VERSION "HNNBNNNYNNNNNNNNNNNNNNNNNNNNNNNNNNNNNNNNNN/4/%%%/4/'%**4NNN///"

NS_ :

BS_:

BU_: BAP_Tester BedienDisp_vo BedienSG_hi CGS DDA Gateway Gateway_PAG GurtMikrofon OTA_FC ZR_High ZR_LIMU ZR_MIB_TOP_ab_Gen3 ZR_Standard

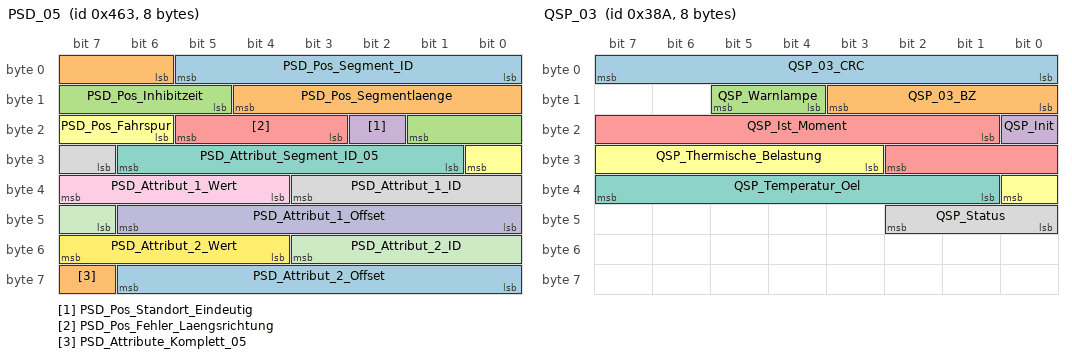
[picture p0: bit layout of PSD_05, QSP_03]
BO_ 1123 PSD_05: 8 ZR_High
 SG_ PSD_Pos_Segment_ID : 0|6@1+ (1,0) [2|63] ""  Gateway,Gateway_PAG
 SG_ PSD_Pos_Segmentlaenge : 6|7@1+ (2,0) [0|254] "Unit_Meter"  Gateway,Gateway_PAG
 SG_ PSD_Pos_Inhibitzeit : 13|5@1+ (10,0) [0|310] "Unit_MilliSecon"  Gateway,Gateway_PAG
 SG_ PSD_Pos_Standort_Eindeutig : 18|1@1+ (1.0,0.0) [0.0|1] ""  Gateway,Gateway_PAG
 SG_ PSD_Pos_Fehler_Laengsrichtung : 19|3@1+ (1.0,0.0) [0.0|7] ""  Gateway,Gateway_PAG
 SG_ PSD_Pos_Fahrspur : 22|3@1+ (1.0,0.0) [0.0|7] ""  Gateway,Gateway_PAG,OTA_FC
 SG_ PSD_Attribut_Segment_ID_05 : 25|6@1+ (1,0) [2|63] ""  Gateway,Gateway_PAG
 SG_ PSD_Attribut_1_ID : 31|5@1+ (1,0) [1|31] ""  Gateway,Gateway_PAG
 SG_ PSD_Attribut_1_Wert : 36|4@1+ (1.0,0.0) [0.0|15] ""  Gateway,Gateway_PAG
 SG_ PSD_Attribut_1_Offset : 40|7@1+ (2,0) [0|254] "Unit_Meter"  Gateway,Gateway_PAG
 SG_ PSD_Attribut_2_ID : 47|5@1+ (1,0) [1|31] ""  Gateway,Gateway_PAG
 SG_ PSD_Attribut_2_Wert : 52|4@1+ (1.0,0.0) [0.0|15] ""  Gateway,Gateway_PAG
 SG_ PSD_Attribut_2_Offset : 56|7@1+ (2,0) [0|254] "Unit_Meter"  Gateway,Gateway_PAG
 SG_ PSD_Attribute_Komplett_05 : 63|1@1+ (1.0,0.0) [0.0|1] ""  Gateway,Gateway_PAG

BO_ 1124 PSD_06: 8 ZR_High
 SG_ PSD_06_Mux M  : 0|3@1+ (1.0,0.0) [0.0|7] ""  Gateway,Gateway_PAG
 SG_ PSD_Sys_Segment_ID m0  : 3|6@1+ (1,0) [2|63] ""  Gateway,Gateway_PAG
 SG_ PSD_Attribut_Segment_ID m1  : 3|6@1+ (1,0) [2|63] ""  Gateway,Gateway_PAG
 SG_ PSD_Ges_Segment_ID m2  : 3|6@1+ (1,0) [2|63] ""  Gateway,Gateway_PAG
 SG_ PSD_Baum_Laenge_VZ m3  : 3|1@1+ (1.0,0.0) [0.0|1] ""  Gateway,Gateway_PAG
 SG_ PSD_Steigung_1_Segment_ID m4  : 3|6@1+ (1,0) [2|63] ""  Gateway,Gateway_PAG
 SG_ PSD_Baum_Laenge m3  : 4|25@1+ (0.00001,0) [0.00000|180.00000] "Unit_DegreOfArc"  Gateway,Gateway_PAG
 SG_ PSD_Sys_Laendercode m0  : 9|8@1+ (1.0,0.0) [0.0|255] ""  Gateway,Gateway_PAG
 SG_ PSD_Attribut_3_ID m1  : 9|5@1+ (1,0) [1|31] ""  Gateway,Gateway_PAG
 SG_ PSD_Ges_Offset m2  : 9|7@1+ (2,0) [0|254] "Unit_Meter"  Gateway,Gateway_PAG
 SG_ PSD_Steigung_1_A_Steigung m4  : 9|7@1+ (0.12,0) [0.00|15.00] "Unit_PerCent"  Gateway,Gateway_PAG
 SG_ PSD_Attribut_3_Offset m1  : 14|7@1+ (2,0) [0|254] "Unit_Meter"  Gateway,Gateway_PAG
 SG_ PSD_Ges_Geschwindigkeit m2  : 16|5@1+ (1.0,0.0) [0.0|31] ""  Gateway,Gateway_PAG,OTA_FC
 SG_ PSD_Steigung_1_A_Vorz m4  : 16|1@1+ (1.0,0.0) [0.0|1] ""  Gateway,Gateway_PAG
 SG_ PSD_Sys_Geschwindigkeit_Einheit m0  : 17|1@1+ (1.0,0.0) [0.0|1] ""  Gateway,Gateway_PAG
 SG_ PSD_Steigung_1_A_Offset m4  : 17|7@1+ (2,0) [0|254] "Unit_Meter"  Gateway,Gateway_PAG
 SG_ PSD_Sys_Verkehrsrichtung m0  : 18|1@1+ (1.0,0.0) [0.0|1] ""  Gateway,Gateway_PAG
 SG_ PSD_Sys_Geometrieguete m0  : 19|2@1+ (1.0,0.0) [0.0|3] ""  Gateway,Gateway_PAG
 SG_ PSD_Sys_Mapmatchingguete m0  : 21|2@1+ (1.0,0.0) [0.0|3] ""  Gateway,Gateway_PAG
 SG_ PSD_Attribut_3_Wert m1  : 21|4@1+ (1.0,0.0) [0.0|15] ""  Gateway,Gateway_PAG
 SG_ PSD_Ges_Typ m2  : 21|2@1+ (1.0,0.0) [0.0|3] ""  Gateway,Gateway_PAG
 SG_ PSD_Sys_Alter_Karte m0  : 23|3@1+ (1.0,0.0) [0.0|7] ""  Gateway,Gateway_PAG
 SG_ PSD_Ges_Spur_Geschw_Begrenzung m2  : 23|6@1+ (1.0,0.0) [0.0|63] ""  Gateway,Gateway_PAG
 SG_ PSD_Steigung_1_B_Steigung m4  : 24|7@1+ (0.12,0) [0.00|15.00] "Unit_PerCent"  Gateway,Gateway_PAG
 SG_ PSD_Attribut_4_ID m1  : 25|5@1+ (1,0) [1|31] ""  Gateway,Gateway_PAG
 SG_ PSD_Sys_Zielfuehrung m0  : 26|1@1+ (1.0,0.0) [0.0|1] ""  Gateway,Gateway_PAG,OTA_FC
 SG_ PSD_Sys_US_State m0  : 27|6@1+ (1.0,0.0) [0.0|63] ""  Gateway,Gateway_PAG
 SG_ PSD_Ges_Geschwindigkeit_Gespann m2  : 29|2@1+ (1.0,0.0) [0.0|3] ""  Gateway,Gateway_PAG
 SG_ PSD_Baum_Breite_VZ m3  : 29|1@1+ (1.0,0.0) [0.0|1] ""  Gateway,Gateway_PAG
 SG_ PSD_Attribut_4_Wert m1  : 30|4@1+ (1,0) [0|15] ""  Gateway,Gateway_PAG
 SG_ PSD_Baum_Breite m3  : 30|24@1+ (0.00001,0) [0.00000|90.00000] "Unit_DegreOfArc"  Gateway,Gateway_PAG
 SG_ PSD_Ges_Geschwindigkeit_Witter m2  : 31|2@1+ (1.0,0.0) [0.0|3] ""  Gateway,Gateway_PAG
 SG_ PSD_Steigung_1_B_Vorz m4  : 31|1@1+ (1.0,0.0) [0.0|1] ""  Gateway,Gateway_PAG
 SG_ PSD_Steigung_1_B_Offset m4  : 32|7@1+ (2,0) [0|254] "Unit_Meter"  Gateway,Gateway_PAG
 SG_ PSD_Sys_Quali_Geometrien m0  : 33|3@1+ (1,0) [0|7] "Unit_None"  Gateway,Gateway_PAG
 SG_ PSD_Ges_Geschwindigkeit_Tag_Anf m2  : 33|3@1+ (1.0,0.0) [0.0|7] ""  Gateway,Gateway_PAG
 SG_ PSD_Attribut_4_Offset m1  : 34|7@1+ (2,0) [0|254] "Unit_Meter"  Gateway,Gateway_PAG
 SG_ PSD_Sys_Quali_Ortsinfo m0  : 36|2@1+ (1,0) [0|3] "Unit_None"  Gateway,Gateway_PAG
 SG_ PSD_Ges_Geschwindigkeit_Tag_Ende m2  : 36|3@1+ (1.0,0.0) [0.0|7] ""  Gateway,Gateway_PAG
 SG_ PSD_Sys_Quali_verfuegbar m0  : 38|1@1+ (1.0,0.0) [0.0|1] ""  Gateway,Gateway_PAG
 SG_ PSD_Sys_Zielfuehrung_geaendert m0  : 39|1@1+ (1.0,0.0) [0.0|1] ""  Gateway,Gateway_PAG
 SG_ PSD_Ges_Geschwindigkeit_Std_Anf m2  : 39|5@1+ (1,0) [0|24] "Unit_Hours"  Gateway,Gateway_PAG
 SG_ PSD_Steigung_1_Attribute_kompl m4  : 39|1@1+ (1.0,0.0) [0.0|1] ""  Gateway,Gateway_PAG
 SG_ PSD_Sys_Geometrieguete_erweitert m0  : 40|8@1+ (1.0,0.0) [0.0|255] ""  Gateway,Gateway_PAG
 SG_ PSD_Steigung_2_Segment_ID m4  : 40|6@1+ (1,0) [2|63] ""  Gateway,Gateway_PAG
 SG_ PSD_Attribut_5_ID m1  : 41|5@1+ (1,0) [1|31] ""  Gateway,Gateway_PAG
 SG_ PSD_Ges_Geschwindigkeit_Std_Ende m2  : 44|5@1+ (1,0) [0|24] "Unit_Hours"  Gateway,Gateway_PAG
 SG_ PSD_Attribut_5_Offset m1  : 46|7@1+ (2,0) [0|254] "Unit_Meter"  Gateway,Gateway_PAG
 SG_ PSD_Steigung_2_Steigung m4  : 46|7@1+ (0.12,0) [0.00|15.00] "Unit_PerCent"  Gateway,Gateway_PAG
 SG_ PSD_Sys_Quali_sonstige_Attribute m0  : 48|3@1+ (1,0) [0|7] "Unit_None"  Gateway,Gateway_PAG
 SG_ PSD_Ges_Ueberholverbot m2  : 49|2@1+ (1.0,0.0) [0.0|3] ""  Gateway,Gateway_PAG
 SG_ PSD_Sys_Quali_Steigungen m0  : 51|3@1+ (1,0) [0|7] ""  Gateway,Gateway_PAG
 SG_ PSD_Ges_Wechselverkehrszeichen m2  : 51|3@1+ (1.0,0.0) [0.0|7] ""  Gateway,Gateway_PAG
 SG_ PSD_Attribut_5_Wert m1  : 53|4@1+ (1,0) [0|15] ""  Gateway,Gateway_PAG
 SG_ PSD_Steigung_2_Vorz m4  : 53|1@1+ (1.0,0.0) [0.0|1] ""  Gateway,Gateway_PAG
 SG_ PSD_Sys_Quali_Strassenkennz m0  : 54|3@1+ (1,0) [0|7] "Unit_None"  Gateway,Gateway_PAG
 SG_ PSD_Wechselverkehrszeichen_Typ m2  : 54|2@1+ (1.0,0.0) [0.0|3] ""  Gateway,Gateway_PAG
 SG_ PSD_Baum_Ausrichtung m3  : 54|10@1+ (0.3515625,0) [0E-7|359.6484375] "Unit_DegreOfArc"  Gateway,Gateway_PAG
 SG_ PSD_Steigung_2_Offset m4  : 54|7@1+ (2,0) [0|254] "Unit_Meter"  Gateway,Gateway_PAG
 SG_ PSD_Ges_Gesetzlich_Kategorie m2  : 56|3@1+ (1.0,0.0) [0.0|7] ""  Gateway,Gateway_PAG
 SG_ PSD_Sys_Quali_Tempolimits m0  : 57|3@1+ (1,0) [0|7] "Unit_None"  Gateway,Gateway_PAG
 SG_ PSD_Attribute_Komplett_06 m1  : 57|1@1+ (1.0,0.0) [0.0|1] ""  Gateway,Gateway_PAG
 SG_ PSD_Ges_Gesetzlich_Zusatz m2  : 59|2@1+ (1.0,0.0) [0.0|3] ""  Gateway,Gateway_PAG
 SG_ PSD_Sys_Quali_Vorfahrtsregelung m0  : 60|3@1+ (1,0) [0|7] "Unit_None"  Gateway,Gateway_PAG
 SG_ PSD_Ges_Verkehrszeichen_Quelle m2  : 61|2@1+ (1.0,0.0) [0.0|3] ""  Gateway,Gateway_PAG
 SG_ PSD_Steigung_2_Attribute_kompl m4  : 61|1@1+ (1.0,0.0) [0.0|1] ""  Gateway,Gateway_PAG
 SG_ PSD_Ges_Attribute_Komplett m2  : 63|1@1+ (1.0,0.0) [0.0|1] ""  Gateway,Gateway_PAG

BO_ 1125 PSD_LR_01: 8 ZR_High
 SG_ PSD_LR_Profil_Nummer : 0|2@1+ (1,0) [0|3] ""  Gateway,Gateway_PAG
 SG_ PSD_LR_01_MUX M  : 2|2@1+ (1.0,0.0) [0.0|3] ""  Gateway,Gateway_PAG
 SG_ PSD_LR_Profil_Laenge m0  : 4|14@1+ (0.25,0) [0.00|4095.75] "Unit_KiloMeter"  Gateway,Gateway_PAG
 SG_ PSD_LR_Koeffizientensatz_Nr m1  : 4|6@1+ (1,0) [0|63] ""  Gateway,Gateway_PAG
 SG_ PSD_LR_Attribut_1_Offset m2  : 4|12@1+ (0.0244140625,0) [0E-10|99.9755859375] "Unit_PerCent"  Gateway,Gateway_PAG
 SG_ PSD_LR_Steigung_1_Offset m3  : 4|12@1+ (0.0244140625,0) [0E-10|99.9755859375] "Unit_PerCent"  Gateway,Gateway_PAG
 SG_ PSD_LR_Koeff_1_Amp m1  : 10|9@1+ (0.01956947162,0) [0E-11|9.99999999782] "Unit_PerCent"  Gateway,Gateway_PAG
 SG_ PSD_LR_Attribut_1_Wert m2  : 16|8@1+ (1.0,0.0) [0.0|255] ""  Gateway,Gateway_PAG
 SG_ PSD_LR_Steigung_1_Vorz m3  : 16|1@1+ (1.0,0.0) [0.0|1] ""  Gateway,Gateway_PAG
 SG_ PSD_LR_Steigung_1_Wert m3  : 17|7@1+ (0.12,0) [0.00|15.24] "Unit_PerCent"  Gateway,Gateway_PAG
 SG_ PSD_LR_Fahrzeug_Pos m0  : 18|14@1+ (0.006103888,0) [0E-9|99.999997104] "Unit_PerCent"  Gateway,Gateway_PAG
 SG_ PSD_LR_Koeff_1_Phase m1  : 19|9@1+ (0.0122958616,0) [0E-10|6.2831852776] "Unit_DegreOfArc"  Gateway,Gateway_PAG
 SG_ PSD_LR_Attribut_2_Offset m2  : 24|12@1+ (0.0244140625,0) [0E-10|99.9755859375] "Unit_PerCent"  Gateway,Gateway_PAG
 SG_ PSD_LR_Steigung_2_Offset m3  : 24|12@1+ (0.0244140625,0) [0E-10|99.9755859375] "Unit_PerCent"  Gateway,Gateway_PAG
 SG_ PSD_LR_Koeff_2_Amp m1  : 28|9@1+ (0.01956947162,0) [0E-11|9.99999999782] "Unit_PerCent"  Gateway,Gateway_PAG
 SG_ PSD_LR_Globale_Steigung_Vorz m0  : 32|1@1+ (1.0,0.0) [0.0|1] ""  Gateway,Gateway_PAG
 SG_ PSD_LR_Globale_Steigung m0  : 33|19@1+ (0.00002861028406197,0) [0E-17|14.99999999999806539] "Unit_PerCent"  Gateway,Gateway_PAG
 SG_ PSD_LR_Attribut_2_Wert m2  : 36|8@1+ (1.0,0.0) [0.0|255] ""  Gateway,Gateway_PAG
 SG_ PSD_LR_Steigung_2_Vorz m3  : 36|1@1+ (1.0,0.0) [0.0|1] ""  Gateway,Gateway_PAG
 SG_ PSD_LR_Koeff_2_Phase m1  : 37|9@1+ (0.0122958616,0) [0E-10|6.2831852776] "Unit_DegreOfArc"  Gateway,Gateway_PAG
 SG_ PSD_LR_Steigung_2_Wert m3  : 37|7@1+ (0.12,0) [0.00|15.24] "Unit_PerCent"  Gateway,Gateway_PAG
 SG_ PSD_LR_Attribut_3_Offset m2  : 44|12@1+ (0.0244140625,0) [0E-10|99.9755859375] "Unit_PerCent"  Gateway,Gateway_PAG
 SG_ PSD_LR_Steigung_3_Offset m3  : 44|12@1+ (0.0244140625,0) [0E-10|99.9755859375] "Unit_PerCent"  Gateway,Gateway_PAG
 SG_ PSD_LR_Koeff_3_Amp m1  : 46|9@1+ (0.01956947162,0) [0E-11|9.99999999782] "Unit_PerCent"  Gateway,Gateway_PAG
 SG_ PSD_LR_Max_Koeff_Amp m0  : 52|11@1+ (2,0) [0|4094] "Unit_Meter"  Gateway,Gateway_PAG
 SG_ PSD_LR_Koeff_3_Phase m1  : 55|9@1+ (0.0122958616,0) [0E-10|6.2831852776] "Unit_DegreOfArc"  Gateway,Gateway_PAG
 SG_ PSD_LR_Attribut_3_Wert m2  : 56|8@1+ (1.0,0.0) [0.0|255] ""  Gateway,Gateway_PAG
 SG_ PSD_LR_Steigung_3_Vorz m3  : 56|1@1+ (1.0,0.0) [0.0|1] ""  Gateway,Gateway_PAG
 SG_ PSD_LR_Steigung_3_Wert m3  : 57|7@1+ (0.12,0) [0.00|15.24] "Unit_PerCent"  Gateway,Gateway_PAG
 SG_ PSD_LR_Reset m0  : 63|1@1+ (1.0,0.0) [0.0|1] ""  Gateway,Gateway_PAG

BO_ 906 QSP_03: 8 Gateway
 SG_ QSP_03_CRC : 0|8@1+ (1,0) [0|255] ""  Vector__XXX
 SG_ QSP_03_BZ : 8|4@1+ (1,0) [0|15] ""  Vector__XXX
 SG_ QSP_Warnlampe : 12|2@1+ (1.0,0.0) [0.0|3] ""  ZR_High,ZR_MIB_TOP_ab_Gen3
 SG_ QSP_Init : 16|1@1+ (1.0,0.0) [0.0|1] ""  Vector__XXX
 SG_ QSP_Ist_Moment : 17|10@1+ (3,-1533) [-1533|1533] "Unit_NewtoMeter"  Vector__XXX
 SG_ QSP_Thermische_Belastung : 27|6@1+ (2,0) [0|100] "Unit_PerCent"  ZR_High,ZR_MIB_TOP_ab_Gen3
 SG_ QSP_Temperatur_Oel : 33|7@1+ (2,-40) [-40|210] "Unit_DegreCelsi"  ZR_High,ZR_MIB_TOP_ab_Gen3
 SG_ QSP_Status : 40|3@1+ (1.0,0.0) [0.0|7] ""  Vector__XXX

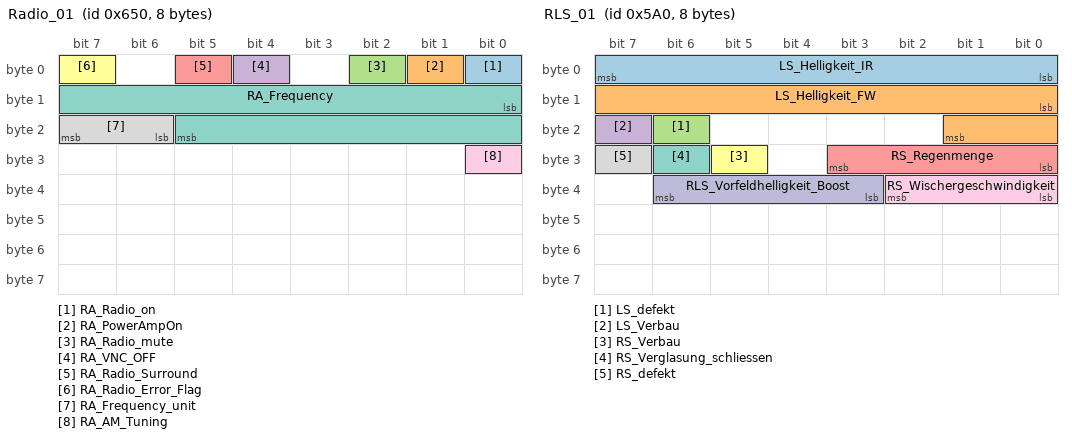
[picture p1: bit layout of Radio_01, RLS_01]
BO_ 1616 Radio_01: 8 ZR_High
 SG_ RA_Radio_on : 0|1@1+ (1,0) [0|1] ""  Gateway,Gateway_PAG
 SG_ RA_PowerAmpOn : 1|1@1+ (1,0) [0|1] ""  Gateway,Gateway_PAG
 SG_ RA_Radio_mute : 2|1@1+ (1,0) [0|1] ""  Gateway,Gateway_PAG
 SG_ RA_VNC_OFF : 4|1@1+ (1,0) [0|1] ""  Gateway,Gateway_PAG
 SG_ RA_Radio_Surround : 5|1@1+ (1,0) [0|1] ""  Gateway,Gateway_PAG
 SG_ RA_Radio_Error_Flag : 7|1@1+ (1.0,0.0) [0.0|1] ""  Gateway,Gateway_PAG
 SG_ RA_Frequency : 8|14@1+ (1,0) [0|16383] "Unit_None"  Gateway,Gateway_PAG
 SG_ RA_Frequency_unit : 22|2@1+ (1.0,0.0) [0.0|3] ""  Gateway,Gateway_PAG
 SG_ RA_AM_Tuning : 24|1@1+ (1.0,0.0) [0.0|1] ""  Gateway,Gateway_PAG

BO_ 1529 RDK_02: 8 Gateway
 SG_ RDK_FMVSS138_Lampe : 12|1@1+ (1.0,0.0) [0.0|1] ""  ZR_High
 SG_ RDK_FMVSS138_MIL : 13|1@1+ (1.0,0.0) [0.0|1] ""  ZR_High
 SG_ RDK_Kalibrierung : 14|1@1+ (1.0,0.0) [0.0|1] ""  Vector__XXX
 SG_ RDK_Reifendruck_Lampe : 15|1@1+ (1.0,0.0) [0.0|1] ""  OTA_FC,ZR_High
 SG_ RDK_Warnungen_02 : 16|5@1+ (1.0,0.0) [0.0|31] ""  ZR_High
 SG_ RDK_angelernt : 22|1@1+ (1.0,0.0) [0.0|1] ""  Vector__XXX
 SG_ RDK_Reifentemperatur_Lampe : 23|1@1+ (1.0,0.0) [0.0|1] ""  ZR_High
 SG_ RDK_RS_aktiv : 24|1@1+ (1.0,0.0) [0.0|1] ""  Vector__XXX
 SG_ RDK_Text_7 : 25|1@1+ (1.0,0.0) [0.0|1] ""  Vector__XXX
 SG_ RDK_W_1_Reifen_HL : 56|1@1+ (1.0,0.0) [0.0|1] ""  ZR_High
 SG_ RDK_W_1_Reifen_HR : 57|1@1+ (1.0,0.0) [0.0|1] ""  ZR_High
 SG_ RDK_W_1_Reifen_VL : 58|1@1+ (1.0,0.0) [0.0|1] ""  ZR_High
 SG_ RDK_W_1_Reifen_VR : 59|1@1+ (1.0,0.0) [0.0|1] ""  ZR_High
 SG_ RDK_W_2_Reifen_HL : 60|1@1+ (1.0,0.0) [0.0|1] ""  ZR_High
 SG_ RDK_W_2_Reifen_HR : 61|1@1+ (1.0,0.0) [0.0|1] ""  ZR_High
 SG_ RDK_W_2_Reifen_VL : 62|1@1+ (1.0,0.0) [0.0|1] ""  ZR_High
 SG_ RDK_W_2_Reifen_VR : 63|1@1+ (1.0,0.0) [0.0|1] ""  ZR_High

BO_ 1711 Rear_View_01: 8 Gateway
 SG_ RV_Video_on : 0|1@1+ (1.0,0.0) [0.0|1] ""  ZR_High,ZR_Standard
 SG_ RV_Dark_Screen : 1|1@1+ (1.0,0.0) [0.0|1] ""  ZR_High,ZR_Standard
 SG_ RV_HMI_Mode : 2|2@1+ (1.0,0.0) [0.0|3] ""  ZR_High,ZR_Standard
 SG_ RV_GL_side : 4|2@1+ (1.0,0.0) [0.0|3] ""  ZR_High,ZR_Standard
 SG_ RV_System_aktiv : 6|1@1+ (1.0,0.0) [0.0|1] ""  ZR_High,ZR_Standard
 SG_ RV_Reinigung_Anf : 7|1@1+ (1.0,0.0) [0.0|1] ""  OTA_FC,ZR_High
 SG_ RV_Settings_enabled : 8|1@1+ (1.0,0.0) [0.0|1] ""  ZR_High
 SG_ RV_Menu_Item : 9|2@1+ (1.0,0.0) [0.0|3] ""  ZR_High
 SG_ SV_Video_on : 11|1@1+ (1.0,0.0) [0.0|1] ""  ZR_High,ZR_Standard
 SG_ RV_Calib_Fehler : 12|1@1+ (1.0,0.0) [0.0|1] ""  ZR_High
 SG_ RV_GL_Trailer_connect : 13|1@1+ (1.0,0.0) [0.0|1] ""  ZR_High,ZR_Standard
 SG_ RV_GL_Trunk_open : 14|1@1+ (1.0,0.0) [0.0|1] ""  ZR_High,ZR_Standard
 SG_ RV_GL_LWS_Fehler : 15|1@1+ (1.0,0.0) [0.0|1] ""  ZR_High
 SG_ RV_Helligkeit : 16|7@1+ (1,0) [0|100] "Unit_PerCent"  ZR_High,ZR_Standard
 SG_ ZFAS_Umfeldbeleuchtung_Anf : 23|1@1+ (1.0,0.0) [0.0|1] ""  Vector__XXX
 SG_ RV_Kontrast : 24|7@1+ (1,0) [0|100] "Unit_PerCent"  ZR_High,ZR_Standard
 SG_ RV_Farbe : 32|7@1+ (1,0) [0|100] "Unit_PerCent"  ZR_High,ZR_Standard

BO_ 1440 RLS_01: 8 Gateway
 SG_ LS_Helligkeit_IR : 0|8@1+ (400,0) [0|101200] "Unit_Lux"  ZR_High
 SG_ LS_Helligkeit_FW : 8|10@1+ (6,0) [0|6126] "Unit_Lux"  ZR_High
 SG_ LS_defekt : 22|1@1+ (1.0,0.0) [0.0|1] ""  ZR_High
 SG_ LS_Verbau : 23|1@1+ (1.0,0.0) [0.0|1] ""  ZR_High
 SG_ RS_Regenmenge : 24|4@1+ (10,0) [0|100] "Unit_PerCent"  OTA_FC,ZR_High
 SG_ RS_Verbau : 29|1@1+ (1.0,0.0) [0.0|1] ""  ZR_High
 SG_ RS_Verglasung_schliessen : 30|1@1+ (1.0,0.0) [0.0|1] ""  ZR_High
 SG_ RS_defekt : 31|1@1+ (1.0,0.0) [0.0|1] ""  ZR_High
 SG_ RS_Wischergeschwindigkeit : 32|3@1+ (1.0,0.0) [0.0|7] ""  OTA_FC,ZR_High
 SG_ RLS_Vorfeldhelligkeit_Boost : 35|4@1+ (1.0,0.0) [0.0|15] ""  ZR_High

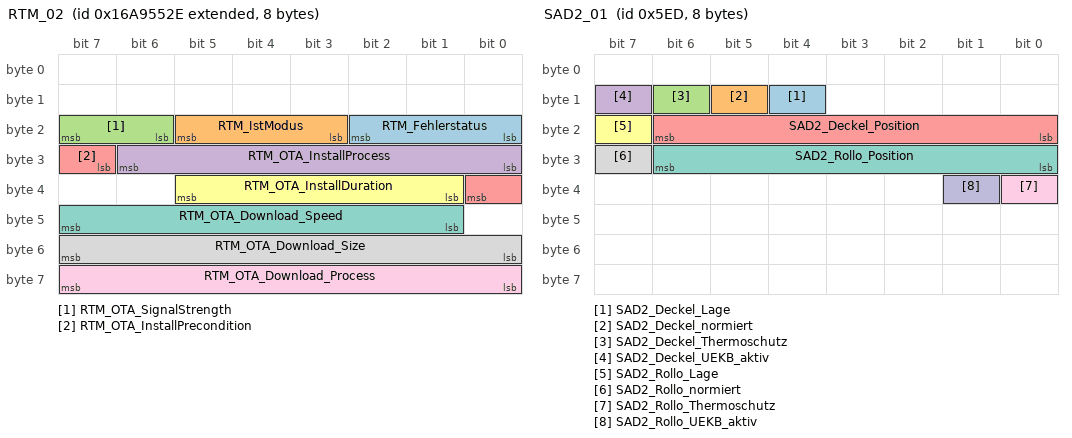
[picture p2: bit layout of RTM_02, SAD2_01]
BO_ 2527679790 RTM_02: 8 Gateway
 SG_ RTM_Fehlerstatus : 16|3@1+ (1.0,0.0) [0.0|7] ""  ZR_LIMU,ZR_MIB_TOP_ab_Gen3
 SG_ RTM_IstModus : 19|3@1+ (1.0,0.0) [0.0|7] ""  ZR_LIMU,ZR_MIB_TOP_ab_Gen3
 SG_ RTM_OTA_SignalStrength : 22|2@1+ (1.0,0.0) [0.0|3] ""  ZR_LIMU,ZR_MIB_TOP_ab_Gen3
 SG_ RTM_OTA_InstallProcess : 24|7@1+ (1,-1) [0|100] "Unit_PerCent"  ZR_LIMU,ZR_MIB_TOP_ab_Gen3
 SG_ RTM_OTA_InstallPrecondition : 31|2@1+ (1.0,0.0) [0.0|3] ""  ZR_LIMU,ZR_MIB_TOP_ab_Gen3
 SG_ RTM_OTA_InstallDuration : 33|5@1+ (1,0) [1|30] "Unit_Minut"  ZR_LIMU,ZR_MIB_TOP_ab_Gen3
 SG_ RTM_OTA_Download_Speed : 41|7@1+ (0.1,0) [0.1|12.5] ""  ZR_LIMU,ZR_MIB_TOP_ab_Gen3
 SG_ RTM_OTA_Download_Size : 48|8@1+ (1,1) [1|253] ""  ZR_LIMU,ZR_MIB_TOP_ab_Gen3
 SG_ RTM_OTA_Download_Process : 56|8@1+ (0.5,0) [0.0|100.0] "Unit_PerCent"  ZR_LIMU,ZR_MIB_TOP_ab_Gen3

BO_ 2527679791 RTM_03: 8 Gateway
 SG_ RTM_03_Dummy : 63|1@1+ (1.0,0.0) [0.0|1] ""  Vector__XXX

BO_ 2527679792 RTM_04: 8 ZR_LIMU
 SG_ MIB_OTA_Comfirmation : 12|3@1+ (1.0,0.0) [0.0|7] ""  Gateway,Gateway_PAG

BO_ 1517 SAD2_01: 8 Gateway
 SG_ SAD2_Deckel_Lage : 12|1@1+ (1.0,0.0) [0.0|1] ""  DDA
 SG_ SAD2_Deckel_normiert : 13|1@1+ (1.0,0.0) [0.0|1] ""  Vector__XXX
 SG_ SAD2_Deckel_Thermoschutz : 14|1@1+ (1.0,0.0) [0.0|1] ""  Vector__XXX
 SG_ SAD2_Deckel_UEKB_aktiv : 15|1@1+ (1.0,0.0) [0.0|1] ""  Vector__XXX
 SG_ SAD2_Deckel_Position : 16|7@1+ (1,0) [0|100] "Unit_PerCent"  DDA,OTA_FC
 SG_ SAD2_Rollo_Lage : 23|1@1+ (1.0,0.0) [0.0|1] ""  Vector__XXX
 SG_ SAD2_Rollo_Position : 24|7@1+ (1,0) [0|100] "Unit_PerCent"  Vector__XXX
 SG_ SAD2_Rollo_normiert : 31|1@1+ (1.0,0.0) [0.0|1] ""  Vector__XXX
 SG_ SAD2_Rollo_Thermoschutz : 32|1@1+ (1.0,0.0) [0.0|1] ""  Vector__XXX
 SG_ SAD2_Rollo_UEKB_aktiv : 33|1@1+ (1.0,0.0) [0.0|1] ""  Vector__XXX

BO_ 1504 SAD_01: 8 Gateway
 SG_ MD1_Position : 8|7@1+ (1,0) [0|100] "Unit_PerCent"  BedienDisp_vo,BedienSG_hi,DDA,OTA_FC,ZR_High,ZR_LIMU,ZR_MIB_TOP_ab_Gen3,ZR_Standard
 SG_ MD1_Lage : 15|1@1+ (1.0,0.0) [0.0|1] ""  BedienDisp_vo,BedienSG_hi,DDA,OTA_FC,ZR_High,ZR_LIMU,ZR_MIB_TOP_ab_Gen3,ZR_Standard
 SG_ MD3_Position : 16|7@1+ (1,0) [0|100] "Unit_PerCent"  BedienSG_hi,ZR_High,ZR_LIMU,ZR_MIB_TOP_ab_Gen3,ZR_Standard
 SG_ MD3_Lage : 23|1@1+ (1.0,0.0) [0.0|1] ""  BedienSG_hi,ZR_High,ZR_LIMU,ZR_MIB_TOP_ab_Gen3,ZR_Standard
 SG_ MRollo_Position : 24|7@1+ (1,0) [0|100] "Unit_PerCent"  BedienSG_hi,ZR_High
 SG_ MRollo_Lage : 31|1@1+ (1.0,0.0) [0.0|1] ""  BedienSG_hi,ZR_High
 SG_ SAD_normiert : 32|1@1+ (1.0,0.0) [0.0|1] ""  BedienSG_hi,ZR_High
 SG_ SAD_Thermoschutz : 33|1@1+ (1.0,0.0) [0.0|1] ""  BedienSG_hi,ZR_High
 SG_ SAD_UEKB_aktiv : 34|1@1+ (1.0,0.0) [0.0|1] ""  BedienSG_hi,ZR_High
 SG_ Rollo_normiert : 35|1@1+ (1.0,0.0) [0.0|1] ""  BedienSG_hi,ZR_High
 SG_ Rollo_Thermoschutz : 36|1@1+ (1.0,0.0) [0.0|1] ""  BedienSG_hi,ZR_High
 SG_ Rollo_UEKB_aktiv : 37|1@1+ (1.0,0.0) [0.0|1] ""  BedienSG_hi,ZR_High
 SG_ SAD_Taster_Deckel_hi : 38|4@1+ (1.0,0.0) [0.0|15] ""  ZR_High
 SG_ SAD_Taster_Deckel_vo : 42|4@1+ (1.0,0.0) [0.0|15] ""  ZR_High
 SG_ SAD_Taster_Rollo_hi : 46|3@1+ (1.0,0.0) [0.0|7] ""  ZR_High
 SG_ SAD_Taster_Rollo_vo : 49|3@1+ (1.0,0.0) [0.0|7] ""  Vector__XXX
 SG_ SAD_Anf_ESC_Zuschaltung : 52|1@1+ (1.0,0.0) [0.0|1] ""  Vector__XXX
 SG_ SAD_Text : 53|1@1+ (1.0,0.0) [0.0|1] ""  Vector__XXX
 SG_ SAD_ToggleBit : 54|1@1+ (1,0) [0|1] ""  Vector__XXX
 SG_ SAD_ParityBit : 55|1@1+ (1,0) [0|1] ""  Vector__XXX

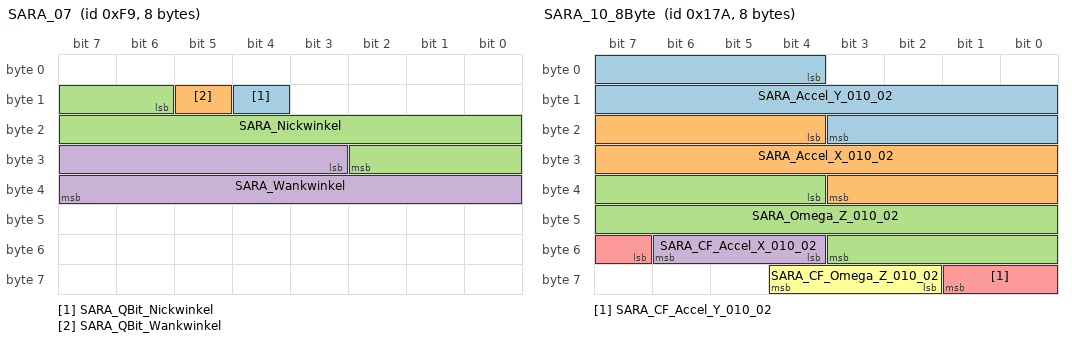
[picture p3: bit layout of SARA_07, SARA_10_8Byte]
BO_ 249 SARA_07: 8 Gateway
 SG_ SARA_QBit_Nickwinkel : 12|1@1+ (1.0,0.0) [0.0|1] ""  ZR_High,ZR_LIMU,ZR_MIB_TOP_ab_Gen3
 SG_ SARA_QBit_Wankwinkel : 13|1@1+ (1.0,0.0) [0.0|1] ""  ZR_High,ZR_LIMU,ZR_MIB_TOP_ab_Gen3
 SG_ SARA_Nickwinkel : 14|13@1+ (0.025,-102.3) [-102.300|102.450] "Unit_DegreOfArc"  ZR_High,ZR_LIMU,ZR_MIB_TOP_ab_Gen3
 SG_ SARA_Wankwinkel : 27|13@1+ (0.025,-102.3) [-102.300|102.450] "Unit_DegreOfArc"  ZR_High,ZR_LIMU,ZR_MIB_TOP_ab_Gen3

BO_ 378 SARA_10_8Byte: 8 Gateway
 SG_ SARA_Accel_Y_010_02 : 4|16@1+ (0.02,-655.36) [-655.34|655.32] "Unit_MeterPerSeconSquar"  ZR_High,ZR_LIMU,ZR_MIB_TOP_ab_Gen3
 SG_ SARA_Accel_X_010_02 : 20|16@1+ (0.02,-655.36) [-655.34|655.32] "Unit_MeterPerSeconSquar"  ZR_High,ZR_LIMU,ZR_MIB_TOP_ab_Gen3
 SG_ SARA_Omega_Z_010_02 : 36|16@1+ (0.01,-327.68) [-327.67|327.66] "Unit_DegreOfArcPerSecon"  ZR_LIMU,ZR_MIB_TOP_ab_Gen3
 SG_ SARA_CF_Accel_X_010_02 : 52|3@1+ (1.0,0.0) [0.0|7] ""  ZR_High,ZR_LIMU,ZR_MIB_TOP_ab_Gen3
 SG_ SARA_CF_Accel_Y_010_02 : 55|3@1+ (1.0,0.0) [0.0|7] ""  ZR_High,ZR_LIMU,ZR_MIB_TOP_ab_Gen3
 SG_ SARA_CF_Omega_Z_010_02 : 58|3@1+ (1.0,0.0) [0.0|7] ""  ZR_LIMU,ZR_MIB_TOP_ab_Gen3

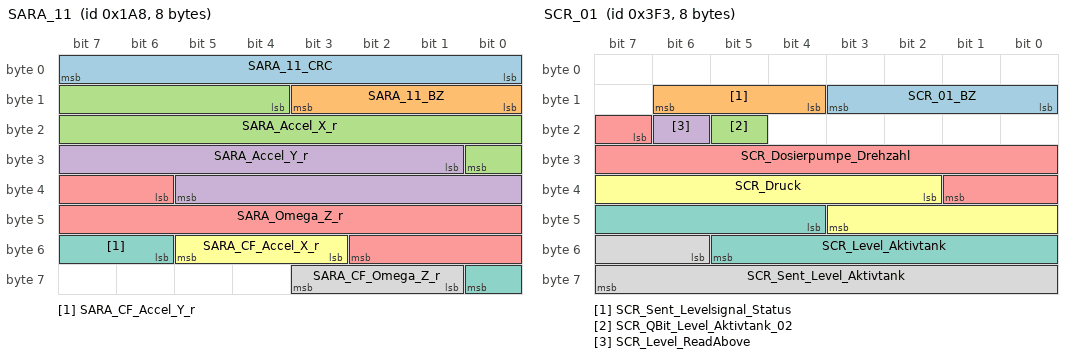
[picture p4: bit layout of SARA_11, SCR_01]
BO_ 424 SARA_11: 8 Gateway
 SG_ SARA_11_CRC : 0|8@1+ (1,0) [0|255] ""  Vector__XXX
 SG_ SARA_11_BZ : 8|4@1+ (1,0) [0|15] ""  Vector__XXX
 SG_ SARA_Accel_X_r : 12|13@1+ (0.16,-655.36) [-655.20|655.04] "Unit_MeterPerSeconSquar"  OTA_FC,ZR_High,ZR_LIMU,ZR_MIB_TOP_ab_Gen3,ZR_Standard
 SG_ SARA_Accel_Y_r : 25|13@1+ (0.16,-655.36) [-655.20|655.04] "Unit_MeterPerSeconSquar"  OTA_FC,ZR_High,ZR_LIMU,ZR_MIB_TOP_ab_Gen3,ZR_Standard
 SG_ SARA_Omega_Z_r : 38|13@1+ (0.08,-327.68) [-327.60|327.52] "Unit_DegreOfArcPerSecon"  ZR_High,ZR_LIMU,ZR_MIB_TOP_ab_Gen3,ZR_Standard
 SG_ SARA_CF_Accel_X_r : 51|3@1+ (1.0,0.0) [0.0|7] ""  ZR_High,ZR_LIMU,ZR_MIB_TOP_ab_Gen3,ZR_Standard
 SG_ SARA_CF_Accel_Y_r : 54|3@1+ (1.0,0.0) [0.0|7] ""  ZR_High,ZR_LIMU,ZR_MIB_TOP_ab_Gen3,ZR_Standard
 SG_ SARA_CF_Omega_Z_r : 57|3@1+ (1.0,0.0) [0.0|7] ""  ZR_High,ZR_LIMU,ZR_MIB_TOP_ab_Gen3,ZR_Standard

BO_ 1011 SCR_01: 8 Gateway
 SG_ SCR_01_BZ : 8|4@1+ (1,0) [0|15] ""  Vector__XXX
 SG_ SCR_Sent_Levelsignal_Status : 12|3@1+ (1.0,0.0) [0.0|7] ""  ZR_High
 SG_ SCR_QBit_Level_Aktivtank_02 : 21|1@1+ (1.0,0.0) [0.0|1] ""  Vector__XXX
 SG_ SCR_Level_ReadAbove : 22|1@1+ (1.0,0.0) [0.0|1] ""  Vector__XXX
 SG_ SCR_Dosierpumpe_Drehzahl : 23|11@1+ (4,-4080) [-4080|4100] "Unit_MinutInver"  Vector__XXX
 SG_ SCR_Druck : 34|10@1+ (5,0) [0|5000] "Unit_MilliVolt"  ZR_High
 SG_ SCR_Level_Aktivtank : 44|10@1+ (5,0) [0|5000] "Unit_MilliVolt"  ZR_High
 SG_ SCR_Sent_Level_Aktivtank : 54|10@1+ (1,-20) [-20|1000] "Unit_MilliMeter"  ZR_High

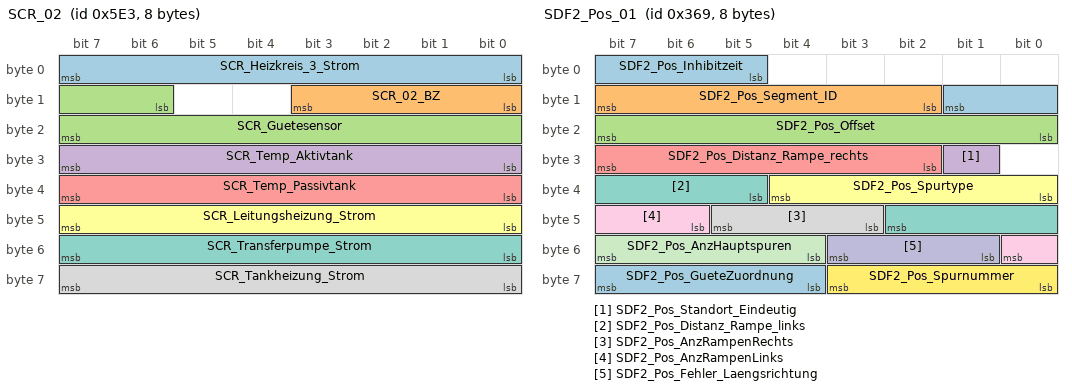
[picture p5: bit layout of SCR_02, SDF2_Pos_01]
BO_ 1507 SCR_02: 8 Gateway
 SG_ SCR_Heizkreis_3_Strom : 0|8@1+ (0.1,0) [0.0|14.0] "Unit_Amper"  Vector__XXX
 SG_ SCR_02_BZ : 8|4@1+ (1,0) [0|15] ""  Vector__XXX
 SG_ SCR_Guetesensor : 14|10@1+ (5,0) [0|5000] "Unit_MilliVolt"  Vector__XXX
 SG_ SCR_Temp_Aktivtank : 24|8@1+ (20,0) [0|5000] "Unit_MilliVolt"  ZR_High
 SG_ SCR_Temp_Passivtank : 32|8@1+ (20,0) [0|5000] "Unit_MilliVolt"  Vector__XXX
 SG_ SCR_Leitungsheizung_Strom : 40|8@1+ (0.1,0) [0.0|14.0] "Unit_Amper"  Vector__XXX
 SG_ SCR_Transferpumpe_Strom : 48|8@1+ (0.1,0) [0.0|14.0] "Unit_Amper"  Vector__XXX
 SG_ SCR_Tankheizung_Strom : 56|8@1+ (0.1,0) [0.0|14.0] "Unit_Amper"  Vector__XXX

BO_ 1526 SCR_05: 8 Gateway
 SG_ SCR_05_BZ : 8|4@1+ (1,0) [0|15] ""  Vector__XXX
 SG_ SCR_Level_Aktivtank_OOR4Quality : 12|1@1+ (1.0,0.0) [0.0|1] ""  ZR_High
 SG_ SCR_Level_Aktivtank_OOR_minus : 13|1@1+ (1.0,0.0) [0.0|1] ""  ZR_High
 SG_ SCR_Sent_1_Signalstatus : 14|2@1+ (1.0,0.0) [0.0|3] ""  ZR_High
 SG_ SCR_Sent_1_elektrischer_Status : 16|4@1+ (1.0,0.0) [0.0|15] ""  ZR_High
 SG_ SCR_Sent_Levelsensor : 20|3@1+ (1.0,0.0) [0.0|7] ""  ZR_High
 SG_ SCR_Sent_Qualitaetssensor : 23|3@1+ (1.0,0.0) [0.0|7] ""  ZR_High
 SG_ SCR_Sent_Temperatursensor : 26|3@1+ (1.0,0.0) [0.0|7] ""  ZR_High
 SG_ SCR_DEF_Qualitaet_Medium : 29|1@1+ (1.0,0.0) [0.0|1] ""  ZR_High
 SG_ SCR_QBit_Qualitaet : 30|1@1+ (1.0,0.0) [0.0|1] ""  Vector__XXX
 SG_ SCR_Sent_2_Signalstatus : 31|2@1+ (1.0,0.0) [0.0|3] ""  Vector__XXX
 SG_ SCR_Temp_DEF2_Sensor_Status : 33|3@1+ (1.0,0.0) [0.0|7] ""  ZR_High
 SG_ SCR_Sent_2_elektrischer_Status : 36|4@1+ (1.0,0.0) [0.0|15] ""  ZR_High
 SG_ SCR_HAL_Sensorik_Status : 40|4@1+ (1.0,0.0) [0.0|15] ""  ZR_High
 SG_ SCR_Steuergeraet_Heizung_Status : 48|2@1+ (1.0,0.0) [0.0|3] ""  ZR_High
 SG_ SCR_Steuergeraet_Pumpe_Status : 50|2@1+ (1.0,0.0) [0.0|3] ""  ZR_High
 SG_ SCR_Steuergeraet_Relais_Status : 52|2@1+ (1.0,0.0) [0.0|3] ""  ZR_High
 SG_ SCR_Steuergeraet_Bus_Status : 56|2@1+ (1.0,0.0) [0.0|3] ""  ZR_High
 SG_ SCR_ECU_Datensatz_Status : 60|2@1+ (1.0,0.0) [0.0|3] ""  ZR_High
 SG_ SCR_Steuergeraet_Defekt_Status : 62|2@1+ (1.0,0.0) [0.0|3] ""  ZR_High

BO_ 873 SDF2_Pos_01: 8 Gateway
 SG_ SDF2_Pos_Inhibitzeit : 5|5@1+ (10,0) [0|310] "Unit_MilliSecon"  ZR_High,ZR_LIMU,ZR_MIB_TOP_ab_Gen3
 SG_ SDF2_Pos_Segment_ID : 10|6@1+ (1,0) [2|63] ""  ZR_High,ZR_LIMU,ZR_MIB_TOP_ab_Gen3
 SG_ SDF2_Pos_Offset : 16|8@1+ (1,0) [0|254] "Unit_Meter"  ZR_High,ZR_LIMU,ZR_MIB_TOP_ab_Gen3
 SG_ SDF2_Pos_Standort_Eindeutig : 25|1@1+ (1.0,0.0) [0.0|1] ""  ZR_High,ZR_LIMU,ZR_MIB_TOP_ab_Gen3
 SG_ SDF2_Pos_Distanz_Rampe_rechts : 26|6@1+ (16,0) [0|976] "Unit_Meter"  ZR_High,ZR_LIMU,ZR_MIB_TOP_ab_Gen3
 SG_ SDF2_Pos_Spurtype : 32|5@1+ (1.0,0.0) [0.0|31] ""  ZR_High,ZR_LIMU,ZR_MIB_TOP_ab_Gen3
 SG_ SDF2_Pos_Distanz_Rampe_links : 37|6@1+ (16,0) [0|976] "Unit_Meter"  ZR_High,ZR_LIMU,ZR_MIB_TOP_ab_Gen3
 SG_ SDF2_Pos_AnzRampenRechts : 43|3@1+ (1,0) [0|6] ""  ZR_High,ZR_LIMU,ZR_MIB_TOP_ab_Gen3
 SG_ SDF2_Pos_AnzRampenLinks : 46|3@1+ (1,0) [0|6] ""  ZR_High,ZR_LIMU,ZR_MIB_TOP_ab_Gen3
 SG_ SDF2_Pos_Fehler_Laengsrichtung : 49|3@1+ (1.0,0.0) [0.0|7] ""  ZR_High,ZR_LIMU,ZR_MIB_TOP_ab_Gen3
 SG_ SDF2_Pos_AnzHauptspuren : 52|4@1+ (1,0) [0|14] ""  ZR_High,ZR_LIMU,ZR_MIB_TOP_ab_Gen3
 SG_ SDF2_Pos_Spurnummer : 56|4@1+ (1.0,0.0) [0.0|15] ""  ZR_High,ZR_LIMU,ZR_MIB_TOP_ab_Gen3
 SG_ SDF2_Pos_GueteZuordnung : 60|4@1+ (0.0714285714,0) [0E-10|0.9999999996] ""  ZR_High,ZR_LIMU,ZR_MIB_TOP_ab_Gen3

BO_ 2589283634 SM_LAPP_01: 8 DDA
 SG_ SM_LAPP_Demo_Distanz_01 : 0|8@1+ (2,0) [0|500] "Unit_Meter"  Gateway,Gateway_PAG
 SG_ SM_LAPP_Demo_Distanz_02 : 8|8@1+ (2,0) [0|500] "Unit_Meter"  Gateway,Gateway_PAG
 SG_ SM_LAPP_Demo_Winkel_Vert_01 : 16|8@1+ (0.1,-12.8) [-12.8|12.7] "Unit_DegreOfArc"  Gateway,Gateway_PAG
 SG_ SM_LAPP_Demo_Winkel_Vert_02 : 24|8@1+ (0.1,-12.8) [-12.8|12.7] "Unit_DegreOfArc"  Gateway,Gateway_PAG
 SG_ SM_LAPP_Demo_Winkel_Hor_01 : 32|10@1+ (0.0625,-32) [-32.0000|31.9375] "Unit_DegreOfArc"  Gateway,Gateway_PAG
 SG_ SM_LAPP_Demo_Winkel_Hor_02 : 42|10@1+ (0.0625,-32) [-32.0000|31.9375] "Unit_DegreOfArc"  Gateway,Gateway_PAG
 SG_ SM_LAPP_Demo_Objekt_01_Anf : 52|1@1+ (1.0,0.0) [0.0|1] ""  Gateway,Gateway_PAG
 SG_ SM_LAPP_Demo_Objekt_02_Anf : 53|1@1+ (1.0,0.0) [0.0|1] ""  Gateway,Gateway_PAG
 SG_ SM_LAPP_Demo_Autobahnmodus_Anf : 54|1@1+ (1.0,0.0) [0.0|1] ""  Gateway,Gateway_PAG
 SG_ SM_LAPP_Aussenlicht_aktiv : 55|1@1+ (1.0,0.0) [0.0|1] ""  Gateway,Gateway_PAG
 SG_ SM_LAPP_Verbindungsstatus : 56|1@1+ (1.0,0.0) [0.0|1] ""  Gateway,Gateway_PAG
 SG_ SM_LAPP_Demo_Schildentbl_01_Anf : 57|1@1+ (1.0,0.0) [0.0|1] ""  Gateway,Gateway_PAG
 SG_ SM_LAPP_Demo_Schildentbl_02_Anf : 58|1@1+ (1.0,0.0) [0.0|1] ""  Gateway,Gateway_PAG
 SG_ SM_LAPP_Demo_DKL_Anf : 59|1@1+ (1.0,0.0) [0.0|1] ""  Gateway,Gateway_PAG
 SG_ SM_LAPP_Demo_Einschalteffekt_Anf : 60|1@1+ (1.0,0.0) [0.0|1] ""  Gateway,Gateway_PAG
 SG_ SM_LAPP_Demo_FL_Anf : 61|1@1+ (1.0,0.0) [0.0|1] ""  Gateway,Gateway_PAG
 SG_ SM_LAPP_Demo_MaLi_Anf : 62|1@1+ (1.0,0.0) [0.0|1] ""  Gateway,Gateway_PAG
 SG_ SM_LAPP_Demo_ABBL_Anf : 63|1@1+ (1.0,0.0) [0.0|1] ""  Gateway,Gateway_PAG

BO_ 2527679657 SM_LAPP_02: 8 DDA
 SG_ SM_LAPP_Demo_AbsAss_Anf : 12|1@1+ (1.0,0.0) [0.0|1] ""  Gateway,Gateway_PAG
 SG_ SM_LAPP_Demo_SL_Signatur_Anf : 28|4@1+ (1.0,0.0) [0.0|15] ""  Gateway,Gateway_PAG
 SG_ SM_LAPP_Demo_Variante : 32|4@1+ (1.0,0.0) [0.0|15] ""  Gateway,Gateway_PAG
 SG_ SM_LAPP_Demo_RouLi_Anf : 36|1@1+ (1.0,0.0) [0.0|1] ""  Gateway,Gateway_PAG
 SG_ SM_LAPP_Demo_PreSAss_Anf : 37|1@1+ (1.0,0.0) [0.0|1] ""  Gateway,Gateway_PAG
 SG_ SM_LAPP_Demo_advLH_F01_Anf : 38|1@1+ (1.0,0.0) [0.0|1] ""  Gateway,Gateway_PAG
 SG_ SM_LAPP_Demo_AbbiegeWa_Anf : 39|1@1+ (1.0,0.0) [0.0|1] ""  Gateway,Gateway_PAG
 SG_ SM_LAPP_Demo_CH_H01_Anf : 40|1@1+ (1.0,0.0) [0.0|1] ""  Gateway,Gateway_PAG
 SG_ SM_LAPP_Demo_Stufe : 41|2@1+ (1.0,0.0) [0.0|3] ""  Gateway,Gateway_PAG
 SG_ SM_LAPP_Demo_SL_Anf : 44|1@1+ (1.0,0.0) [0.0|1] ""  Gateway,Gateway_PAG
 SG_ SM_LAPP_Demo_SitLi_Anf : 45|1@1+ (1.0,0.0) [0.0|1] ""  Gateway,Gateway_PAG
 SG_ SM_LAPP_Demo_BauLi_Anf : 46|1@1+ (1.0,0.0) [0.0|1] ""  Gateway,Gateway_PAG
 SG_ SM_LAPP_Demo_advCH_F01_Anf : 47|1@1+ (1.0,0.0) [0.0|1] ""  Gateway,Gateway_PAG
 SG_ SM_LAPP_Demo_LH_F01_Anf : 48|5@1+ (1,0) [1|31] "Unit_None"  Gateway,Gateway_PAG
 SG_ SM_LAPP_Demo_AccAss_Anf : 53|1@1+ (1.0,0.0) [0.0|1] ""  Gateway,Gateway_PAG
 SG_ SM_LAPP_Demo_SpuLi_Anf : 54|1@1+ (1.0,0.0) [0.0|1] ""  Gateway,Gateway_PAG
 SG_ SM_LAPP_Demo_TraLi_Anf : 55|1@1+ (1.0,0.0) [0.0|1] ""  Gateway,Gateway_PAG
 SG_ SM_LAPP_Demo_CH_F01_Anf : 56|5@1+ (1,0) [1|31] "Unit_None"  Gateway,Gateway_PAG
 SG_ SM_LAPP_Demo_LH_H01_Anf : 61|1@1+ (1.0,0.0) [0.0|1] ""  Gateway,Gateway_PAG
 SG_ SM_LAPP_Demo_EffAss_Anf : 62|1@1+ (1.0,0.0) [0.0|1] ""  Gateway,Gateway_PAG
 SG_ SM_LAPP_Demo_BeAss_Anf : 63|1@1+ (1.0,0.0) [0.0|1] ""  Gateway,Gateway_PAG

BO_ 201 SM_Parken_01: 8 DDA
 SG_ SM_Parken_Touch_PosX : 0|3@1+ (1.0,0.0) [0.0|7] ""  Gateway,Gateway_PAG
 SG_ SM_Parken_Touch_PosY : 3|5@1+ (1.0,0.0) [0.0|31] ""  Gateway,Gateway_PAG
 SG_ SM_ARA_Gangwahl : 8|3@1+ (1.0,0.0) [0.0|7] ""  Gateway,Gateway_PAG
 SG_ SM_Fehlerstatus : 11|1@1+ (1.0,0.0) [0.0|1] ""  Gateway,Gateway_PAG
 SG_ SM_ARA_Start : 12|1@1+ (1.0,0.0) [0.0|1] ""  Gateway,Gateway_PAG
 SG_ SM_ARA_Trajektorienmodus : 13|1@1+ (1.0,0.0) [0.0|1] ""  Gateway,Gateway_PAG
 SG_ SM_AFR_Verbindungsstatus : 14|1@1+ (1.0,0.0) [0.0|1] ""  Gateway,Gateway_PAG
 SG_ SM_Anlernstatus : 15|1@1+ (1.0,0.0) [0.0|1] ""  Gateway,Gateway_PAG
 SG_ SM_Parken_Motorstart_Anf : 23|1@1+ (1.0,0.0) [0.0|1] ""  Gateway,Gateway_PAG
 SG_ SM_AFR_Standfkt_Anf : 24|3@1+ (1.0,0.0) [0.0|7] ""  Gateway,Gateway_PAG
 SG_ SM_ARA_Nothalt : 27|1@1+ (1.0,0.0) [0.0|1] ""  Gateway,Gateway_PAG
 SG_ SM_App_Sperrzustand : 28|2@1+ (1.0,0.0) [0.0|3] ""  Gateway,Gateway_PAG
 SG_ SM_Parken_Manoever : 30|2@1+ (1.0,0.0) [0.0|3] ""  Gateway,Gateway_PAG,ZR_High
 SG_ SM_Parken_Szenario : 32|3@1+ (1.0,0.0) [0.0|7] ""  Gateway,Gateway_PAG,ZR_High
 SG_ SM_Parken_Seite : 35|2@1+ (1.0,0.0) [0.0|3] ""  Gateway,Gateway_PAG,ZR_High
 SG_ SM_Parken_Richtung : 37|2@1+ (1.0,0.0) [0.0|3] ""  Gateway,Gateway_PAG,ZR_High
 SG_ SM_ARA_Status_Steuersignal : 39|1@1+ (1.0,0.0) [0.0|1] ""  Gateway,Gateway_PAG
 SG_ SM_ARA_Knickwinkel_Soll : 40|8@1+ (1,-127) [-127|124] "Unit_DegreOfArc"  Gateway,Gateway_PAG
 SG_ SM_ARA_Gaspedal : 48|4@1+ (1,0) [0|15] "Unit_None"  Gateway,Gateway_PAG
 SG_ SM_Parken_Verbindungsstatus : 52|4@1+ (1.0,0.0) [0.0|15] ""  Gateway,Gateway_PAG,ZR_High
 SG_ SM_Parken_Kommando : 56|2@1+ (1.0,0.0) [0.0|3] ""  Gateway,Gateway_PAG,ZR_High
 SG_ SM_Parken_Alive : 58|4@1+ (1,0) [0|15] "Unit_None"  Gateway,Gateway_PAG
 SG_ SM_Parken_Kommando_invers : 62|2@1+ (1.0,0.0) [0.0|3] ""  Gateway,Gateway_PAG

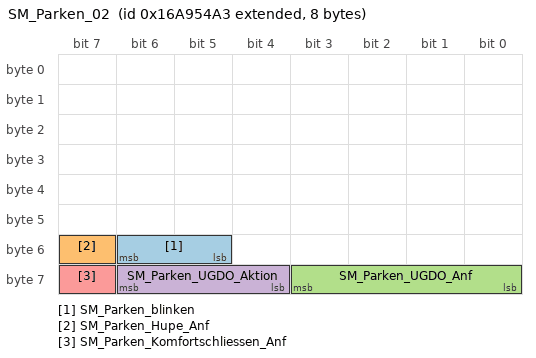
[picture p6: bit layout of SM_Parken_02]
BO_ 2527679651 SM_Parken_02: 8 DDA
 SG_ SM_Parken_blinken : 53|2@1+ (1.0,0.0) [0.0|3] ""  Gateway,Gateway_PAG
 SG_ SM_Parken_Hupe_Anf : 55|1@1+ (1.0,0.0) [0.0|1] ""  Gateway,Gateway_PAG,ZR_High
 SG_ SM_Parken_UGDO_Anf : 56|4@1+ (1.0,0.0) [0.0|15] ""  Gateway,Gateway_PAG,ZR_High
 SG_ SM_Parken_UGDO_Aktion : 60|3@1+ (1.0,0.0) [0.0|7] ""  Gateway,Gateway_PAG,ZR_High
 SG_ SM_Parken_Komfortschliessen_Anf : 63|1@1+ (1.0,0.0) [0.0|1] ""  Gateway,Gateway_PAG,ZR_High

BO_ 980 SMLS_01: 8 Gateway
 SG_ SMLS_01_CRC : 0|8@1+ (1,0) [0|255] ""  Vector__XXX
 SG_ SMLS_01_BZ : 8|4@1+ (1,0) [0|15] ""  Vector__XXX
 SG_ BH_Blinker_li : 12|1@1+ (1.0,0.0) [0.0|1] ""  ZR_High,ZR_Standard
 SG_ BH_Blinker_re : 13|1@1+ (1.0,0.0) [0.0|1] ""  ZR_High,ZR_Standard
 SG_ BH_Lichthupe : 14|1@1+ (1.0,0.0) [0.0|1] ""  ZR_High
 SG_ BH_Fernlicht : 15|1@1+ (1.0,0.0) [0.0|1] ""  ZR_High
 SG_ WH_Tipwischen : 16|1@1+ (1.0,0.0) [0.0|1] ""  ZR_High
 SG_ WH_Intervall : 17|1@1+ (1.0,0.0) [0.0|1] ""  ZR_High
 SG_ WH_WischerStufe1 : 18|1@1+ (1.0,0.0) [0.0|1] ""  ZR_High
 SG_ WH_WischerStufe2 : 19|1@1+ (1.0,0.0) [0.0|1] ""  ZR_High
 SG_ WH_Frontwaschen : 20|1@1+ (1.0,0.0) [0.0|1] ""  ZR_High
 SG_ WH_Heckintervall : 21|1@1+ (1.0,0.0) [0.0|1] ""  ZR_High
 SG_ WH_Heckwaschen : 22|1@1+ (1.0,0.0) [0.0|1] ""  ZR_High
 SG_ WH_Intervallstufen : 23|4@1+ (1.0,0.0) [0.0|15] ""  ZR_High
 SG_ FAS_Taster : 27|1@1+ (1.0,0.0) [0.0|1] ""  ZR_High,ZR_Standard
 SG_ FAS_Taster_Fehler : 28|1@1+ (1.0,0.0) [0.0|1] ""  ZR_High
 SG_ SMLS_Hupe : 29|1@1+ (1.0,0.0) [0.0|1] ""  Vector__XXX
 SG_ LRH_On_Off : 30|2@1+ (1.0,0.0) [0.0|3] ""  ZR_High
 SG_ LRH_aktiv : 40|1@1+ (1.0,0.0) [0.0|1] ""  ZR_High
 SG_ SMLS_P_verriegelt_plausibel : 43|1@1+ (1.0,0.0) [0.0|1] ""  Vector__XXX
 SG_ WH_SRA : 44|1@1+ (1.0,0.0) [0.0|1] ""  OTA_FC,ZR_High
 SG_ WH_Wischer_Fehler : 45|1@1+ (1.0,0.0) [0.0|1] ""  ZR_High
 SG_ BH_Blinker_Fehler : 46|1@1+ (1.0,0.0) [0.0|1] ""  ZR_High
 SG_ SMLS_PTT : 47|1@1+ (1.0,0.0) [0.0|1] ""  ZR_High,ZR_LIMU,ZR_MIB_TOP_ab_Gen3,ZR_Standard
 SG_ WH_Tipwischen_lang : 48|1@1+ (1.0,0.0) [0.0|1] ""  ZR_High

BO_ 1467 SoSe_01: 8 Gateway
 SG_ SoSe_SunInt_2D_Li : 0|8@1+ (5,0) [0|1200] "Unit_WattPerMeterSquar"  ZR_High
 SG_ SoSe_SunInt_2D_Re : 8|8@1+ (5,0) [0|1200] "Unit_WattPerMeterSquar"  ZR_High

BO_ 1710 Spiegel_01: 8 Gateway
 SG_ SP_FT_oben : 0|1@1+ (1.0,0.0) [0.0|1] ""  OTA_FC,ZR_High
 SG_ SP_FT_unten : 1|1@1+ (1.0,0.0) [0.0|1] ""  OTA_FC,ZR_High
 SG_ SP_FT_links : 2|1@1+ (1.0,0.0) [0.0|1] ""  OTA_FC,ZR_High
 SG_ SP_FT_rechts : 3|1@1+ (1.0,0.0) [0.0|1] ""  OTA_FC,ZR_High
 SG_ SP_BT_oben : 4|1@1+ (1.0,0.0) [0.0|1] ""  OTA_FC,ZR_High
 SG_ SP_BT_unten : 5|1@1+ (1.0,0.0) [0.0|1] ""  OTA_FC,ZR_High
 SG_ SP_BT_links : 6|1@1+ (1.0,0.0) [0.0|1] ""  OTA_FC,ZR_High
 SG_ SP_BT_rechts : 7|1@1+ (1.0,0.0) [0.0|1] ""  OTA_FC,ZR_High
 SG_ SP_abklappen : 8|1@1+ (1.0,0.0) [0.0|1] ""  OTA_FC,ZR_High
 SG_ SP_anklappen : 9|1@1+ (1.0,0.0) [0.0|1] ""  OTA_FC,ZR_High
 SG_ SP_normieren : 10|1@1+ (1.0,0.0) [0.0|1] ""  OTA_FC,ZR_High
 SG_ SP_Hzg_Taster : 12|1@1+ (1.0,0.0) [0.0|1] ""  OTA_FC,ZR_High
 SG_ SP_S_oben : 16|1@1+ (1.0,0.0) [0.0|1] ""  ZR_High
 SG_ SP_S_unten : 17|1@1+ (1.0,0.0) [0.0|1] ""  ZR_High
 SG_ SP_S_links : 18|1@1+ (1.0,0.0) [0.0|1] ""  ZR_High
 SG_ SP_S_rechts : 19|1@1+ (1.0,0.0) [0.0|1] ""  ZR_High
 SG_ SP_Auswahl_li : 20|1@1+ (1.0,0.0) [0.0|1] ""  ZR_High
 SG_ SP_Auswahl_re : 21|1@1+ (1.0,0.0) [0.0|1] ""  ZR_High
 SG_ SP_ARA_Status : 22|1@1+ (1.0,0.0) [0.0|1] ""  ZR_High
 SG_ SP_S_Klappen : 23|1@1+ (1.0,0.0) [0.0|1] ""  ZR_High
 SG_ SP_Verstellschalter_Fehler : 24|1@1+ (1.0,0.0) [0.0|1] ""  ZR_High

BO_TX_BU_ 1123 :ZR_High,ZR_LIMU,ZR_MIB_TOP_ab_Gen3,ZR_Standard;
BO_TX_BU_ 1124 :ZR_High,ZR_LIMU,ZR_MIB_TOP_ab_Gen3,ZR_Standard;
BO_TX_BU_ 1125 :ZR_High,ZR_LIMU,ZR_MIB_TOP_ab_Gen3,ZR_Standard;
BO_TX_BU_ 906 :Gateway,Gateway_PAG;
BO_TX_BU_ 1616 :ZR_High,ZR_LIMU,ZR_MIB_TOP_ab_Gen3,ZR_Standard;
BO_TX_BU_ 1529 :Gateway,Gateway_PAG;
BO_TX_BU_ 1711 :Gateway,Gateway_PAG;
BO_TX_BU_ 1440 :Gateway,Gateway_PAG;
BO_TX_BU_ 2527679790 :Gateway,Gateway_PAG;
BO_TX_BU_ 2527679791 :Gateway,Gateway_PAG;
BO_TX_BU_ 2527679792 :ZR_LIMU,ZR_MIB_TOP_ab_Gen3;
BO_TX_BU_ 1517 :Gateway,Gateway_PAG;
BO_TX_BU_ 1504 :Gateway,Gateway_PAG;
BO_TX_BU_ 249 :Gateway,Gateway_PAG;
BO_TX_BU_ 378 :Gateway,Gateway_PAG;
BO_TX_BU_ 424 :Gateway,Gateway_PAG;
BO_TX_BU_ 1011 :Gateway,Gateway_PAG;
BO_TX_BU_ 1507 :Gateway,Gateway_PAG;
BO_TX_BU_ 1526 :Gateway,Gateway_PAG;
BO_TX_BU_ 873 :Gateway,Gateway_PAG;
BO_TX_BU_ 980 :Gateway,Gateway_PAG;
BO_TX_BU_ 1467 :Gateway,Gateway_PAG;
BO_TX_BU_ 1710 :Gateway,Gateway_PAG;
CM_ BO_ 1529 "MQB";
CM_ BO_ 1440 "8Byte ab MLBevo
LIN-CAN (1:1) Botschaften werden geroutet
-  wenn entsprechender Slave codiert ist
-  wenn fehlerfreie Kommunikation zum Slave besteht
-  bei fehlerhafter Kommunikation zum Slave wird die Botschaft für 4s mit den letzten gültigen Werte";
CM_ BO_ 1517 "


";
CM_ BO_ 1504 "MLBevo 8Byte
LIN-CAN (1:1) Botschaft wird geroutet:
- wenn entsprechender Slave codiert ist
- wenn fehlerfreie Kommunikation zum Slave besteht
- bei fehlerhafter Kommunikation zum Slave wird die Botschaft für 4s mit den letzten gültigen Werten versend";
CM_ BO_ 424 "CAN-Botschaft";
CM_ BO_ 980 "Ab MQB 7.2";
CM_ BO_ 1710 "MLBevo 8Byte";

CM_ SG_ 1123 PSD_Attribut_1_ID "Identifier des ersten Attributes";
CM_ SG_ 1123 PSD_Attribut_1_Offset "Positionsoffset im Segment für die Position des Attributs";
CM_ SG_ 1123 PSD_Attribut_1_Wert "Wert des ersten Attributes";
CM_ SG_ 1123 PSD_Attribut_2_ID "Identifier des zweiten Attributes";
CM_ SG_ 1123 PSD_Attribut_2_Offset "Positionsoffset im Segment für die Position des Attributs";
CM_ SG_ 1123 PSD_Attribut_2_Wert "Wert des zweiten Attributes";
CM_ SG_ 1123 PSD_Attribut_Segment_ID_05 "Identifier des Streckensegments, für das die weiteren Attribute in der Botschaft gültig sind";
CM_ SG_ 1123 PSD_Attribute_Komplett_05 "Zeigt, ob alle Attribute für das Segment übertragen worden sind";
CM_ SG_ 1123 PSD_Pos_Fahrspur "Spur, auf der sich das Fahrzeug aktuell befindet";
CM_ SG_ 1123 PSD_Pos_Fehler_Laengsrichtung "Laengsfehler der Positionierung";
CM_ SG_ 1123 PSD_Pos_Inhibitzeit "Zeitspanne zwischen Generierung der PSD Daten im Navigationssystem und Versand der Daten auf den Most
";
CM_ SG_ 1123 PSD_Pos_Segment_ID "Identifier des Streckensegments, auf dem sich das Fahrzeug aktuell befindet
";
CM_ SG_ 1123 PSD_Pos_Segmentlaenge "Verbleibende Länge des Streckensegments, auf dem sich das Fahrzeug aktuell befindet
";
CM_ SG_ 1123 PSD_Pos_Standort_Eindeutig "Ist die Position des Fahrzeugs eindeutig dem aktuelle Segment zugeordnet, oder gibt es fahrbare alternative Segmente, die bei akteller GPS-Position ebenfalls als aktuelles Segment möglich wären.";

CM_ SG_ 1124 PSD_06_Mux "Multiplex Zähler für die PSD_06-Botschaft.
Die unterschiedlichen Muxe folgen keiner festen Reihenfolge. Je nach Inhalt des PSD-Protokolls an der aktuellen Position werden jeweils die notwendigen PSD6-Botschaften gesendet.";
CM_ SG_ 1124 PSD_Attribut_3_ID "Identifier des dritten Attributes";
CM_ SG_ 1124 PSD_Attribut_3_Offset "Positionsoffset im Segment für die Position des Attributs";
CM_ SG_ 1124 PSD_Attribut_3_Wert "Wert des dritten Attributes";
CM_ SG_ 1124 PSD_Attribut_4_ID "Typ von Attribut 4";
CM_ SG_ 1124 PSD_Attribut_4_Offset "Offset von Attribut 4";
CM_ SG_ 1124 PSD_Attribut_4_Wert "Wert von Attribut 4";
CM_ SG_ 1124 PSD_Attribut_5_ID "Typ von Attribut 5";
CM_ SG_ 1124 PSD_Attribut_5_Offset "Offset von Attribut 5";
CM_ SG_ 1124 PSD_Attribut_5_Wert "Wert von Attribut 5";
CM_ SG_ 1124 PSD_Attribut_Segment_ID "Identifier des Streckensegments,für das die weiteren Attribute in der Botschaft gültig sind";
CM_ SG_ 1124 PSD_Attribute_Komplett_06 "Zeigt, ob alle Attribute für das Segment übertragen worden sind
";
CM_ SG_ 1124 PSD_Baum_Ausrichtung "Ausrichtung des Fahrzeugsegments zu Nord";
CM_ SG_ 1124 PSD_Baum_Breite "WGS84 Breite des Fahrzeugsegments";
CM_ SG_ 1124 PSD_Baum_Breite_VZ "Vorzeichen WGS84 Breite des Fahrzeugsegments";
CM_ SG_ 1124 PSD_Baum_Laenge "WGS84 Laenge des Fahrzeugsegments";
CM_ SG_ 1124 PSD_Baum_Laenge_VZ "Vorzeichen WGS84 Laenge des Fahrzeugsegments";
CM_ SG_ 1124 PSD_Ges_Attribute_Komplett "Zeigt, ob alle Attribute für das Segment übertragen worden sind";
CM_ SG_ 1124 PSD_Ges_Geschwindigkeit_Gespann "Gilt diese Einschränkung der Geschwindigkeit für alle Fahrzeuge oder ausschließlich für PKW mit Gespann oder für LKW, Buss, etc.";
CM_ SG_ 1124 PSD_Ges_Geschwindigkeit_Std_Anf "Stunde, zu der die stündliche Geschwindigkeitsbegrenzung beginnt
0h.. 24h";
CM_ SG_ 1124 PSD_Ges_Geschwindigkeit_Std_Ende "Stunde, an der die stündliche Geschwindigkeitsbegrenzung endet
0h.. 24h";
CM_ SG_ 1124 PSD_Ges_Geschwindigkeit_Tag_Anf "Wochentag, an dem die tägliche Geschwindigkeitsbegrenzung beginnt";
CM_ SG_ 1124 PSD_Ges_Geschwindigkeit_Tag_Ende "Wochentag, an dem die tägliche Geschwindigkeitsbegrenzung endet";
CM_ SG_ 1124 PSD_Ges_Geschwindigkeit_Witter "Witterungsabhängigkeit der Geschwindigkeitsbegrenzung";
CM_ SG_ 1124 PSD_Ges_Gesetzlich_Kategorie "Kategorie für das legale Gebot";
CM_ SG_ 1124 PSD_Ges_Gesetzlich_Zusatz "Zusatz für das legale Gebot";
CM_ SG_ 1124 PSD_Ges_Offset "Positionsoffset im Segment für die Position des Attributs";
CM_ SG_ 1124 PSD_Ges_Segment_ID "Identifier des prädiktiven Streckensegments ab dem die Geschwindigkeitsbegrenzungen und mögliche Einschränkungen gelten.
";
CM_ SG_ 1124 PSD_Ges_Spur_Geschw_Begrenzung "Definition der Spuren, für die das übertragene Gebot gilt";
CM_ SG_ 1124 PSD_Ges_Typ "Typ der Geschwindigkeitsbegrenzung
";
CM_ SG_ 1124 PSD_Ges_Verkehrszeichen_Quelle "Quelle der Verkehrszeicheninformation";
CM_ SG_ 1124 PSD_Ges_Wechselverkehrszeichen "Am Beginn des Segments ist ein Wechselverkehrszeichen angebracht.";
CM_ SG_ 1124 PSD_Steigung_1_A_Offset "Positionsoffset im Segment für die Position der Steigung 1 A";
CM_ SG_ 1124 PSD_Steigung_1_A_Steigung "Steigung des Segments ab Offset 1A";
CM_ SG_ 1124 PSD_Steigung_1_A_Vorz "Vorzeichen für Steigung 1 A";
CM_ SG_ 1124 PSD_Steigung_1_Attribute_kompl "Alle Steigungsdaten für dieses Segment gesendet";
CM_ SG_ 1124 PSD_Steigung_1_B_Offset "Positionsoffset im Segment für die Position der Steigung 1 B";
CM_ SG_ 1124 PSD_Steigung_1_B_Steigung "Steigung des Segments ab Offset 1B";
CM_ SG_ 1124 PSD_Steigung_1_B_Vorz "Vorzeichen für Steigung 1 B";
CM_ SG_ 1124 PSD_Steigung_1_Segment_ID "Identifier des prädiktiven Streckensegments, zu dem die  ersten beiden Steigungswerte dieser Botschaft gehören";
CM_ SG_ 1124 PSD_Steigung_2_Attribute_kompl "Alle Steigungsdaten für dieses Segment gesendet";
CM_ SG_ 1124 PSD_Steigung_2_Offset "Positionsoffset im Segment für die Position der Steigung 2";
CM_ SG_ 1124 PSD_Steigung_2_Segment_ID "Identifier des prädiktiven Streckensegments, zu dem der dritte Steigungswert dieser Botschaft gehört";
CM_ SG_ 1124 PSD_Steigung_2_Steigung "Steigung des Segments ab Offset 2";
CM_ SG_ 1124 PSD_Steigung_2_Vorz "Vorzeichen für Steigung 2";
CM_ SG_ 1124 PSD_Sys_Alter_Karte "Alter der Karte";
CM_ SG_ 1124 PSD_Sys_Geometrieguete "Maß für die Güte der Klothoidengeometrie.";
CM_ SG_ 1124 PSD_Sys_Geometrieguete_erweitert "Güte der Kurvenrepräsentation der Klothoiden";
CM_ SG_ 1124 PSD_Sys_Geschwindigkeit_Einheit "Unterscheidung zwischen km/h und miles/h";
CM_ SG_ 1124 PSD_Sys_Laendercode "Ländercode
";
CM_ SG_ 1124 PSD_Sys_Mapmatchingguete "Güte des Mapmatchings";
CM_ SG_ 1124 PSD_Sys_Quali_Geometrien "Qualität der Geometrien in dieser Region";
CM_ SG_ 1124 PSD_Sys_Quali_Ortsinfo "Qualität Ortsinformationen (Bebauung, Ortsschild) dieser Region";
CM_ SG_ 1124 PSD_Sys_Quali_sonstige_Attribute "Qualität sonstiger Attribute dieser Region";
CM_ SG_ 1124 PSD_Sys_Quali_Steigungen "Qualität der Steigungen dieser Region";
CM_ SG_ 1124 PSD_Sys_Quali_Strassenkennz "Qualität Straßenkennzeichnungen dieser Region";
CM_ SG_ 1124 PSD_Sys_Quali_Tempolimits "Qualität Tempolimits dieser Region";
CM_ SG_ 1124 PSD_Sys_Quali_verfuegbar "Karte enthält gültige Qualitätskriterien";
CM_ SG_ 1124 PSD_Sys_Quali_Vorfahrtsregelung "Qualität Vorfahrtsregelungen dieser Region";
CM_ SG_ 1124 PSD_Sys_Segment_ID "Identifier des prädiktiven Streckensegments ab dem die Systeminformationen gültig sind.
";
CM_ SG_ 1124 PSD_Sys_US_State "Name des USA-State";
CM_ SG_ 1124 PSD_Sys_Verkehrsrichtung "Unterscheidung zwischen Linksverkehr und Rechtsverkehr";
CM_ SG_ 1124 PSD_Sys_Zielfuehrung "Zielfuehrung im Navigationssystem. Damit lässt sich der wahrscheinlichste Pfad des Fahrzeuges zuverlässig angeben.";
CM_ SG_ 1124 PSD_Sys_Zielfuehrung_geaendert "Die Zielführung (Route) hat sich geändert hat ohne dass der Fahrer eine neue Zielführung gestartet hat";
CM_ SG_ 1124 PSD_Wechselverkehrszeichen_Typ "Typ des Wechselverkehrszeichen";

CM_ SG_ 1125 PSD_LR_01_MUX "Fehlende Beschreibung (Import)";
CM_ SG_ 1125 PSD_LR_Attribut_1_Offset "Relative Position für Attribut 1 im Profil.
Signal wird nur bei aktiver PSD-Funktion zyklisch gesendet.";
CM_ SG_ 1125 PSD_LR_Attribut_1_Wert "Wert von Attribut 1 (Definition siehe PSD Spec)
Signal wird nur bei aktiver PSD-Funktion zyklisch gesendet.";
CM_ SG_ 1125 PSD_LR_Attribut_2_Offset "Relative Position für Attribut 2 im Profil
Signal wird nur bei aktiver PSD-Funktion zyklisch gesendet.";
CM_ SG_ 1125 PSD_LR_Attribut_2_Wert "Wert von Attribut 2 (Definition siehe PSD Spec)
Signal wird nur bei aktiver PSD-Funktion zyklisch gesendet.";
CM_ SG_ 1125 PSD_LR_Attribut_3_Offset "Relative Position für Attribut 3 im Profil
Signal wird nur bei aktiver PSD-Funktion zyklisch gesendet.";
CM_ SG_ 1125 PSD_LR_Attribut_3_Wert "Wert von Attribut 3 (Definition siehe PSD Spec)
Signal wird nur bei aktiver PSD-Funktion zyklisch gesendet.";
CM_ SG_ 1125 PSD_LR_Fahrzeug_Pos "Position des Fahrzeug in % relativ zur Gesamtlaenge des Profils.
Signal wird nur bei aktiver PSD-Funktion zyklisch gesendet.";
CM_ SG_ 1125 PSD_LR_Globale_Steigung "Gesamtsteigung der in diesem  Profil übertragenen Strecke.
Signal wird nur bei aktiver PSD-Funktion zyklisch gesendet.";
CM_ SG_ 1125 PSD_LR_Globale_Steigung_Vorz "Vorzeichen für globale Steigung des Profils.
Signal wird nur bei aktiver PSD-Funktion zyklisch gesendet.";
CM_ SG_ 1125 PSD_LR_Koeff_1_Amp "Fehlende Beschreibung (Import)";
CM_ SG_ 1125 PSD_LR_Koeff_1_Phase "Phasenwert des ersten FFT-Koeffizienten.
Signal wird nur bei aktiver PSD-Funktion zyklisch gesendet.";
CM_ SG_ 1125 PSD_LR_Koeff_2_Amp "Fehlende Beschreibung (Import)";
CM_ SG_ 1125 PSD_LR_Koeff_2_Phase "Phasenwert des zweiten FFT-Koeffizienten.
Signal wird nur bei aktiver PSD-Funktion zyklisch gesendet.";
CM_ SG_ 1125 PSD_LR_Koeff_3_Amp "Fehlende Beschreibung (Import)";
CM_ SG_ 1125 PSD_LR_Koeff_3_Phase "Phasenwert des dritten FFT-Koeffizienten.
Signal wird nur bei aktiver PSD-Funktion zyklisch gesendet.";
CM_ SG_ 1125 PSD_LR_Koeffizientensatz_Nr "Nummer des aktuell übertragenen Koeffizientansatzes.
Signal wird nur bei aktiver PSD-Funktion zyklisch gesendet.";
CM_ SG_ 1125 PSD_LR_Max_Koeff_Amp "Maximale Höhe der übertragenen Amplitudenwerte.
Signal wird nur bei aktiver PSD-Funktion zyklisch gesendet.";
CM_ SG_ 1125 PSD_LR_Profil_Laenge "Gesamtlänge des übertragenen Profils.
Signal wird nur bei aktiver PSD-Funktion zyklisch gesendet.";
CM_ SG_ 1125 PSD_LR_Profil_Nummer "Nummer des aktuell übertragenen Profils";
CM_ SG_ 1125 PSD_LR_Reset "Reset-Signal, wenn der PSD-LR-Baum ungültig wird.
Signal wird nur bei aktiver PSD-Funktion zyklisch gesendet.";
CM_ SG_ 1125 PSD_LR_Steigung_1_Offset "Relative Position für die Steigung 1 im Profil.
Signal wird nur bei aktiver PSD-Funktion zyklisch gesendet.";
CM_ SG_ 1125 PSD_LR_Steigung_1_Vorz "Vorzeichen für Steigung 1.
Signal wird nur bei aktiver PSD-Funktion zyklisch gesendet.";
CM_ SG_ 1125 PSD_LR_Steigung_1_Wert "Mittlere Steigung zwischen dem Offset 1 und dem letzten Steigungswert.
Signal wird nur bei aktiver PSD-Funktion zyklisch gesendet.";
CM_ SG_ 1125 PSD_LR_Steigung_2_Offset "Relative Position für die Steigung 2 im Profil.
Signal wird nur bei aktiver PSD-Funktion zyklisch gesendet.";
CM_ SG_ 1125 PSD_LR_Steigung_2_Vorz "Vorzeichen für Steigung 2.
Signal wird nur bei aktiver PSD-Funktion zyklisch gesendet.";
CM_ SG_ 1125 PSD_LR_Steigung_2_Wert "Mittlere Steigung zwischen dem Offset 2 und dem letzten Steigungswert.
Signal wird nur bei aktiver PSD-Funktion zyklisch gesendet.";
CM_ SG_ 1125 PSD_LR_Steigung_3_Offset "Relative Position für die Steigung 3 im Profil.
Signal wird nur bei aktiver PSD-Funktion zyklisch gesendet.";
CM_ SG_ 1125 PSD_LR_Steigung_3_Vorz "Vorzeichen für Steigung 3.
Signal wird nur bei aktiver PSD-Funktion zyklisch gesendet.";
CM_ SG_ 1125 PSD_LR_Steigung_3_Wert "Mittlere Steigung zwischen dem Offset 3 und dem letzten Steigungswert.
Signal wird nur bei aktiver PSD-Funktion zyklisch gesendet.";

CM_ SG_ 906 QSP_03_BZ "BZ der QSP_03
Botschaft asynchron geroutet. Zählerwert kann springen.";
CM_ SG_ 906 QSP_03_CRC "Ab MQB und MLBevo:
'Berechnung siehe Lastenheft 'End-to-End Kommunikationsabsicherung''

Endwerte siehe Begleitdokument 'S-PDU Kennungsfolgen'";
CM_ SG_ 906 QSP_Init "Status Initialisierungsphase";
CM_ SG_ 906 QSP_Ist_Moment "Gib an welches (Ist)Moment aktuell vom QSP verlagert wird.

negativ: mehr Antriebsmoment nach rechts (/rechtes Rad wird beschleuningt)

positiv: mehr Antriebsmoment nach links (/linkes Rad wird beschleuningt)";
CM_ SG_ 906 QSP_Status "Status der QSP-ECU:
Dient der synchronisation von QSP mit EFP

0x00 Abgeschaltet
0x01 Init
0x02 Bereit
0x03 Normalbetrieb
0x04 Temporaer_beendet (Beenden des aktuellen Eingriffs,
anschließend Übergang in Temporaer_abgeschaltet)
0x05 Temporaer_abg";
CM_ SG_ 906 QSP_Temperatur_Oel "Aktuelle Hydrauli-Oel-Temperatur";
CM_ SG_ 906 QSP_Thermische_Belastung "Maximale aktuelle thermische Belastung des Gesamtsystems (Motor, ECU, Kupplungen)";
CM_ SG_ 906 QSP_Warnlampe "Status der Warnlampe: aktuell anliegender Fehlerzustand";

CM_ SG_ 1616 RA_AM_Tuning "Das Signal kennzeichnet einen aktiven AM Suchlauf. Während des Suchlaufes wird die Frequenz = 0 übertragen.
0 = frequency locked => Störquelle vermeidet die aktuelle Frequenz
1 = AM tuning in progress => Störquelle abschalten";
CM_ SG_ 1616 RA_Frequency "Übermittlung der gehörten Audiofrequenz (AM)
wird mit RA_Frequency_unit multipliziert.
Auf dem Bus werden nur eingerastete Frequenzen übertragen. Bei aktivem Tuning (RA_AM_Tuning = 1) wird 0 übertragen.";
CM_ SG_ 1616 RA_Frequency_unit "Faktor für RA_Frequency
bei AM: Faktor 0 = 1kHz
sonst   Faktor 1 = 100kHz";
CM_ SG_ 1616 RA_PowerAmpOn "1 = Request for Amplifier; 0 = Amplifier mute/off";
CM_ SG_ 1616 RA_Radio_Error_Flag "1 = mindestens ein Kundendienstfehlerspeicher Eintrag vorhanden";
CM_ SG_ 1616 RA_Radio_mute "1=Radio is muted for telephone";
CM_ SG_ 1616 RA_Radio_on "1 = user perceived On";
CM_ SG_ 1616 RA_Radio_Surround "1 = Surround ON; 0 = Surround OFF
requests the Amp to switch Surroundmode";
CM_ SG_ 1616 RA_VNC_OFF "VNC = Vehicle Noice Cancellation;
1 = VNC OFF; 0 = VNC ON
requests the Amp to switch VNC off";

CM_ SG_ 1529 RDK_angelernt "RDK signalisiert, dass die Radelektroniken angelernt sind und das Kombi den Rundstreckenmodus anbieten kann.";
CM_ SG_ 1529 RDK_FMVSS138_Lampe "Ansteuerung der RDK-Lampe im Kombi bei Druckwarnung";
CM_ SG_ 1529 RDK_FMVSS138_MIL "Ansteuerung der RDK-Lampe im Kombi bei Systemstörung.
RDK-Lampe muss für 65 Sekunden blinken und anschliessend dauerhaft leuchten bis RDK dieses Bit wieder auf '0' setzt (Wiedergutprüfung).
Hinweis:  Im AU48x blinken für 60 Sekunden";
CM_ SG_ 1529 RDK_Kalibrierung "Art der Vorgabe der Solldrücke
0x0 Vorgabe der Solldrücke erfolgt durch eine Reifenauswahl in der Headunit
0x1 Vorgabe der Solldrücke erfolgt durch Betätigung des SET-Tasters des Kombiinstruments";
CM_ SG_ 1529 RDK_Reifendruck_Lampe "Ansteuerung einer RDK-Lampe im Kombi bei einem problematischen Druck";
CM_ SG_ 1529 RDK_Reifentemperatur_Lampe "Ansteuerung einer RDK-Lampe im Kombi bei einer problematischen Reifentemperatur";
CM_ SG_ 1529 RDK_RS_aktiv "Rundstreckenmodus inaktiv/ aktiv";
CM_ SG_ 1529 RDK_Text_7 "Textausgabe 7: Mindestdruck für Rundstreckenmode unterschritten";
CM_ SG_ 1529 RDK_W_1_Reifen_HL "Harte Warnung fuer Reifen hinten links";
CM_ SG_ 1529 RDK_W_1_Reifen_HR "Harte Warnung fuer Reifen hinten rechts";
CM_ SG_ 1529 RDK_W_1_Reifen_VL "Harte Warnung fuer Reifen vorne links";
CM_ SG_ 1529 RDK_W_1_Reifen_VR "Harte Warnung fuer Reifen vorne rechts";
CM_ SG_ 1529 RDK_W_2_Reifen_HL "Weiche Warnung fuer Reifen hinten links";
CM_ SG_ 1529 RDK_W_2_Reifen_HR "Weiche Warnung fuer Reifen hinten rechts";
CM_ SG_ 1529 RDK_W_2_Reifen_VL "Weiche Warnung fuer Reifen vorne links";
CM_ SG_ 1529 RDK_W_2_Reifen_VR "Weiche Warnung fuer Reifen vorne rechts";
CM_ SG_ 1529 RDK_Warnungen_02 "Ausgabe von Texten/Akustik im Kombiinstrument";

CM_ SG_ 1711 RV_Dark_Screen "Verdunkelungsanforderung Kamerabild";
CM_ SG_ 1711 RV_Farbe "Istwert fuer Farbe (in Prozent)";
CM_ SG_ 1711 RV_Helligkeit "Istwert fuer Helligkeit (in Prozent)";
CM_ SG_ 1711 RV_HMI_Mode "Aktueller Wert für den HMI-Modus

";
CM_ SG_ 1711 RV_Kontrast "Istwert fuer Kontrast (in Prozent)";
CM_ SG_ 1711 RV_Menu_Item "Ausgewähltes Menü-Item
";
CM_ SG_ 1711 RV_Reinigung_Anf "Anforderung Reinigung der Rückfahrkamera";
CM_ SG_ 1711 RV_Settings_enabled "Menü 'Einstellungen'
";
CM_ SG_ 1711 RV_System_aktiv "Systemstatus (Initialisierungsphase)
";
CM_ SG_ 1711 RV_Video_on "Anzeige Kamerabild
";
CM_ SG_ 1711 SV_Video_on "Aufschaltaufforderung SideView";
CM_ SG_ 1711 ZFAS_Umfeldbeleuchtung_Anf "Anforderung für die Aktivierung einer Umfeldbeleuchtung zur Unterstützung des Umfeldkamerasystems bei Dunkelheit";

CM_ SG_ 1440 LS_defekt "Fehlererkennung Lichtsensor
";
CM_ SG_ 1440 LS_Helligkeit_FW "Vorfeldhelligkeit";
CM_ SG_ 1440 LS_Helligkeit_IR "Globalfeldhelligkeit";
CM_ SG_ 1440 LS_Verbau "Verbauinfo Lichtsensor";
CM_ SG_ 1440 RLS_Vorfeldhelligkeit_Boost "erweiterte Helligkeitssensierung für HUD";
CM_ SG_ 1440 RS_defekt "Fehlererkennung Regensensor";
CM_ SG_ 1440 RS_Regenmenge "Regenmenge für intel. Heckleuchte ";
CM_ SG_ 1440 RS_Verbau "Verbauinfo Regensensor";
CM_ SG_ 1440 RS_Verglasung_schliessen "Anforderung: Verglasung schliessen
";
CM_ SG_ 1440 RS_Wischergeschwindigkeit "Wischergeschwindigkeit (Hübe/min)";

CM_ SG_ 2527679790 RTM_Fehlerstatus "The error status of RTM.";
CM_ SG_ 2527679790 RTM_IstModus "The operation status of RTM";
CM_ SG_ 2527679790 RTM_OTA_Download_Process "RTM OTA package download process in percentage[%]:0~100%";
CM_ SG_ 2527679790 RTM_OTA_Download_Size "The size of OTA download package [MB]";
CM_ SG_ 2527679790 RTM_OTA_Download_Speed "RTM OTA package download speed
[MB/s]";
CM_ SG_ 2527679790 RTM_OTA_InstallDuration "The estimated duration of  OTA package installation
Range:1-30min";
CM_ SG_ 2527679790 RTM_OTA_InstallPrecondition "The precondition check for SW upgrade installation.";
CM_ SG_ 2527679790 RTM_OTA_InstallProcess "RTM OTA package installation process in percentage[%]:0~100%";
CM_ SG_ 2527679790 RTM_OTA_SignalStrength "The signal strength during OTA package downloading";

CM_ SG_ 2527679792 MIB_OTA_Comfirmation "MIB Pop-up confirmations for RTM OTA";

CM_ SG_ 1517 SAD2_Deckel_Lage "Lage Schiebeausstelldach";
CM_ SG_ 1517 SAD2_Deckel_normiert "Anzeige Normierung des Schiebeausstelldaches 2";
CM_ SG_ 1517 SAD2_Deckel_Position "Aktuelle Öffnungsweite des Schiebeausstelldaches 2";
CM_ SG_ 1517 SAD2_Deckel_Thermoschutz "Anzeige aktivierter Thermoschutz des Schiebeausstelldaches 2";
CM_ SG_ 1517 SAD2_Deckel_UEKB_aktiv "Anzeige aktivierter Überschusskraftbegrenzung des Schiebeausstelldaches 2";
CM_ SG_ 1517 SAD2_Rollo_Lage "Lage des Rollo 2";
CM_ SG_ 1517 SAD2_Rollo_normiert "Signal für die Anzeige, dass das Rollo2 korrekt normiert wurde.";
CM_ SG_ 1517 SAD2_Rollo_Position "Aktuelle Öffnungsweite des Dachrollo 2.";
CM_ SG_ 1517 SAD2_Rollo_Thermoschutz "Anzeigen aktivierter Thermoschutz des Dachrollo 2";
CM_ SG_ 1517 SAD2_Rollo_UEKB_aktiv "Anzeigen aktivierter Überschusskraftbegrenzung des Dachrollos 2";

CM_ SG_ 1504 MD1_Lage "Lage Schiebedachstellung 1 (Signal wird 1:1 vom BCM2 geroutet; ursprünglicher Sender: SAD = LIN-Slave vom BCM2)";
CM_ SG_ 1504 MD1_Position "Aktuelle Öffnungsweite Schiebedach.";
CM_ SG_ 1504 MD3_Lage "Lage Schiebedachstellung 3 
(Signal wird 1:1 vom BCM2 geroutet; ursprünglicher Sender: SAD = LIN-Slave vom BCM2) 
";
CM_ SG_ 1504 MD3_Position "Schiebedachstellung 3 
(Signal wird 1:1 vom BCM2 geroutet; ursprünglicher Sender: SAD = LIN-Slave vom BCM2)
";
CM_ SG_ 1504 MRollo_Lage "Lage Rollo
(Signal wird 1:1 vom BCM2 geroutet; ursprünglicher Sender: Rollo = LIN-Slave vom BCM2)";
CM_ SG_ 1504 MRollo_Position "Aktuelle Öffnungsweite des Dachrollos.";
CM_ SG_ 1504 Rollo_normiert "Anzeigen Normierung des Dachrollos";
CM_ SG_ 1504 Rollo_Thermoschutz "Anzeigen aktivierter Thermoschutz des Dachrollo";
CM_ SG_ 1504 Rollo_UEKB_aktiv "Anzeigen aktivierter Überschusskraftbegrenzung des Dachrollos";
CM_ SG_ 1504 SAD_Anf_ESC_Zuschaltung "Zwangsaktivierung ESP durch SAD-SG (bei geöffnetem Schiebedach und V> xx km/h).";
CM_ SG_ 1504 SAD_normiert "Anzeige Normierung des Schiebeausstelldaches";
CM_ SG_ 1504 SAD_ParityBit "SIL A Absicherung für die Signale: SAD_normiert, MD1_Lage, MD1_Position, SAD_Anf_ESC_Zuschaltung";
CM_ SG_ 1504 SAD_Taster_Deckel_hi "Taster für SAD Deckel hinten";
CM_ SG_ 1504 SAD_Taster_Deckel_vo "Taster für SAD Deckel vorne";
CM_ SG_ 1504 SAD_Taster_Rollo_hi "Taster für SAD Rollo hinten";
CM_ SG_ 1504 SAD_Taster_Rollo_vo "Taster für SAD Rollo vorne";
CM_ SG_ 1504 SAD_Text "Fehler Windabweiser in Abhängigkeit von der Geschwindigkeit";
CM_ SG_ 1504 SAD_Thermoschutz "Anzeige aktivierter Thermoschutz des Schiebeausstelldaches";
CM_ SG_ 1504 SAD_ToggleBit "SIL A Absicherung für die Signale: SAD_normiert, MD1_Lage, MD1_Position, SAD_Anf_ESC_Zuschaltung";
CM_ SG_ 1504 SAD_UEKB_aktiv "Anzeige aktivierter Überschusskraftbegrenzung des Schiebeausstelldaches";

CM_ SG_ 249 SARA_Nickwinkel "Nickwinkel des Fahrzeugs relativ zum Gravitationsvektor; 
Vorzeichen nach DIN70000";
CM_ SG_ 249 SARA_Wankwinkel "Wankwinkel des Fahrzeugs relativ zum Gravitationsvektor; 
Vorzeichen nach DIN70000";

CM_ SG_ 378 SARA_Accel_X_010_02 "Beschleunigung Acceleration-X Basis:
- 0x0000 = Sensor nicht verbaut, Signal wird nicht berechnet
- genutzter Wertebereich ± 640 m/s²

Filterung: 60 Hz Sensorfilter + 15 Hz uC-Filter (Cheby-II 3.Ordnung)";
CM_ SG_ 378 SARA_Accel_Y_010_02 "Beschleunigung Acceleration-X Basis:
- 0x0000= Sensor nicht verbaut, Signal wird nicht berechnet
- genutzter Wertebereich ± 640 m/s²

Filterung: 60 Hz Sensorfilter + 15 Hz uC-Filter (Cheby-II 3.Ordnung)";
CM_ SG_ 378 SARA_CF_Accel_X_010_02 "Confidence Faktor Beschleunigung Acceleration-X Basis:

0=gültiger Wert
1=nicht belegt
2=nicht belegt
3=Temporärer Fehler [solange möglich werden aktuelle Sensorwerte gesendet, ansonsten 0xFFFF]
4=Init [0x8000 wird gesendet]
5=Sensor nicht verbaut/";
CM_ SG_ 378 SARA_CF_Accel_Y_010_02 "Confidence Faktor Beschleunigung Acceleration-Y Basis:

0=gültiger Wert
1=nicht belegt
2=nicht belegt
3=Temporärer Fehler [solange möglich werden aktuelle Sensorwerte gesendet, ansonsten 0xFFFF]
4=Init [0x8000 wird gesendet]
5=Sensor nicht verbaut/";
CM_ SG_ 378 SARA_CF_Omega_Z_010_02 "Confidence Faktor Winkelgeschwindigkeit Omega-Z Basis:

0=gültiger Wert
1=nicht belegt
2=nicht belegt
3=Temporärer Fehler [solange möglich werden aktuelle Sensorwerte gesendet, ansonsten 0xFFFF]
4=Init [0x8000 wird gesendet]
5=Sensor nicht verbaut/";
CM_ SG_ 378 SARA_Omega_Z_010_02 "Winkelgeschwindigkeit Omega-Z Basis:
- 0x0000 = Sensor nicht verbaut, Signal wird nicht berechnet
- genutzter Wertebereich ± 320 Deg/s

Filterung: 60 Hz Sensorfilter + ohne uC-Filter";

CM_ SG_ 424 SARA_11_CRC "Für MLB:
'Berechnung siehe Lastenheft 'Kommunikationsabsicherung für Flexray und CAN''

Ab MQB und MLBevo:
'Berechnung siehe Lastenheft 'End-to-End Kommunikationsabsicherung'

Endwerte siehe Begleitdokument 'S-PDU Kennungsfolge'";
CM_ SG_ 424 SARA_Accel_X_r "Beschleunigung Acceleration-X routable:
- 0x0000= Sensor nicht verbaut, Signal wird nicht berechnet
- genutzter Wertebereich ± 640 m/s²

Filterung: 60 Hz Sensorfilter + 15 Hz uC-Filter (Cheby-II 3.Ordnung)";
CM_ SG_ 424 SARA_Accel_Y_r "Beschleunigung Acceleration-Y routable:
- 0x0000= Sensor nicht verbaut, Signal wird nicht berechnet
- genutzter Wertebereich ± 640 m/s²

Filterung: 60 Hz Sensorfilter + 15 Hz uC-Filter (Cheby-II 3.Ordnung)";
CM_ SG_ 424 SARA_CF_Accel_X_r "Confidence Faktor Beschleunigung Acceleration-X routable:

0=gültiger Wert
1=nicht belegt
2=nicht belegt
3=Temporärer Fehler {solange möglich werden aktuelle Sensorwerte gesendet, ansonsten 0xFFFF}
4=Init {0x8000 wird gesendet}
5=Sensor nicht verba";
CM_ SG_ 424 SARA_CF_Accel_Y_r "Confidence Faktor Beschleunigung Acceleration-Y routable:

0=gültiger Wert
1=nicht belegt
2=nicht belegt
3=Temporärer Fehler {solange möglich werden aktuelle Sensorwerte gesendet, ansonsten 0xFFFF}
4=Init {0x8000 wird gesendet}
5=Sensor nicht verba";
CM_ SG_ 424 SARA_CF_Omega_Z_r "Confidence Faktor Winkelgeschwindigkeit Omega-Z routable:

0=gültiger Wert
1=nicht belegt
2=nicht belegt
3=Temporärer Fehler {solange möglich werden aktuelle Sensorwerte gesendet, ansonsten 0xFFFF}
4=Init {0x8000 wird gesendet}
5=Sensor nicht verba";
CM_ SG_ 424 SARA_Omega_Z_r "Winkelgeschwindigkeit Omega-Z routable:
- 0x0000 = Sensor nicht verbaut, Signal wird nicht berechnet
- genutzter Wertebereich ± 320 Deg/s

Filterung: 60 Hz Sensorfilter + 15 Hz uC-Filter (Cheby-II 3.Ordnung)";

CM_ SG_ 1011 SCR_01_BZ "Zähler der von der Applikation inkrementiert wird";
CM_ SG_ 1011 SCR_Dosierpumpe_Drehzahl "Drehzahl der Dosierpumpe

negative 1/min für Rückwärtsbetrieb
0 für Stop
positive 1/min für Vorwärtsbetrieb";
CM_ SG_ 1011 SCR_Druck "Druck der wässrigen Harnstofflösung";
CM_ SG_ 1011 SCR_Level_Aktivtank "Füllstand des Aktivtanks";
CM_ SG_ 1011 SCR_Level_ReadAbove "Zeigt an in welchem Messmodus der Levelsensor ist.
Dieses Signal ist für die Füllstandberechnung notwendig und für die OBD-Diagnose mit notwendig.
Ist der Sensor im Readabove Ein Modus, ist die Toleranz des gemessenen Signals größer.";
CM_ SG_ 1011 SCR_QBit_Level_Aktivtank_02 "gibt an ob das Signal gültig ist.";
CM_ SG_ 1011 SCR_Sent_Level_Aktivtank "Füllstand des Aktivtanks";
CM_ SG_ 1011 SCR_Sent_Levelsignal_Status "Gibt an, in welchem Aggregatzustand sich die Flüssigkeit im Aktivtank befindet";

CM_ SG_ 1507 SCR_02_BZ "Zähler der von der Applikation inkrementiert wird";
CM_ SG_ 1507 SCR_Guetesensor "Güte der Flüssigkeit";
CM_ SG_ 1507 SCR_Heizkreis_3_Strom "gemessener Strom vom Heizkreis 3 (ist optional verbaut)";
CM_ SG_ 1507 SCR_Leitungsheizung_Strom "gemessener Strom für die Leitungsheizung";
CM_ SG_ 1507 SCR_Tankheizung_Strom "gemessener Strom für die Tankheizung Aktivtank";
CM_ SG_ 1507 SCR_Temp_Aktivtank "Temperatur des Medium im Aktivtank";
CM_ SG_ 1507 SCR_Temp_Passivtank "Temperatur des Medium im Aktivtank";
CM_ SG_ 1507 SCR_Transferpumpe_Strom "gemessener Strom für dieTransferpumpe";

CM_ SG_ 1526 SCR_05_BZ "Zähler der von der Applikation inkrementiert wird";
CM_ SG_ 1526 SCR_DEF_Qualitaet_Medium "Gibt an, dass die Konzentration des Medium nicht ermittelt werden kann.";
CM_ SG_ 1526 SCR_ECU_Datensatz_Status "StatusInformation für OBD-Auswertung";
CM_ SG_ 1526 SCR_HAL_Sensorik_Status "Statusinformation für OBD-Auswertung der HAL-Sensorik";
CM_ SG_ 1526 SCR_Level_Aktivtank_OOR4Quality "Der Füllstand im SCR-Tank ist zu niedrig um eine Qualtiätsmessung durchzuführen.";
CM_ SG_ 1526 SCR_Level_Aktivtank_OOR_minus "Minimaler Level vom SCR-Tank erreicht.
Tankstand so niedrig, dass das Signal nicht mehr verlässlich erfasst werden kann.";
CM_ SG_ 1526 SCR_QBit_Qualitaet "gibt an ob das Signal gültig ist";
CM_ SG_ 1526 SCR_Sent_1_elektrischer_Status "Fehlerstatus der elektrischen Diagnosen";
CM_ SG_ 1526 SCR_Sent_1_Signalstatus "Signalfehler vom Sent_1 Signal";
CM_ SG_ 1526 SCR_Sent_2_elektrischer_Status "Fehlerstatus der elektrischen Diagnosen auf dem zweiten Sentkanal";
CM_ SG_ 1526 SCR_Sent_2_Signalstatus "Signalfehler vom Sent_2  Signal";
CM_ SG_ 1526 SCR_Sent_Levelsensor "Funktionaler Fehlerstatus des Levelsensors";
CM_ SG_ 1526 SCR_Sent_Qualitaetssensor "Funktionalen Fehler des Qualitätssensors";
CM_ SG_ 1526 SCR_Sent_Temperatursensor "Funktionaler Fehlerstatus vom internen Temperatursensor in dem Sentsensor";
CM_ SG_ 1526 SCR_Steuergeraet_Bus_Status "StatusInformation für OBD-Auswertung";
CM_ SG_ 1526 SCR_Steuergeraet_Defekt_Status "StatusInformation für OBD-Auswertung";
CM_ SG_ 1526 SCR_Steuergeraet_Heizung_Status "StatusInformation für OBD-Auswertung";
CM_ SG_ 1526 SCR_Steuergeraet_Pumpe_Status "StatusInformation der Dosierpumpe für OBD-Auswertung";
CM_ SG_ 1526 SCR_Steuergeraet_Relais_Status "StatusInformation für OBD-Auswertung";
CM_ SG_ 1526 SCR_Temp_DEF2_Sensor_Status "Funktionaler Fehlerstatus vom internen Temperatursensor des zweiten Sentsensors";

CM_ SG_ 873 SDF2_Pos_AnzHauptspuren "Gesamthauptspuranzahl (ohne Ausfahrtsspuren)";
CM_ SG_ 873 SDF2_Pos_AnzRampenLinks "Zusätzliche Spuren links (z.B. Aus- / Auffahrtsspuren, Abbiegespuren)";
CM_ SG_ 873 SDF2_Pos_AnzRampenRechts "Zusätzliche Spuren rechts (z.B. Aus- / Auffahrtsspuren, Abbiegespuren)";
CM_ SG_ 873 SDF2_Pos_Distanz_Rampe_links "Distanz kommende Rampe links";
CM_ SG_ 873 SDF2_Pos_Distanz_Rampe_rechts "Distanz kommende Rampe rechts";
CM_ SG_ 873 SDF2_Pos_Fehler_Laengsrichtung "Längsfehler der Positionskorrektur im zFAS";
CM_ SG_ 873 SDF2_Pos_GueteZuordnung "Guete der Spurzuordnung";
CM_ SG_ 873 SDF2_Pos_Inhibitzeit "Zeitspanne zwischen Generierung der Position im ZR und Versand der Positionsdaten durch das zFAS";
CM_ SG_ 873 SDF2_Pos_Offset "Verbleibende Länge des Streckensegments, auf dem sich das Fahrzeug nach der Positionierung auf dem zFAS befindet.";
CM_ SG_ 873 SDF2_Pos_Segment_ID "PSD-Segment ID der Positionierung im zFAS";
CM_ SG_ 873 SDF2_Pos_Spurnummer "Spurnummer des Fahrzeugs
Negativ=Auf-/Ausfahrten, Abbiegespuren
Positiv=Hauptspuren";
CM_ SG_ 873 SDF2_Pos_Spurtype "Typ der Spur";
CM_ SG_ 873 SDF2_Pos_Standort_Eindeutig "Information, ob die Position des Fahrzeugs im zFAS eindeutig dem aktuellen Segment zugeordnet wurde.";

CM_ SG_ 2589283634 SM_LAPP_Aussenlicht_aktiv "Rückmeldung ob Licht-App für Aussenlicht aktiv ist.";
CM_ SG_ 2589283634 SM_LAPP_Demo_ABBL_Anf "Anforderung des Abblendlichts zur Demonstration über die Licht-App.";
CM_ SG_ 2589283634 SM_LAPP_Demo_Autobahnmodus_Anf "Anforderung des Autobahnmodus zur Demonstration über die Licht-App";
CM_ SG_ 2589283634 SM_LAPP_Demo_Distanz_01 "Abstandsangabe zur Demonstration verschiedener Lichtfunktionen über die Licht-App.";
CM_ SG_ 2589283634 SM_LAPP_Demo_Distanz_02 "Abstandsangabe zur Demonstration verschiedener Lichtfunktionen über die Licht-App.";
CM_ SG_ 2589283634 SM_LAPP_Demo_DKL_Anf "Anforderung des dyn. Kurvenlichts über die Licht-App";
CM_ SG_ 2589283634 SM_LAPP_Demo_Einschalteffekt_Anf "Anforderung des Einschalteffekts zur Demonstration über die Licht-App";
CM_ SG_ 2589283634 SM_LAPP_Demo_FL_Anf "Anforderung des Fernlichts zur Demonstration über die Licht-App.";
CM_ SG_ 2589283634 SM_LAPP_Demo_MaLi_Anf "Anforderung des Markierungslichts zur Demonstration über die Licht-App";
CM_ SG_ 2589283634 SM_LAPP_Demo_Objekt_01_Anf "Anforderung zur Ausblendung eines Objekts zur Demonstration der MxB-Funktionalität über die Licht-App";
CM_ SG_ 2589283634 SM_LAPP_Demo_Objekt_02_Anf "Anforderung zur Ausblendung eines Objekts zur Demonstration der MxB-Funktionalität über die Licht-App";
CM_ SG_ 2589283634 SM_LAPP_Demo_Schildentbl_01_Anf "Anforderung der Schilderentblendung zur Demonstration über die Licht-App";
CM_ SG_ 2589283634 SM_LAPP_Demo_Schildentbl_02_Anf "Anforderung der Schilderentblendung zur Demonstration über die Licht-App";
CM_ SG_ 2589283634 SM_LAPP_Demo_Winkel_Hor_01 "Horizontaler Universalwinkel zur Demonstration verschiedener Lichtfunktionen über die Licht-App.";
CM_ SG_ 2589283634 SM_LAPP_Demo_Winkel_Hor_02 "Horizontaler Universalwinkel zur Demonstration verschiedener Lichtfunktionen über die Licht-App.";
CM_ SG_ 2589283634 SM_LAPP_Demo_Winkel_Vert_01 "Vertikaler Universalwinkel zur Demonstration verschiedener Lichtfunktionen über die Licht-App.";
CM_ SG_ 2589283634 SM_LAPP_Demo_Winkel_Vert_02 "Vertikaler Universalwinkel zur Demonstration verschiedener Lichtfunktionen über die Licht-App.";
CM_ SG_ 2589283634 SM_LAPP_Verbindungsstatus "Verbindungsstatus der Licht-App zur DDA für Aussenlicht.";

CM_ SG_ 2527679657 SM_LAPP_Demo_AbbiegeWa_Anf "Anforderung des Abbiege-Warnlichts zur Demonstration über die Licht-App.";
CM_ SG_ 2527679657 SM_LAPP_Demo_AbsAss_Anf "Anforderung des Abstands-Assistentzlichts zur Demonstration über die Licht-App.";
CM_ SG_ 2527679657 SM_LAPP_Demo_AccAss_Anf "Anforderung des ACC-Assistentzlichts zur Demonstration über die Licht-App.";
CM_ SG_ 2527679657 SM_LAPP_Demo_advCH_F01_Anf "Anforderung von advanced Coming Home zur Demonstration über die Licht-App.";
CM_ SG_ 2527679657 SM_LAPP_Demo_advLH_F01_Anf "Anforderung von advanced Leaving Home zur Demonstration über die Licht-App.";
CM_ SG_ 2527679657 SM_LAPP_Demo_BauLi_Anf "Anforderung des Baustellenlichts zur Demonstration über die Licht-App.";
CM_ SG_ 2527679657 SM_LAPP_Demo_BeAss_Anf "Anforderung des Beschleunigungs-Lichtassistenten zur Demonstration über die Licht-App.";
CM_ SG_ 2527679657 SM_LAPP_Demo_CH_F01_Anf "Anforderung unterschiedlicher Coming Home Animationen für die Front zur Demonstration über die Licht-App.

Der Wert des Signals gibt die ID der auszuführenden Animation aus. Die Zuordnung der IDs ist dabei fahrzeugspezifisch. Der Signalwert 0 entspricht";
CM_ SG_ 2527679657 SM_LAPP_Demo_CH_H01_Anf "Anforderung der Heckleuchten-Animation für Coming Home zur Demonstration über die Licht-App";
CM_ SG_ 2527679657 SM_LAPP_Demo_EffAss_Anf "Anforderung des Effizienz-Lichtassistenten zur Demonstration über die Licht-App.";
CM_ SG_ 2527679657 SM_LAPP_Demo_LH_F01_Anf "Anforderung unterschiedlicher Leaving Home Animationen für die Front zur Demonstration über die Licht-App.

Der Wert des Signals gibt die ID der auszuführenden Animation aus. Die Zuordnung der IDs ist dabei fahrzeugspezifisch. Der Signalwert 0 entsprich";
CM_ SG_ 2527679657 SM_LAPP_Demo_LH_H01_Anf "Anforderung der Heckleuchten-Animation für Leaving Home zur Demonstration über die Licht-App";
CM_ SG_ 2527679657 SM_LAPP_Demo_PreSAss_Anf "Anforderung des PreSense-Lichtassistenten zur Demonstration über die Licht-App.";
CM_ SG_ 2527679657 SM_LAPP_Demo_RouLi_Anf "Anforderung des Routenlichts zur Demonstration über die Licht-App.";
CM_ SG_ 2527679657 SM_LAPP_Demo_SitLi_Anf "Anforderung des Situationslichts zur Demonstration über die Licht-App.";
CM_ SG_ 2527679657 SM_LAPP_Demo_SL_Anf "Anforderung des Schlusslichts zur Demonstration über die Licht-App";
CM_ SG_ 2527679657 SM_LAPP_Demo_SL_Signatur_Anf "Anforderung einer Schlusslicht-Signatur über die Licht-App";
CM_ SG_ 2527679657 SM_LAPP_Demo_SpuLi_Anf "Anforderung des Spurlichts zur Demonstration über die Licht-App.";
CM_ SG_ 2527679657 SM_LAPP_Demo_Stufe "Universelle Stufenvorgabe zur Demonstration verschiedener Lichtfunktionen über die Licht-App.";
CM_ SG_ 2527679657 SM_LAPP_Demo_TraLi_Anf "Anforderung des Trajektorienlichts zur Demonstration über die Licht-App.";
CM_ SG_ 2527679657 SM_LAPP_Demo_Variante "Universelle Variantenvorgabe zur Demonstration verschiedener Lichtfunktionen über die Licht-App.";

CM_ SG_ 201 SM_AFR_Standfkt_Anf "Teilt der Funktion AFR mit, welche Funktion ausgeführt werden soll";
CM_ SG_ 201 SM_AFR_Verbindungsstatus "Teilt der Funktion AFR mit, ob eine Verbindung zum Smartphone besteht oder diese abgebrochen ist.";
CM_ SG_ 201 SM_Anlernstatus "Dient Funktionen bereits beim Aufschalten einer Funktion zu prüfen, ob mindestens ein Gerät in der Liste der gespeicherten Geräte hinterlegt ist.";
CM_ SG_ 201 SM_App_Sperrzustand "Signal zeigt an, ob sich der Kunde bereits innerhalb der App authentifiziert hat oder nicht.";
CM_ SG_ 201 SM_ARA_Gangwahl "Auswahl des Ganges";
CM_ SG_ 201 SM_ARA_Gaspedal "Gibt die Stellung des virtuellen Gaspedals wieder";
CM_ SG_ 201 SM_ARA_Knickwinkel_Soll "Angeforderter Knickwinkel";
CM_ SG_ 201 SM_ARA_Nothalt "Fordert einen Nothalt an";
CM_ SG_ 201 SM_ARA_Start "ARA-Funktion per Smartphone aufrufen";
CM_ SG_ 201 SM_ARA_Status_Steuersignal "Gibt den Status des Steuersignals wieder";
CM_ SG_ 201 SM_ARA_Trajektorienmodus "Trajektorienmodus für ARA auf Samrtphone (de-/aktivieren)";
CM_ SG_ 201 SM_Fehlerstatus "Kennzeichnet die Erkennung eines beliebigen Fehlers auf der Kommunikationsstrecke zwischen mobilen Endgerät und Fahrzeug.";
CM_ SG_ 201 SM_Parken_Alive "Botchaftszähler zur Absicherung der Fahrtasterinteraktionen auf dem Smartphone.";
CM_ SG_ 201 SM_Parken_Kommando "Teilt der Parkfunktion mit, welche Eingaben der Nutzer auf dem Smartphone tätigt um die Funktion zu bedienen. Hauptsächlich Fahrtasterinteraktionen";
CM_ SG_ 201 SM_Parken_Kommando_invers "Invertiert das Signal SM_Parken_Kommando zur Absicherung der Übertragung aller Fahrtasterinteraktionen.";
CM_ SG_ 201 SM_Parken_Manoever "Beschreibt ob ein- oder ausgeparkt werden soll";
CM_ SG_ 201 SM_Parken_Motorstart_Anf "Dieses Signal teilt der Parkfunktion die Motorstartanforderung durch den Kunden mit.";
CM_ SG_ 201 SM_Parken_Richtung "Beschreibt ob die Parklücke vorwärts oder rückwärts beparkt werden soll";
CM_ SG_ 201 SM_Parken_Seite "Beschreibt ob eine Lücke links oder rechts vom Fahrzeug beparkt werden soll. Beim Ausparken kann zusätzlich zu einer Seite, geradeaus ausgeparkt werden. ";
CM_ SG_ 201 SM_Parken_Szenario "Beschreibt den Grundszenarientyp (Parallel = Längsparken; Perpendicular = Querparken; Garage = Garagenparken; Basic = Basisfunktion vorwärts oder rückwärts ohne Lenkeingriff)";
CM_ SG_ 201 SM_Parken_Touch_PosX "Position der Touchscreeneingabe in X-Richtung";
CM_ SG_ 201 SM_Parken_Touch_PosY "Position der Touchscreeneingabe in Y-Richtung";
CM_ SG_ 201 SM_Parken_Verbindungsstatus "Teilt der Parkfunktion mit, ob eine Verbindung zum Smartphone besteht. Die ID dient der Erkennung eines Gerätewechsels innerhalb eines Parkzyklus.";

CM_ SG_ 2527679651 SM_Parken_blinken "Blinkerstatus ARA auf Smartphone";
CM_ SG_ 2527679651 SM_Parken_Hupe_Anf "Ansteuerung der Hupe beim PiloPa";
CM_ SG_ 2527679651 SM_Parken_Komfortschliessen_Anf "Anforderung für Komfortschließen der Fenster und des SAD (Schiebeaufstelldach) beim PiloPa";
CM_ SG_ 2527679651 SM_Parken_UGDO_Aktion "Ansteuerung des UGDO (Universal Garage Door Opener) beim PiloPa für:
- Garagentor öffnen oder toggeln (garagentorabhängig),
- Garagentor schließen,
- Garagentor stoppen (z. B. bei Gefahr),
- Status des Garagentors abfragen (Antwort ist UGDO_DoorState)";
CM_ SG_ 2527679651 SM_Parken_UGDO_Anf "Ansteuerung von bis zu 15 verschiedenen UGDOs (Universal Garage Door Opener) beim PiloPa";

CM_ SG_ 980 BH_Blinker_Fehler "Anzeige, ob am Lenkstockschalter ein Fehler anliegt.
Notwendig aufgrund ASIL-Einstufung";
CM_ SG_ 980 BH_Blinker_li "Blinkerhebel Richtung links";
CM_ SG_ 980 BH_Blinker_re "Blinkerhebel Richtung rechts";
CM_ SG_ 980 BH_Fernlicht "Betaetigung Fernlicht
";
CM_ SG_ 980 BH_Lichthupe "Betaetigung Lichthupe
";
CM_ SG_ 980 FAS_Taster "Betaetigung FAS Taster
";
CM_ SG_ 980 FAS_Taster_Fehler "Fehlerstatus FAS Taster
";
CM_ SG_ 980 LRH_aktiv "Signal gibt an, ob ein Heizstrom durch die Lenkradheizung fließt. Es dient der Auswertung durch das Energiemanagement.";
CM_ SG_ 980 LRH_On_Off "Status Lenkradheizung";
CM_ SG_ 980 SMLS_01_BZ "4bit Botschaftszaehler, wird mit jeder Sendebotschaft inkrementiert";
CM_ SG_ 980 SMLS_01_CRC "Für MLB:
'Berechnung siehe Lastenheft 'Kommunikationsabsicherung für FlexRay und CAN''

Ab MQB und MLBevo:
'Berechnung siehe Lastenheft 'End-to-End Kommunikationsabsicherung''

Endwerte siehe Begleitdokument 'S-PDU Kennungsfolgen'";
CM_ SG_ 980 SMLS_Hupe "Betaetigung Hupe
";
CM_ SG_ 980 SMLS_P_verriegelt_plausibel "Signal stellt den Plausibilisierungstatus des Signals p_verriegelt auf den Fahrzeugbus zur Verfügung. Eine Plausibilität muss explizit erkannt werden. Initial wird 'unplausibel' gesendet. Ein plausibles Signal wird erkannt, wenn p_verriegelt plausibel geg";
CM_ SG_ 980 SMLS_PTT "Betaetigung PTT";
CM_ SG_ 980 WH_Frontwaschen "Wischerhebel: Stellung Wisch Wasch vorne
";
CM_ SG_ 980 WH_Heckintervall "Wischerhebel: Stellung Heckintervall
";
CM_ SG_ 980 WH_Heckwaschen "Wischerhebel: Stellung Wisch Wasch hinten
";
CM_ SG_ 980 WH_Intervall "Wischerhebel: Stellung Intervall
";
CM_ SG_ 980 WH_Intervallstufen "Wischerhebel: Stellung Intervallstufen";
CM_ SG_ 980 WH_SRA "Scheinwerferreinigungsanlage

derzeit nur bei PAG umgesetzt";
CM_ SG_ 980 WH_Tipwischen "Wischerhebel: Tippwischen

MQB A0/ PQ26: Bei Verbau LSS (kein SMLS): gespiegelter Wert zu Signal WH_WischerStufe1";
CM_ SG_ 980 WH_Tipwischen_lang "Wischerhebel: Tippwischen lang
(dient zur Auswertung für die Unterscheidung Tippwischen oder Serviceposition Wischer)";
CM_ SG_ 980 WH_Wischer_Fehler "Anzeige, ob am Lenkstockschalter ein Fehler anliegt.
Notwendig aufgrund ASIL-Einstufung";
CM_ SG_ 980 WH_WischerStufe1 "Wischerhebel: Stufe Wischen 1
";
CM_ SG_ 980 WH_WischerStufe2 "Wischerhebel: Stufe Wischen 2
";

CM_ SG_ 1467 SoSe_SunInt_2D_Li "Sonnenintensität links (2D Sensor)";
CM_ SG_ 1467 SoSe_SunInt_2D_Re "Sonnenintensität rechts (2D Sensor)";

CM_ SG_ 1710 SP_abklappen "Spiegel abklappen";
CM_ SG_ 1710 SP_anklappen "Spiegel anklappen";
CM_ SG_ 1710 SP_ARA_Status "Rückkanal TSG im ARA-Modus";
CM_ SG_ 1710 SP_Auswahl_li "Spiegelschalter in Stellung Auswahl links";
CM_ SG_ 1710 SP_Auswahl_re "Spiegelschalter in Stellung Auswahl rechts";
CM_ SG_ 1710 SP_BT_links "Spiegel Beifahrertür nach links";
CM_ SG_ 1710 SP_BT_oben "Spiegel Beifahrertür nach oben";
CM_ SG_ 1710 SP_BT_rechts "Spiegel Beifahrertür nach rechts";
CM_ SG_ 1710 SP_BT_unten "Spiegel Beifahrertür nach unten";
CM_ SG_ 1710 SP_FT_links "Spiegel Fahrertür nach links";
CM_ SG_ 1710 SP_FT_oben "Spiegel Fahrertür nach oben";
CM_ SG_ 1710 SP_FT_rechts "Spiegel Fahrertür nach rechts";
CM_ SG_ 1710 SP_FT_unten "Spiegel Fahrertür nach unten";
CM_ SG_ 1710 SP_Hzg_Taster "Heizungstaster/schalter aktiv";
CM_ SG_ 1710 SP_normieren "Spiegel normieren";
CM_ SG_ 1710 SP_S_Klappen "Spiegelschalter in Stellung Klappen";
CM_ SG_ 1710 SP_S_links "Spiegelschalter in Stellung links";
CM_ SG_ 1710 SP_S_oben "Spiegelschalter in Stellung oben";
CM_ SG_ 1710 SP_S_rechts "Spiegelschalter in Stellung rechts";
CM_ SG_ 1710 SP_S_unten "Spiegelschalter in Stellung unten";
CM_ SG_ 1710 SP_Verstellschalter_Fehler "Erkennung eines hängenden Spiegelverstellschalters";
BA_DEF_REL_ BU_SG_REL_  "GenSigTimeoutTime" INT 0 65535;
BA_DEF_ BO_  "DiagRequest" ENUM "No", "Yes";
BA_DEF_ BO_  "DiagResponse" ENUM "No", "Yes";
BA_DEF_ BO_  "DiagState" ENUM "No", "Yes";
BA_DEF_ BO_  "GenMsgChkConstant" HEX 0 4095;
BA_DEF_ BO_  "GenMsgCycleTime" INT 0 65535;
BA_DEF_ BO_  "GenMsgCycleTimeFast" INT 0 65535;
BA_DEF_ BO_  "GenMsgDelayTime" INT 0 100000;
BA_DEF_ BO_  "GenMsgILSupport" ENUM "No", "Yes";
BA_DEF_ BO_  "GenMsgNrOfRepetition" INT 0 100;
BA_DEF_ BO_  "GenMsgPDUConstants" STRING;
BA_DEF_ BO_  "GenMsgSendType" ENUM "Cyclic", "not_used", "not_used", "not_used", "not_used", "not_used", "not_used", "IfActive", "NoMsgSendType";
BA_DEF_ BO_  "GenMsgStartDelayTime" INT 0 100000;
BA_DEF_ BO_  "NmMessage" ENUM "No", "Yes";
BA_DEF_ BO_  "NmhMessage" ENUM "No", "Yes";
BA_DEF_ BO_  "MsgType" ENUM "Application", "NM ", "NMH", "TP2.0", "ISO-TP ", "BAP", "EID", "KS", "XCP_PRE_CONFIGURED", "XCP_RUNTIME_CONFIGURED";
BA_DEF_ BO_  "VAGTP20_API" HEX 0 255;
BA_DEF_ BO_  "VAGTP20_DynConnection" ENUM "No", "Yes";
BA_DEF_ BO_  "VAGTP20_DynSetup" ENUM "No", "Yes";
BA_DEF_ BO_  "VAGTP20_StatConnection" ENUM "No", "Yes";
BA_DEF_ SG_  "GenSigActiveRepetitions" INT -2147483648 2147483647;
BA_DEF_ SG_  "GenSigInactiveValue" INT -2147483648 2147483647;
BA_DEF_ SG_  "GenSigSendType" ENUM "Cyclic", "OnWrite", "OnWriteWithRepetition", "OnChange", "OnChangeWithRepetition", "IfActive", "IfActiveWithRepetition", "NoSigSendType", "OnChangeAndIfActive", "OnChangeAndIfActiveWithRepetition";
BA_DEF_ SG_  "GenSigStartValue" INT -2147483648 2147483647;
BA_DEF_ SG_  "NWM-WakeupAllowed" ENUM "No", "Yes";
BA_DEF_ SG_  "GenSigFuncType" ENUM "NoFunction", "MsgCounter", "CRC-8", "XOR", "XOR-2", "DatedBit", "SW-Kl15", "CHK", "Constant", "Protocol", "CRC-8-SAE_J1850", "CRC-32", "DataLength", "DataID", "MsgCounter16", "SOK-Signatur", "Cluster";
BA_DEF_ SG_  "GenSigSwitchedByIgnition" ENUM "No", "Yes";
BA_DEF_ SG_  "Fehlerwert" HEX 0 2147483647;
BA_DEF_ SG_  "GenSigMissingSourceValue" HEX 0 2147483647;
BA_DEF_DEF_REL_  "GenSigTimeoutTime" 0;
BA_DEF_DEF_  "DiagRequest" "No";
BA_DEF_DEF_  "DiagResponse" "No";
BA_DEF_DEF_  "DiagState" "No";
BA_DEF_DEF_  "GenMsgChkConstant" 0;
BA_DEF_DEF_  "GenMsgCycleTime" 0;
BA_DEF_DEF_  "GenMsgCycleTimeFast" 0;
BA_DEF_DEF_  "GenMsgDelayTime" 0;
BA_DEF_DEF_  "GenMsgILSupport" "No";
BA_DEF_DEF_  "GenMsgNrOfRepetition" 0;
BA_DEF_DEF_  "GenMsgPDUConstants" "";
BA_DEF_DEF_  "GenMsgSendType" "NoMsgSendType";
BA_DEF_DEF_  "GenMsgStartDelayTime" 0;
BA_DEF_DEF_  "NmMessage" "No";
BA_DEF_DEF_  "NmhMessage" "No";
BA_DEF_DEF_  "MsgType" "Application";
BA_DEF_DEF_  "VAGTP20_API" 0;
BA_DEF_DEF_  "VAGTP20_DynConnection" "No";
BA_DEF_DEF_  "VAGTP20_DynSetup" "No";
BA_DEF_DEF_  "VAGTP20_StatConnection" "No";
BA_DEF_DEF_  "GenSigActiveRepetitions" 0;
BA_DEF_DEF_  "GenSigInactiveValue" 0;
BA_DEF_DEF_  "GenSigSendType" "NoSigSendType";
BA_DEF_DEF_  "GenSigStartValue" 0;
BA_DEF_DEF_  "NWM-WakeupAllowed" "No";
BA_DEF_DEF_  "GenSigFuncType" "NoFunction";
BA_DEF_DEF_  "GenSigSwitchedByIgnition" "Yes";
BA_DEF_DEF_  "Fehlerwert" 0;
BA_DEF_DEF_  "GenSigMissingSourceValue" 0;
BA_ "GenMsgCycleTime" BO_ 1123 150;
BA_ "GenMsgILSupport" BO_ 1123 1;
BA_ "GenMsgSendType" BO_ 1123 0;
BA_ "GenMsgStartDelayTime" BO_ 1123 50;
BA_ "GenMsgCycleTime" BO_ 1124 150;
BA_ "GenMsgILSupport" BO_ 1124 1;
BA_ "GenMsgSendType" BO_ 1124 0;
BA_ "GenMsgStartDelayTime" BO_ 1124 100;
BA_ "GenMsgCycleTime" BO_ 1125 450;
BA_ "GenMsgILSupport" BO_ 1125 1;
BA_ "GenMsgSendType" BO_ 1125 0;
BA_ "GenMsgCycleTime" BO_ 906 100;
BA_ "GenMsgDelayTime" BO_ 906 10;
BA_ "GenMsgILSupport" BO_ 906 1;
BA_ "GenMsgPDUConstants" BO_ 906 "0xdd,0xd2,0x70,0x3d,0x04,0xcd,0x8a,0x28,0x06,0x4c,0x09,0x14,0x5b,0x22,0x86,0x4b";
BA_ "GenMsgSendType" BO_ 906 0;
BA_ "GenMsgStartDelayTime" BO_ 906 15;
BA_ "GenMsgCycleTime" BO_ 1616 1000;
BA_ "GenMsgDelayTime" BO_ 1616 50;
BA_ "GenMsgILSupport" BO_ 1616 1;
BA_ "GenMsgSendType" BO_ 1616 0;
BA_ "GenMsgStartDelayTime" BO_ 1616 50;
BA_ "GenMsgCycleTime" BO_ 1529 320;
BA_ "GenMsgILSupport" BO_ 1529 1;
BA_ "GenMsgSendType" BO_ 1529 0;
BA_ "GenMsgCycleTime" BO_ 1711 1000;
BA_ "GenMsgDelayTime" BO_ 1711 100;
BA_ "GenMsgILSupport" BO_ 1711 1;
BA_ "GenMsgSendType" BO_ 1711 0;
BA_ "GenMsgCycleTime" BO_ 1440 200;
BA_ "GenMsgILSupport" BO_ 1440 1;
BA_ "GenMsgSendType" BO_ 1440 0;
BA_ "GenMsgCycleTime" BO_ 2527679790 500;
BA_ "GenMsgILSupport" BO_ 2527679790 1;
BA_ "GenMsgSendType" BO_ 2527679790 0;
BA_ "GenMsgCycleTime" BO_ 2527679791 500;
BA_ "GenMsgILSupport" BO_ 2527679791 1;
BA_ "GenMsgSendType" BO_ 2527679791 0;
BA_ "GenMsgCycleTime" BO_ 2527679792 500;
BA_ "GenMsgDelayTime" BO_ 2527679792 50;
BA_ "GenMsgILSupport" BO_ 2527679792 1;
BA_ "GenMsgSendType" BO_ 2527679792 0;
BA_ "GenMsgCycleTime" BO_ 1517 500;
BA_ "GenMsgDelayTime" BO_ 1517 100;
BA_ "GenMsgILSupport" BO_ 1517 1;
BA_ "GenMsgSendType" BO_ 1517 0;
BA_ "GenMsgCycleTime" BO_ 1504 500;
BA_ "GenMsgCycleTimeFast" BO_ 1504 100;
BA_ "GenMsgDelayTime" BO_ 1504 50;
BA_ "GenMsgILSupport" BO_ 1504 1;
BA_ "GenMsgNrOfRepetition" BO_ 1504 5;
BA_ "GenMsgSendType" BO_ 1504 0;
BA_ "GenMsgCycleTime" BO_ 249 500;
BA_ "GenMsgILSupport" BO_ 249 1;
BA_ "GenMsgSendType" BO_ 249 0;
BA_ "GenMsgCycleTime" BO_ 378 100;
BA_ "GenMsgILSupport" BO_ 378 1;
BA_ "GenMsgSendType" BO_ 378 0;
BA_ "GenMsgCycleTime" BO_ 424 20;
BA_ "GenMsgILSupport" BO_ 424 1;
BA_ "GenMsgPDUConstants" BO_ 424 "0x11,0x17,0xbb,0xaa,0xd0,0x83,0xe1,0x8e,0xa3,0x4d,0xef,0x50,0x88,0xa5,0x22,0xf6";
BA_ "GenMsgSendType" BO_ 424 0;
BA_ "GenMsgCycleTime" BO_ 1011 100;
BA_ "GenMsgILSupport" BO_ 1011 1;
BA_ "GenMsgSendType" BO_ 1011 0;
BA_ "GenMsgCycleTime" BO_ 1507 500;
BA_ "GenMsgILSupport" BO_ 1507 1;
BA_ "GenMsgSendType" BO_ 1507 0;
BA_ "GenMsgCycleTime" BO_ 1526 500;
BA_ "GenMsgDelayTime" BO_ 1526 50;
BA_ "GenMsgILSupport" BO_ 1526 1;
BA_ "GenMsgSendType" BO_ 1526 0;
BA_ "GenMsgStartDelayTime" BO_ 1526 780;
BA_ "GenMsgCycleTime" BO_ 873 80;
BA_ "GenMsgILSupport" BO_ 873 1;
BA_ "GenMsgSendType" BO_ 873 0;
BA_ "GenMsgCycleTime" BO_ 2589283634 1000;
BA_ "GenMsgDelayTime" BO_ 2589283634 100;
BA_ "GenMsgILSupport" BO_ 2589283634 1;
BA_ "GenMsgSendType" BO_ 2589283634 0;
BA_ "GenMsgCycleTime" BO_ 2527679657 1000;
BA_ "GenMsgDelayTime" BO_ 2527679657 100;
BA_ "GenMsgILSupport" BO_ 2527679657 1;
BA_ "GenMsgSendType" BO_ 2527679657 0;
BA_ "GenMsgCycleTime" BO_ 201 20;
BA_ "GenMsgILSupport" BO_ 201 1;
BA_ "GenMsgSendType" BO_ 201 0;
BA_ "GenMsgCycleTime" BO_ 2527679651 200;
BA_ "GenMsgILSupport" BO_ 2527679651 1;
BA_ "GenMsgSendType" BO_ 2527679651 0;
BA_ "GenMsgCycleTime" BO_ 980 200;
BA_ "GenMsgCycleTimeFast" BO_ 980 80;
BA_ "GenMsgDelayTime" BO_ 980 40;
BA_ "GenMsgILSupport" BO_ 980 1;
BA_ "GenMsgNrOfRepetition" BO_ 980 5;
BA_ "GenMsgPDUConstants" BO_ 980 "0xc3,0x79,0xbf,0xdb,0xe9,0x11,0x46,0x86,0x69,0xb6,0x9b,0x29,0x15,0x9c,0x45,0x0d";
BA_ "GenMsgSendType" BO_ 980 0;
BA_ "GenMsgCycleTime" BO_ 1467 500;
BA_ "GenMsgILSupport" BO_ 1467 1;
BA_ "GenMsgSendType" BO_ 1467 0;
BA_ "GenMsgCycleTime" BO_ 1710 1000;
BA_ "GenMsgCycleTimeFast" BO_ 1710 100;
BA_ "GenMsgDelayTime" BO_ 1710 50;
BA_ "GenMsgILSupport" BO_ 1710 1;
BA_ "GenMsgNrOfRepetition" BO_ 1710 5;
BA_ "GenMsgSendType" BO_ 1710 0;
BA_ "GenSigSendType" SG_ 1123 PSD_Attribut_1_ID 0;
BA_ "GenSigSendType" SG_ 1123 PSD_Attribut_1_Offset 0;
BA_ "GenSigSendType" SG_ 1123 PSD_Attribut_1_Wert 0;
BA_ "GenSigSendType" SG_ 1123 PSD_Attribut_2_ID 0;
BA_ "GenSigSendType" SG_ 1123 PSD_Attribut_2_Offset 0;
BA_ "GenSigSendType" SG_ 1123 PSD_Attribut_2_Wert 0;
BA_ "GenSigSendType" SG_ 1123 PSD_Attribut_Segment_ID_05 0;
BA_ "Fehlerwert" SG_ 1123 PSD_Attribut_Segment_ID_05 1;
BA_ "GenSigSendType" SG_ 1123 PSD_Attribute_Komplett_05 0;
BA_ "GenSigSendType" SG_ 1123 PSD_Pos_Fahrspur 0;
BA_ "GenSigSendType" SG_ 1123 PSD_Pos_Fehler_Laengsrichtung 0;
BA_ "GenSigSendType" SG_ 1123 PSD_Pos_Inhibitzeit 0;
BA_ "GenSigSendType" SG_ 1123 PSD_Pos_Segment_ID 0;
BA_ "GenSigSendType" SG_ 1123 PSD_Pos_Segmentlaenge 0;
BA_ "GenSigSendType" SG_ 1123 PSD_Pos_Standort_Eindeutig 0;
BA_ "GenSigSwitchedByIgnition" SG_ 1123 PSD_Pos_Standort_Eindeutig 0;
BA_ "GenSigSendType" SG_ 1124 PSD_06_Mux 0;
BA_ "NWM-WakeupAllowed" SG_ 1124 PSD_06_Mux 1;
BA_ "GenSigSwitchedByIgnition" SG_ 1124 PSD_06_Mux 0;
BA_ "Fehlerwert" SG_ 1124 PSD_Attribut_Segment_ID 1;
BA_ "GenSigSwitchedByIgnition" SG_ 1124 PSD_Attribute_Komplett_06 0;
BA_ "GenSigStartValue" SG_ 1124 PSD_Ges_Typ 3;
BA_ "GenSigSwitchedByIgnition" SG_ 1124 PSD_Ges_Typ 0;
BA_ "GenSigSwitchedByIgnition" SG_ 1124 PSD_Steigung_1_Attribute_kompl 0;
BA_ "Fehlerwert" SG_ 1124 PSD_Steigung_1_Segment_ID 1;
BA_ "GenSigSwitchedByIgnition" SG_ 1124 PSD_Steigung_2_Attribute_kompl 0;
BA_ "Fehlerwert" SG_ 1124 PSD_Steigung_2_Segment_ID 1;
BA_ "GenSigSendType" SG_ 1125 PSD_LR_01_MUX 0;
BA_ "GenSigSendType" SG_ 1125 PSD_LR_Profil_Nummer 0;
BA_ "GenSigSwitchedByIgnition" SG_ 1125 PSD_LR_Steigung_3_Vorz 0;
BA_ "GenSigSendType" SG_ 906 QSP_03_BZ 0;
BA_ "GenSigFuncType" SG_ 906 QSP_03_BZ 1;
BA_ "GenSigSendType" SG_ 906 QSP_03_CRC 0;
BA_ "GenSigFuncType" SG_ 906 QSP_03_CRC 2;
BA_ "GenSigSendType" SG_ 906 QSP_Init 0;
BA_ "GenSigStartValue" SG_ 906 QSP_Init 1;
BA_ "GenSigSendType" SG_ 906 QSP_Ist_Moment 0;
BA_ "GenSigStartValue" SG_ 906 QSP_Ist_Moment 511;
BA_ "Fehlerwert" SG_ 906 QSP_Ist_Moment 1023;
BA_ "GenSigSendType" SG_ 906 QSP_Status 0;
BA_ "GenSigStartValue" SG_ 906 QSP_Status 1;
BA_ "GenSigSendType" SG_ 906 QSP_Temperatur_Oel 0;
BA_ "Fehlerwert" SG_ 906 QSP_Temperatur_Oel 127;
BA_ "GenSigSendType" SG_ 906 QSP_Thermische_Belastung 0;
BA_ "Fehlerwert" SG_ 906 QSP_Thermische_Belastung 63;
BA_ "GenSigSendType" SG_ 906 QSP_Warnlampe 3;
BA_ "GenSigSendType" SG_ 1616 RA_AM_Tuning 3;
BA_ "GenSigSwitchedByIgnition" SG_ 1616 RA_AM_Tuning 0;
BA_ "GenSigSendType" SG_ 1616 RA_Frequency 3;
BA_ "GenSigSwitchedByIgnition" SG_ 1616 RA_Frequency 0;
BA_ "GenSigSendType" SG_ 1616 RA_Frequency_unit 3;
BA_ "GenSigSwitchedByIgnition" SG_ 1616 RA_Frequency_unit 0;
BA_ "GenSigSendType" SG_ 1616 RA_PowerAmpOn 3;
BA_ "GenSigSwitchedByIgnition" SG_ 1616 RA_PowerAmpOn 0;
BA_ "GenSigSendType" SG_ 1616 RA_Radio_Error_Flag 3;
BA_ "GenSigSwitchedByIgnition" SG_ 1616 RA_Radio_Error_Flag 0;
BA_ "GenSigSendType" SG_ 1616 RA_Radio_mute 3;
BA_ "GenSigSwitchedByIgnition" SG_ 1616 RA_Radio_mute 0;
BA_ "GenSigSendType" SG_ 1616 RA_Radio_on 3;
BA_ "GenSigSwitchedByIgnition" SG_ 1616 RA_Radio_on 0;
BA_ "GenSigSendType" SG_ 1616 RA_Radio_Surround 3;
BA_ "GenSigSwitchedByIgnition" SG_ 1616 RA_Radio_Surround 0;
BA_ "GenSigSendType" SG_ 1616 RA_VNC_OFF 3;
BA_ "GenSigSwitchedByIgnition" SG_ 1616 RA_VNC_OFF 0;
BA_ "GenSigSendType" SG_ 1529 RDK_angelernt 0;
BA_ "GenSigSwitchedByIgnition" SG_ 1529 RDK_angelernt 0;
BA_ "GenSigSendType" SG_ 1529 RDK_FMVSS138_Lampe 0;
BA_ "GenSigSwitchedByIgnition" SG_ 1529 RDK_FMVSS138_Lampe 0;
BA_ "GenSigSendType" SG_ 1529 RDK_FMVSS138_MIL 0;
BA_ "GenSigSwitchedByIgnition" SG_ 1529 RDK_FMVSS138_MIL 0;
BA_ "GenSigSendType" SG_ 1529 RDK_Kalibrierung 0;
BA_ "GenSigSwitchedByIgnition" SG_ 1529 RDK_Kalibrierung 0;
BA_ "GenSigSendType" SG_ 1529 RDK_Reifendruck_Lampe 0;
BA_ "GenSigSwitchedByIgnition" SG_ 1529 RDK_Reifendruck_Lampe 0;
BA_ "GenSigSendType" SG_ 1529 RDK_Reifentemperatur_Lampe 0;
BA_ "GenSigSwitchedByIgnition" SG_ 1529 RDK_Reifentemperatur_Lampe 0;
BA_ "GenSigSendType" SG_ 1529 RDK_RS_aktiv 0;
BA_ "GenSigSwitchedByIgnition" SG_ 1529 RDK_RS_aktiv 0;
BA_ "GenSigSendType" SG_ 1529 RDK_Text_7 0;
BA_ "GenSigSwitchedByIgnition" SG_ 1529 RDK_Text_7 0;
BA_ "GenSigSendType" SG_ 1529 RDK_W_1_Reifen_HL 0;
BA_ "GenSigSwitchedByIgnition" SG_ 1529 RDK_W_1_Reifen_HL 0;
BA_ "GenSigSendType" SG_ 1529 RDK_W_1_Reifen_HR 0;
BA_ "GenSigSwitchedByIgnition" SG_ 1529 RDK_W_1_Reifen_HR 0;
BA_ "GenSigSendType" SG_ 1529 RDK_W_1_Reifen_VL 0;
BA_ "GenSigSwitchedByIgnition" SG_ 1529 RDK_W_1_Reifen_VL 0;
BA_ "GenSigSendType" SG_ 1529 RDK_W_1_Reifen_VR 0;
BA_ "GenSigSwitchedByIgnition" SG_ 1529 RDK_W_1_Reifen_VR 0;
BA_ "GenSigSendType" SG_ 1529 RDK_W_2_Reifen_HL 0;
BA_ "GenSigSwitchedByIgnition" SG_ 1529 RDK_W_2_Reifen_HL 0;
BA_ "GenSigSendType" SG_ 1529 RDK_W_2_Reifen_HR 0;
BA_ "GenSigSwitchedByIgnition" SG_ 1529 RDK_W_2_Reifen_HR 0;
BA_ "GenSigSendType" SG_ 1529 RDK_W_2_Reifen_VL 0;
BA_ "GenSigSwitchedByIgnition" SG_ 1529 RDK_W_2_Reifen_VL 0;
BA_ "GenSigSendType" SG_ 1529 RDK_W_2_Reifen_VR 0;
BA_ "GenSigSwitchedByIgnition" SG_ 1529 RDK_W_2_Reifen_VR 0;
BA_ "GenSigSendType" SG_ 1529 RDK_Warnungen_02 0;
BA_ "GenSigSwitchedByIgnition" SG_ 1529 RDK_Warnungen_02 0;
BA_ "GenSigSendType" SG_ 1711 RV_Calib_Fehler 3;
BA_ "GenSigSwitchedByIgnition" SG_ 1711 RV_Calib_Fehler 0;
BA_ "GenSigSendType" SG_ 1711 RV_Dark_Screen 3;
BA_ "GenSigSwitchedByIgnition" SG_ 1711 RV_Dark_Screen 0;
BA_ "GenSigSendType" SG_ 1711 RV_Farbe 3;
BA_ "GenSigSwitchedByIgnition" SG_ 1711 RV_Farbe 0;
BA_ "GenSigSendType" SG_ 1711 RV_GL_LWS_Fehler 3;
BA_ "GenSigSwitchedByIgnition" SG_ 1711 RV_GL_LWS_Fehler 0;
BA_ "GenSigSendType" SG_ 1711 RV_GL_side 3;
BA_ "GenSigSendType" SG_ 1711 RV_GL_Trailer_connect 3;
BA_ "GenSigSwitchedByIgnition" SG_ 1711 RV_GL_Trailer_connect 0;
BA_ "GenSigSendType" SG_ 1711 RV_GL_Trunk_open 3;
BA_ "GenSigSwitchedByIgnition" SG_ 1711 RV_GL_Trunk_open 0;
BA_ "GenSigSendType" SG_ 1711 RV_Helligkeit 3;
BA_ "GenSigSwitchedByIgnition" SG_ 1711 RV_Helligkeit 0;
BA_ "GenSigSendType" SG_ 1711 RV_HMI_Mode 3;
BA_ "GenSigSwitchedByIgnition" SG_ 1711 RV_HMI_Mode 0;
BA_ "GenSigSendType" SG_ 1711 RV_Kontrast 3;
BA_ "GenSigSwitchedByIgnition" SG_ 1711 RV_Kontrast 0;
BA_ "GenSigSendType" SG_ 1711 RV_Menu_Item 3;
BA_ "GenSigSwitchedByIgnition" SG_ 1711 RV_Menu_Item 0;
BA_ "GenSigSendType" SG_ 1711 RV_Reinigung_Anf 3;
BA_ "GenSigSwitchedByIgnition" SG_ 1711 RV_Reinigung_Anf 0;
BA_ "GenSigSendType" SG_ 1711 RV_Settings_enabled 3;
BA_ "GenSigSwitchedByIgnition" SG_ 1711 RV_Settings_enabled 0;
BA_ "GenSigSendType" SG_ 1711 RV_System_aktiv 3;
BA_ "GenSigSwitchedByIgnition" SG_ 1711 RV_System_aktiv 0;
BA_ "GenSigSendType" SG_ 1711 RV_Video_on 3;
BA_ "GenSigSwitchedByIgnition" SG_ 1711 RV_Video_on 0;
BA_ "GenSigSendType" SG_ 1711 SV_Video_on 3;
BA_ "GenSigSendType" SG_ 1711 ZFAS_Umfeldbeleuchtung_Anf 3;
BA_ "GenSigSwitchedByIgnition" SG_ 1711 ZFAS_Umfeldbeleuchtung_Anf 0;
BA_ "GenSigSendType" SG_ 1440 LS_defekt 0;
BA_ "GenSigSwitchedByIgnition" SG_ 1440 LS_defekt 0;
BA_ "GenSigSendType" SG_ 1440 LS_Helligkeit_FW 0;
BA_ "GenSigStartValue" SG_ 1440 LS_Helligkeit_FW 1022;
BA_ "GenSigSwitchedByIgnition" SG_ 1440 LS_Helligkeit_FW 0;
BA_ "Fehlerwert" SG_ 1440 LS_Helligkeit_FW 1023;
BA_ "GenSigMissingSourceValue" SG_ 1440 LS_Helligkeit_FW 1023;
BA_ "GenSigSendType" SG_ 1440 LS_Helligkeit_IR 0;
BA_ "GenSigStartValue" SG_ 1440 LS_Helligkeit_IR 254;
BA_ "GenSigSwitchedByIgnition" SG_ 1440 LS_Helligkeit_IR 0;
BA_ "Fehlerwert" SG_ 1440 LS_Helligkeit_IR 255;
BA_ "GenSigMissingSourceValue" SG_ 1440 LS_Helligkeit_IR 255;
BA_ "GenSigSendType" SG_ 1440 LS_Verbau 0;
BA_ "GenSigSwitchedByIgnition" SG_ 1440 LS_Verbau 0;
BA_ "GenSigSendType" SG_ 1440 RLS_Vorfeldhelligkeit_Boost 0;
BA_ "GenSigStartValue" SG_ 1440 RLS_Vorfeldhelligkeit_Boost 15;
BA_ "GenSigSwitchedByIgnition" SG_ 1440 RLS_Vorfeldhelligkeit_Boost 0;
BA_ "GenSigSendType" SG_ 1440 RS_defekt 0;
BA_ "GenSigSwitchedByIgnition" SG_ 1440 RS_defekt 0;
BA_ "GenSigSendType" SG_ 1440 RS_Regenmenge 0;
BA_ "GenSigStartValue" SG_ 1440 RS_Regenmenge 14;
BA_ "GenSigSwitchedByIgnition" SG_ 1440 RS_Regenmenge 0;
BA_ "Fehlerwert" SG_ 1440 RS_Regenmenge 15;
BA_ "GenSigMissingSourceValue" SG_ 1440 RS_Regenmenge 15;
BA_ "GenSigSendType" SG_ 1440 RS_Verbau 0;
BA_ "GenSigSwitchedByIgnition" SG_ 1440 RS_Verbau 0;
BA_ "GenSigSendType" SG_ 1440 RS_Verglasung_schliessen 0;
BA_ "GenSigSwitchedByIgnition" SG_ 1440 RS_Verglasung_schliessen 0;
BA_ "GenSigSendType" SG_ 1440 RS_Wischergeschwindigkeit 0;
BA_ "GenSigSwitchedByIgnition" SG_ 1440 RS_Wischergeschwindigkeit 0;
BA_ "GenSigSendType" SG_ 2527679790 RTM_Fehlerstatus 0;
BA_ "GenSigSwitchedByIgnition" SG_ 2527679790 RTM_Fehlerstatus 0;
BA_ "GenSigSendType" SG_ 2527679790 RTM_IstModus 0;
BA_ "GenSigSwitchedByIgnition" SG_ 2527679790 RTM_IstModus 0;
BA_ "GenSigSendType" SG_ 2527679790 RTM_OTA_Download_Process 0;
BA_ "GenSigStartValue" SG_ 2527679790 RTM_OTA_Download_Process 254;
BA_ "GenSigSwitchedByIgnition" SG_ 2527679790 RTM_OTA_Download_Process 0;
BA_ "Fehlerwert" SG_ 2527679790 RTM_OTA_Download_Process 255;
BA_ "GenSigSendType" SG_ 2527679790 RTM_OTA_Download_Size 0;
BA_ "GenSigStartValue" SG_ 2527679790 RTM_OTA_Download_Size 254;
BA_ "GenSigSwitchedByIgnition" SG_ 2527679790 RTM_OTA_Download_Size 0;
BA_ "Fehlerwert" SG_ 2527679790 RTM_OTA_Download_Size 255;
BA_ "GenSigSendType" SG_ 2527679790 RTM_OTA_Download_Speed 0;
BA_ "GenSigSwitchedByIgnition" SG_ 2527679790 RTM_OTA_Download_Speed 0;
BA_ "GenSigSendType" SG_ 2527679790 RTM_OTA_InstallDuration 0;
BA_ "GenSigStartValue" SG_ 2527679790 RTM_OTA_InstallDuration 31;
BA_ "GenSigSwitchedByIgnition" SG_ 2527679790 RTM_OTA_InstallDuration 0;
BA_ "GenSigSendType" SG_ 2527679790 RTM_OTA_InstallPrecondition 0;
BA_ "GenSigSwitchedByIgnition" SG_ 2527679790 RTM_OTA_InstallPrecondition 0;
BA_ "GenSigSendType" SG_ 2527679790 RTM_OTA_InstallProcess 0;
BA_ "GenSigSwitchedByIgnition" SG_ 2527679790 RTM_OTA_InstallProcess 0;
BA_ "GenSigSendType" SG_ 2527679790 RTM_OTA_SignalStrength 0;
BA_ "GenSigSwitchedByIgnition" SG_ 2527679790 RTM_OTA_SignalStrength 0;
BA_ "GenSigSendType" SG_ 2527679791 RTM_03_Dummy 0;
BA_ "GenSigSwitchedByIgnition" SG_ 2527679791 RTM_03_Dummy 0;
BA_ "GenSigSendType" SG_ 2527679792 MIB_OTA_Comfirmation 3;
BA_ "GenSigSwitchedByIgnition" SG_ 2527679792 MIB_OTA_Comfirmation 0;
BA_ "GenSigSendType" SG_ 1517 SAD2_Deckel_Lage 0;
BA_ "GenSigSwitchedByIgnition" SG_ 1517 SAD2_Deckel_Lage 0;
BA_ "GenSigSendType" SG_ 1517 SAD2_Deckel_normiert 3;
BA_ "GenSigSwitchedByIgnition" SG_ 1517 SAD2_Deckel_normiert 0;
BA_ "GenSigSendType" SG_ 1517 SAD2_Deckel_Position 3;
BA_ "GenSigStartValue" SG_ 1517 SAD2_Deckel_Position 126;
BA_ "GenSigSwitchedByIgnition" SG_ 1517 SAD2_Deckel_Position 0;
BA_ "GenSigSendType" SG_ 1517 SAD2_Deckel_Thermoschutz 3;
BA_ "GenSigSwitchedByIgnition" SG_ 1517 SAD2_Deckel_Thermoschutz 0;
BA_ "GenSigSendType" SG_ 1517 SAD2_Deckel_UEKB_aktiv 3;
BA_ "GenSigSwitchedByIgnition" SG_ 1517 SAD2_Deckel_UEKB_aktiv 0;
BA_ "GenSigSendType" SG_ 1517 SAD2_Rollo_Lage 0;
BA_ "GenSigSwitchedByIgnition" SG_ 1517 SAD2_Rollo_Lage 0;
BA_ "GenSigSendType" SG_ 1517 SAD2_Rollo_normiert 3;
BA_ "GenSigSwitchedByIgnition" SG_ 1517 SAD2_Rollo_normiert 0;
BA_ "GenSigSendType" SG_ 1517 SAD2_Rollo_Position 0;
BA_ "GenSigStartValue" SG_ 1517 SAD2_Rollo_Position 126;
BA_ "GenSigSwitchedByIgnition" SG_ 1517 SAD2_Rollo_Position 0;
BA_ "GenSigSendType" SG_ 1517 SAD2_Rollo_Thermoschutz 3;
BA_ "GenSigSwitchedByIgnition" SG_ 1517 SAD2_Rollo_Thermoschutz 0;
BA_ "GenSigSendType" SG_ 1517 SAD2_Rollo_UEKB_aktiv 3;
BA_ "GenSigSwitchedByIgnition" SG_ 1517 SAD2_Rollo_UEKB_aktiv 0;
BA_ "GenSigSendType" SG_ 1504 MD1_Lage 0;
BA_ "GenSigSwitchedByIgnition" SG_ 1504 MD1_Lage 0;
BA_ "GenSigSendType" SG_ 1504 MD1_Position 3;
BA_ "GenSigStartValue" SG_ 1504 MD1_Position 126;
BA_ "GenSigSwitchedByIgnition" SG_ 1504 MD1_Position 0;
BA_ "GenSigSendType" SG_ 1504 MD3_Lage 0;
BA_ "GenSigSwitchedByIgnition" SG_ 1504 MD3_Lage 0;
BA_ "GenSigSendType" SG_ 1504 MD3_Position 0;
BA_ "GenSigSwitchedByIgnition" SG_ 1504 MD3_Position 0;
BA_ "GenSigSendType" SG_ 1504 MRollo_Lage 0;
BA_ "GenSigSwitchedByIgnition" SG_ 1504 MRollo_Lage 0;
BA_ "GenSigSendType" SG_ 1504 MRollo_Position 0;
BA_ "GenSigStartValue" SG_ 1504 MRollo_Position 126;
BA_ "GenSigSwitchedByIgnition" SG_ 1504 MRollo_Position 0;
BA_ "GenSigSendType" SG_ 1504 Rollo_normiert 3;
BA_ "GenSigSwitchedByIgnition" SG_ 1504 Rollo_normiert 0;
BA_ "GenSigSendType" SG_ 1504 Rollo_Thermoschutz 3;
BA_ "GenSigSwitchedByIgnition" SG_ 1504 Rollo_Thermoschutz 0;
BA_ "GenSigSendType" SG_ 1504 Rollo_UEKB_aktiv 3;
BA_ "GenSigSwitchedByIgnition" SG_ 1504 Rollo_UEKB_aktiv 0;
BA_ "GenSigSendType" SG_ 1504 SAD_Anf_ESC_Zuschaltung 3;
BA_ "GenSigSwitchedByIgnition" SG_ 1504 SAD_Anf_ESC_Zuschaltung 0;
BA_ "GenSigSendType" SG_ 1504 SAD_normiert 3;
BA_ "GenSigSwitchedByIgnition" SG_ 1504 SAD_normiert 0;
BA_ "GenSigSendType" SG_ 1504 SAD_ParityBit 0;
BA_ "GenSigSwitchedByIgnition" SG_ 1504 SAD_ParityBit 0;
BA_ "GenSigActiveRepetitions" SG_ 1504 SAD_Taster_Deckel_hi 5;
BA_ "GenSigSendType" SG_ 1504 SAD_Taster_Deckel_hi 4;
BA_ "GenSigSwitchedByIgnition" SG_ 1504 SAD_Taster_Deckel_hi 0;
BA_ "GenSigActiveRepetitions" SG_ 1504 SAD_Taster_Deckel_vo 5;
BA_ "GenSigSendType" SG_ 1504 SAD_Taster_Deckel_vo 4;
BA_ "GenSigSwitchedByIgnition" SG_ 1504 SAD_Taster_Deckel_vo 0;
BA_ "GenSigActiveRepetitions" SG_ 1504 SAD_Taster_Rollo_hi 5;
BA_ "GenSigSendType" SG_ 1504 SAD_Taster_Rollo_hi 4;
BA_ "GenSigSwitchedByIgnition" SG_ 1504 SAD_Taster_Rollo_hi 0;
BA_ "GenSigActiveRepetitions" SG_ 1504 SAD_Taster_Rollo_vo 5;
BA_ "GenSigSendType" SG_ 1504 SAD_Taster_Rollo_vo 4;
BA_ "GenSigSwitchedByIgnition" SG_ 1504 SAD_Taster_Rollo_vo 0;
BA_ "GenSigActiveRepetitions" SG_ 1504 SAD_Text 5;
BA_ "GenSigSendType" SG_ 1504 SAD_Text 4;
BA_ "GenSigSwitchedByIgnition" SG_ 1504 SAD_Text 0;
BA_ "GenSigSendType" SG_ 1504 SAD_Thermoschutz 3;
BA_ "GenSigSwitchedByIgnition" SG_ 1504 SAD_Thermoschutz 0;
BA_ "GenSigSendType" SG_ 1504 SAD_ToggleBit 0;
BA_ "GenSigSwitchedByIgnition" SG_ 1504 SAD_ToggleBit 0;
BA_ "GenSigSendType" SG_ 1504 SAD_UEKB_aktiv 3;
BA_ "GenSigSwitchedByIgnition" SG_ 1504 SAD_UEKB_aktiv 0;
BA_ "GenSigSendType" SG_ 249 SARA_Nickwinkel 0;
BA_ "GenSigStartValue" SG_ 249 SARA_Nickwinkel 8191;
BA_ "GenSigSwitchedByIgnition" SG_ 249 SARA_Nickwinkel 0;
BA_ "GenSigSendType" SG_ 249 SARA_QBit_Nickwinkel 0;
BA_ "GenSigStartValue" SG_ 249 SARA_QBit_Nickwinkel 1;
BA_ "GenSigSwitchedByIgnition" SG_ 249 SARA_QBit_Nickwinkel 0;
BA_ "GenSigSendType" SG_ 249 SARA_QBit_Wankwinkel 0;
BA_ "GenSigStartValue" SG_ 249 SARA_QBit_Wankwinkel 1;
BA_ "GenSigSwitchedByIgnition" SG_ 249 SARA_QBit_Wankwinkel 0;
BA_ "GenSigSendType" SG_ 249 SARA_Wankwinkel 0;
BA_ "GenSigStartValue" SG_ 249 SARA_Wankwinkel 8191;
BA_ "GenSigSwitchedByIgnition" SG_ 249 SARA_Wankwinkel 0;
BA_ "GenSigSendType" SG_ 378 SARA_Accel_X_010_02 0;
BA_ "GenSigStartValue" SG_ 378 SARA_Accel_X_010_02 32768;
BA_ "GenSigSwitchedByIgnition" SG_ 378 SARA_Accel_X_010_02 0;
BA_ "Fehlerwert" SG_ 378 SARA_Accel_X_010_02 65535;
BA_ "GenSigSendType" SG_ 378 SARA_Accel_Y_010_02 0;
BA_ "GenSigStartValue" SG_ 378 SARA_Accel_Y_010_02 32768;
BA_ "GenSigSwitchedByIgnition" SG_ 378 SARA_Accel_Y_010_02 0;
BA_ "Fehlerwert" SG_ 378 SARA_Accel_Y_010_02 65535;
BA_ "GenSigSendType" SG_ 378 SARA_CF_Accel_X_010_02 0;
BA_ "GenSigStartValue" SG_ 378 SARA_CF_Accel_X_010_02 4;
BA_ "GenSigSwitchedByIgnition" SG_ 378 SARA_CF_Accel_X_010_02 0;
BA_ "GenSigSendType" SG_ 378 SARA_CF_Accel_Y_010_02 0;
BA_ "GenSigStartValue" SG_ 378 SARA_CF_Accel_Y_010_02 4;
BA_ "GenSigSwitchedByIgnition" SG_ 378 SARA_CF_Accel_Y_010_02 0;
BA_ "GenSigSendType" SG_ 378 SARA_CF_Omega_Z_010_02 0;
BA_ "GenSigStartValue" SG_ 378 SARA_CF_Omega_Z_010_02 4;
BA_ "GenSigSwitchedByIgnition" SG_ 378 SARA_CF_Omega_Z_010_02 0;
BA_ "GenSigSendType" SG_ 378 SARA_Omega_Z_010_02 0;
BA_ "GenSigStartValue" SG_ 378 SARA_Omega_Z_010_02 32768;
BA_ "GenSigSwitchedByIgnition" SG_ 378 SARA_Omega_Z_010_02 0;
BA_ "Fehlerwert" SG_ 378 SARA_Omega_Z_010_02 65535;
BA_ "GenSigSendType" SG_ 424 SARA_11_BZ 0;
BA_ "GenSigFuncType" SG_ 424 SARA_11_BZ 1;
BA_ "GenSigSwitchedByIgnition" SG_ 424 SARA_11_BZ 0;
BA_ "GenSigSendType" SG_ 424 SARA_11_CRC 0;
BA_ "GenSigFuncType" SG_ 424 SARA_11_CRC 2;
BA_ "GenSigSwitchedByIgnition" SG_ 424 SARA_11_CRC 0;
BA_ "GenSigSendType" SG_ 424 SARA_Accel_X_r 0;
BA_ "GenSigStartValue" SG_ 424 SARA_Accel_X_r 4096;
BA_ "GenSigSwitchedByIgnition" SG_ 424 SARA_Accel_X_r 0;
BA_ "Fehlerwert" SG_ 424 SARA_Accel_X_r 8191;
BA_ "GenSigSendType" SG_ 424 SARA_Accel_Y_r 0;
BA_ "GenSigStartValue" SG_ 424 SARA_Accel_Y_r 4096;
BA_ "GenSigSwitchedByIgnition" SG_ 424 SARA_Accel_Y_r 0;
BA_ "Fehlerwert" SG_ 424 SARA_Accel_Y_r 8191;
BA_ "GenSigSendType" SG_ 424 SARA_CF_Accel_X_r 0;
BA_ "GenSigStartValue" SG_ 424 SARA_CF_Accel_X_r 4;
BA_ "GenSigSwitchedByIgnition" SG_ 424 SARA_CF_Accel_X_r 0;
BA_ "GenSigSendType" SG_ 424 SARA_CF_Accel_Y_r 0;
BA_ "GenSigStartValue" SG_ 424 SARA_CF_Accel_Y_r 4;
BA_ "GenSigSwitchedByIgnition" SG_ 424 SARA_CF_Accel_Y_r 0;
BA_ "GenSigSendType" SG_ 424 SARA_CF_Omega_Z_r 0;
BA_ "GenSigStartValue" SG_ 424 SARA_CF_Omega_Z_r 4;
BA_ "GenSigSwitchedByIgnition" SG_ 424 SARA_CF_Omega_Z_r 0;
BA_ "GenSigSendType" SG_ 424 SARA_Omega_Z_r 0;
BA_ "GenSigStartValue" SG_ 424 SARA_Omega_Z_r 4096;
BA_ "GenSigSwitchedByIgnition" SG_ 424 SARA_Omega_Z_r 0;
BA_ "Fehlerwert" SG_ 424 SARA_Omega_Z_r 8191;
BA_ "GenSigSendType" SG_ 1011 SCR_01_BZ 0;
BA_ "GenSigFuncType" SG_ 1011 SCR_01_BZ 1;
BA_ "GenSigSwitchedByIgnition" SG_ 1011 SCR_01_BZ 0;
BA_ "GenSigSendType" SG_ 1011 SCR_Dosierpumpe_Drehzahl 0;
BA_ "GenSigStartValue" SG_ 1011 SCR_Dosierpumpe_Drehzahl 2046;
BA_ "GenSigSwitchedByIgnition" SG_ 1011 SCR_Dosierpumpe_Drehzahl 0;
BA_ "Fehlerwert" SG_ 1011 SCR_Dosierpumpe_Drehzahl 2047;
BA_ "GenSigSendType" SG_ 1011 SCR_Druck 0;
BA_ "GenSigStartValue" SG_ 1011 SCR_Druck 1022;
BA_ "GenSigSwitchedByIgnition" SG_ 1011 SCR_Druck 0;
BA_ "Fehlerwert" SG_ 1011 SCR_Druck 1023;
BA_ "GenSigSendType" SG_ 1011 SCR_Level_Aktivtank 0;
BA_ "GenSigStartValue" SG_ 1011 SCR_Level_Aktivtank 1022;
BA_ "GenSigSwitchedByIgnition" SG_ 1011 SCR_Level_Aktivtank 0;
BA_ "Fehlerwert" SG_ 1011 SCR_Level_Aktivtank 1023;
BA_ "GenSigSendType" SG_ 1011 SCR_Level_ReadAbove 0;
BA_ "GenSigSwitchedByIgnition" SG_ 1011 SCR_Level_ReadAbove 0;
BA_ "GenSigSendType" SG_ 1011 SCR_QBit_Level_Aktivtank_02 0;
BA_ "GenSigStartValue" SG_ 1011 SCR_QBit_Level_Aktivtank_02 1;
BA_ "GenSigSwitchedByIgnition" SG_ 1011 SCR_QBit_Level_Aktivtank_02 0;
BA_ "GenSigSendType" SG_ 1011 SCR_Sent_Level_Aktivtank 0;
BA_ "GenSigStartValue" SG_ 1011 SCR_Sent_Level_Aktivtank 1022;
BA_ "GenSigSwitchedByIgnition" SG_ 1011 SCR_Sent_Level_Aktivtank 0;
BA_ "GenSigSendType" SG_ 1011 SCR_Sent_Levelsignal_Status 0;
BA_ "GenSigStartValue" SG_ 1011 SCR_Sent_Levelsignal_Status 7;
BA_ "GenSigSwitchedByIgnition" SG_ 1011 SCR_Sent_Levelsignal_Status 0;
BA_ "Fehlerwert" SG_ 1011 SCR_Sent_Levelsignal_Status 6;
BA_ "GenSigSendType" SG_ 1507 SCR_02_BZ 0;
BA_ "GenSigFuncType" SG_ 1507 SCR_02_BZ 1;
BA_ "GenSigSwitchedByIgnition" SG_ 1507 SCR_02_BZ 0;
BA_ "GenSigSendType" SG_ 1507 SCR_Guetesensor 0;
BA_ "GenSigStartValue" SG_ 1507 SCR_Guetesensor 1022;
BA_ "GenSigSwitchedByIgnition" SG_ 1507 SCR_Guetesensor 0;
BA_ "Fehlerwert" SG_ 1507 SCR_Guetesensor 1023;
BA_ "GenSigSendType" SG_ 1507 SCR_Heizkreis_3_Strom 0;
BA_ "GenSigStartValue" SG_ 1507 SCR_Heizkreis_3_Strom 254;
BA_ "GenSigSwitchedByIgnition" SG_ 1507 SCR_Heizkreis_3_Strom 0;
BA_ "Fehlerwert" SG_ 1507 SCR_Heizkreis_3_Strom 255;
BA_ "GenSigSendType" SG_ 1507 SCR_Leitungsheizung_Strom 0;
BA_ "GenSigStartValue" SG_ 1507 SCR_Leitungsheizung_Strom 254;
BA_ "GenSigSwitchedByIgnition" SG_ 1507 SCR_Leitungsheizung_Strom 0;
BA_ "Fehlerwert" SG_ 1507 SCR_Leitungsheizung_Strom 255;
BA_ "GenSigSendType" SG_ 1507 SCR_Tankheizung_Strom 0;
BA_ "GenSigStartValue" SG_ 1507 SCR_Tankheizung_Strom 254;
BA_ "GenSigSwitchedByIgnition" SG_ 1507 SCR_Tankheizung_Strom 0;
BA_ "Fehlerwert" SG_ 1507 SCR_Tankheizung_Strom 255;
BA_ "GenSigSendType" SG_ 1507 SCR_Temp_Aktivtank 0;
BA_ "GenSigStartValue" SG_ 1507 SCR_Temp_Aktivtank 254;
BA_ "GenSigSwitchedByIgnition" SG_ 1507 SCR_Temp_Aktivtank 0;
BA_ "Fehlerwert" SG_ 1507 SCR_Temp_Aktivtank 255;
BA_ "GenSigSendType" SG_ 1507 SCR_Temp_Passivtank 0;
BA_ "GenSigStartValue" SG_ 1507 SCR_Temp_Passivtank 254;
BA_ "GenSigSwitchedByIgnition" SG_ 1507 SCR_Temp_Passivtank 0;
BA_ "Fehlerwert" SG_ 1507 SCR_Temp_Passivtank 255;
BA_ "GenSigSendType" SG_ 1507 SCR_Transferpumpe_Strom 0;
BA_ "GenSigStartValue" SG_ 1507 SCR_Transferpumpe_Strom 254;
BA_ "GenSigSwitchedByIgnition" SG_ 1507 SCR_Transferpumpe_Strom 0;
BA_ "Fehlerwert" SG_ 1507 SCR_Transferpumpe_Strom 255;
BA_ "GenSigSendType" SG_ 1526 SCR_05_BZ 0;
BA_ "GenSigFuncType" SG_ 1526 SCR_05_BZ 1;
BA_ "GenSigSwitchedByIgnition" SG_ 1526 SCR_05_BZ 0;
BA_ "GenSigSendType" SG_ 1526 SCR_DEF_Qualitaet_Medium 3;
BA_ "GenSigSwitchedByIgnition" SG_ 1526 SCR_DEF_Qualitaet_Medium 0;
BA_ "GenSigSendType" SG_ 1526 SCR_ECU_Datensatz_Status 3;
BA_ "GenSigStartValue" SG_ 1526 SCR_ECU_Datensatz_Status 3;
BA_ "GenSigSwitchedByIgnition" SG_ 1526 SCR_ECU_Datensatz_Status 0;
BA_ "GenSigSendType" SG_ 1526 SCR_HAL_Sensorik_Status 3;
BA_ "GenSigStartValue" SG_ 1526 SCR_HAL_Sensorik_Status 15;
BA_ "GenSigSwitchedByIgnition" SG_ 1526 SCR_HAL_Sensorik_Status 0;
BA_ "GenSigSendType" SG_ 1526 SCR_Level_Aktivtank_OOR4Quality 3;
BA_ "GenSigSwitchedByIgnition" SG_ 1526 SCR_Level_Aktivtank_OOR4Quality 0;
BA_ "GenSigSendType" SG_ 1526 SCR_Level_Aktivtank_OOR_minus 3;
BA_ "GenSigSwitchedByIgnition" SG_ 1526 SCR_Level_Aktivtank_OOR_minus 0;
BA_ "GenSigSendType" SG_ 1526 SCR_QBit_Qualitaet 0;
BA_ "GenSigStartValue" SG_ 1526 SCR_QBit_Qualitaet 1;
BA_ "GenSigSwitchedByIgnition" SG_ 1526 SCR_QBit_Qualitaet 0;
BA_ "GenSigSendType" SG_ 1526 SCR_Sent_1_elektrischer_Status 3;
BA_ "GenSigStartValue" SG_ 1526 SCR_Sent_1_elektrischer_Status 15;
BA_ "GenSigSwitchedByIgnition" SG_ 1526 SCR_Sent_1_elektrischer_Status 0;
BA_ "GenSigSendType" SG_ 1526 SCR_Sent_1_Signalstatus 3;
BA_ "GenSigStartValue" SG_ 1526 SCR_Sent_1_Signalstatus 3;
BA_ "GenSigSwitchedByIgnition" SG_ 1526 SCR_Sent_1_Signalstatus 0;
BA_ "GenSigSendType" SG_ 1526 SCR_Sent_2_elektrischer_Status 3;
BA_ "GenSigStartValue" SG_ 1526 SCR_Sent_2_elektrischer_Status 15;
BA_ "GenSigSwitchedByIgnition" SG_ 1526 SCR_Sent_2_elektrischer_Status 0;
BA_ "GenSigSendType" SG_ 1526 SCR_Sent_2_Signalstatus 3;
BA_ "GenSigStartValue" SG_ 1526 SCR_Sent_2_Signalstatus 3;
BA_ "GenSigSwitchedByIgnition" SG_ 1526 SCR_Sent_2_Signalstatus 0;
BA_ "GenSigSendType" SG_ 1526 SCR_Sent_Levelsensor 3;
BA_ "GenSigStartValue" SG_ 1526 SCR_Sent_Levelsensor 7;
BA_ "GenSigSwitchedByIgnition" SG_ 1526 SCR_Sent_Levelsensor 0;
BA_ "GenSigSendType" SG_ 1526 SCR_Sent_Qualitaetssensor 3;
BA_ "GenSigStartValue" SG_ 1526 SCR_Sent_Qualitaetssensor 7;
BA_ "GenSigSwitchedByIgnition" SG_ 1526 SCR_Sent_Qualitaetssensor 0;
BA_ "GenSigSendType" SG_ 1526 SCR_Sent_Temperatursensor 3;
BA_ "GenSigStartValue" SG_ 1526 SCR_Sent_Temperatursensor 7;
BA_ "GenSigSwitchedByIgnition" SG_ 1526 SCR_Sent_Temperatursensor 0;
BA_ "GenSigSendType" SG_ 1526 SCR_Steuergeraet_Bus_Status 3;
BA_ "GenSigStartValue" SG_ 1526 SCR_Steuergeraet_Bus_Status 3;
BA_ "GenSigSwitchedByIgnition" SG_ 1526 SCR_Steuergeraet_Bus_Status 0;
BA_ "GenSigSendType" SG_ 1526 SCR_Steuergeraet_Defekt_Status 3;
BA_ "GenSigStartValue" SG_ 1526 SCR_Steuergeraet_Defekt_Status 3;
BA_ "GenSigSwitchedByIgnition" SG_ 1526 SCR_Steuergeraet_Defekt_Status 0;
BA_ "GenSigSendType" SG_ 1526 SCR_Steuergeraet_Heizung_Status 3;
BA_ "GenSigStartValue" SG_ 1526 SCR_Steuergeraet_Heizung_Status 3;
BA_ "GenSigSwitchedByIgnition" SG_ 1526 SCR_Steuergeraet_Heizung_Status 0;
BA_ "GenSigSendType" SG_ 1526 SCR_Steuergeraet_Pumpe_Status 3;
BA_ "GenSigStartValue" SG_ 1526 SCR_Steuergeraet_Pumpe_Status 3;
BA_ "GenSigSwitchedByIgnition" SG_ 1526 SCR_Steuergeraet_Pumpe_Status 0;
BA_ "GenSigSendType" SG_ 1526 SCR_Steuergeraet_Relais_Status 3;
BA_ "GenSigStartValue" SG_ 1526 SCR_Steuergeraet_Relais_Status 3;
BA_ "GenSigSwitchedByIgnition" SG_ 1526 SCR_Steuergeraet_Relais_Status 0;
BA_ "GenSigSendType" SG_ 1526 SCR_Temp_DEF2_Sensor_Status 3;
BA_ "GenSigStartValue" SG_ 1526 SCR_Temp_DEF2_Sensor_Status 7;
BA_ "GenSigSwitchedByIgnition" SG_ 1526 SCR_Temp_DEF2_Sensor_Status 0;
BA_ "GenSigSendType" SG_ 873 SDF2_Pos_AnzHauptspuren 0;
BA_ "GenSigStartValue" SG_ 873 SDF2_Pos_AnzHauptspuren 15;
BA_ "GenSigSendType" SG_ 873 SDF2_Pos_AnzRampenLinks 0;
BA_ "GenSigStartValue" SG_ 873 SDF2_Pos_AnzRampenLinks 7;
BA_ "GenSigSendType" SG_ 873 SDF2_Pos_AnzRampenRechts 0;
BA_ "GenSigStartValue" SG_ 873 SDF2_Pos_AnzRampenRechts 7;
BA_ "GenSigSendType" SG_ 873 SDF2_Pos_Distanz_Rampe_links 0;
BA_ "GenSigStartValue" SG_ 873 SDF2_Pos_Distanz_Rampe_links 63;
BA_ "GenSigSendType" SG_ 873 SDF2_Pos_Distanz_Rampe_rechts 0;
BA_ "GenSigStartValue" SG_ 873 SDF2_Pos_Distanz_Rampe_rechts 63;
BA_ "GenSigSendType" SG_ 873 SDF2_Pos_Fehler_Laengsrichtung 0;
BA_ "GenSigSendType" SG_ 873 SDF2_Pos_GueteZuordnung 0;
BA_ "GenSigStartValue" SG_ 873 SDF2_Pos_GueteZuordnung 15;
BA_ "GenSigSendType" SG_ 873 SDF2_Pos_Inhibitzeit 0;
BA_ "GenSigSendType" SG_ 873 SDF2_Pos_Offset 0;
BA_ "GenSigSendType" SG_ 873 SDF2_Pos_Segment_ID 0;
BA_ "GenSigSendType" SG_ 873 SDF2_Pos_Spurnummer 0;
BA_ "GenSigStartValue" SG_ 873 SDF2_Pos_Spurnummer 15;
BA_ "GenSigSendType" SG_ 873 SDF2_Pos_Spurtype 0;
BA_ "GenSigStartValue" SG_ 873 SDF2_Pos_Spurtype 31;
BA_ "GenSigSendType" SG_ 873 SDF2_Pos_Standort_Eindeutig 0;
BA_ "GenSigSendType" SG_ 2589283634 SM_LAPP_Aussenlicht_aktiv 3;
BA_ "GenSigSendType" SG_ 2589283634 SM_LAPP_Demo_ABBL_Anf 3;
BA_ "GenSigSendType" SG_ 2589283634 SM_LAPP_Demo_Autobahnmodus_Anf 3;
BA_ "GenSigSendType" SG_ 2589283634 SM_LAPP_Demo_Distanz_01 3;
BA_ "GenSigSendType" SG_ 2589283634 SM_LAPP_Demo_Distanz_02 3;
BA_ "GenSigSendType" SG_ 2589283634 SM_LAPP_Demo_DKL_Anf 3;
BA_ "GenSigSendType" SG_ 2589283634 SM_LAPP_Demo_Einschalteffekt_Anf 3;
BA_ "GenSigSendType" SG_ 2589283634 SM_LAPP_Demo_FL_Anf 3;
BA_ "GenSigSendType" SG_ 2589283634 SM_LAPP_Demo_MaLi_Anf 3;
BA_ "GenSigSendType" SG_ 2589283634 SM_LAPP_Demo_Objekt_01_Anf 3;
BA_ "GenSigSendType" SG_ 2589283634 SM_LAPP_Demo_Objekt_02_Anf 3;
BA_ "GenSigSendType" SG_ 2589283634 SM_LAPP_Demo_Schildentbl_01_Anf 3;
BA_ "GenSigSendType" SG_ 2589283634 SM_LAPP_Demo_Schildentbl_02_Anf 3;
BA_ "GenSigSendType" SG_ 2589283634 SM_LAPP_Demo_Winkel_Hor_01 3;
BA_ "GenSigStartValue" SG_ 2589283634 SM_LAPP_Demo_Winkel_Hor_01 512;
BA_ "GenSigSendType" SG_ 2589283634 SM_LAPP_Demo_Winkel_Hor_02 3;
BA_ "GenSigStartValue" SG_ 2589283634 SM_LAPP_Demo_Winkel_Hor_02 512;
BA_ "GenSigSendType" SG_ 2589283634 SM_LAPP_Demo_Winkel_Vert_01 3;
BA_ "GenSigStartValue" SG_ 2589283634 SM_LAPP_Demo_Winkel_Vert_01 128;
BA_ "GenSigSendType" SG_ 2589283634 SM_LAPP_Demo_Winkel_Vert_02 3;
BA_ "GenSigStartValue" SG_ 2589283634 SM_LAPP_Demo_Winkel_Vert_02 128;
BA_ "GenSigSendType" SG_ 2589283634 SM_LAPP_Verbindungsstatus 3;
BA_ "GenSigSendType" SG_ 2527679657 SM_LAPP_Demo_AbbiegeWa_Anf 3;
BA_ "GenSigSendType" SG_ 2527679657 SM_LAPP_Demo_AbsAss_Anf 3;
BA_ "GenSigSendType" SG_ 2527679657 SM_LAPP_Demo_AccAss_Anf 3;
BA_ "GenSigSendType" SG_ 2527679657 SM_LAPP_Demo_advCH_F01_Anf 3;
BA_ "GenSigSendType" SG_ 2527679657 SM_LAPP_Demo_advLH_F01_Anf 3;
BA_ "GenSigSendType" SG_ 2527679657 SM_LAPP_Demo_BauLi_Anf 3;
BA_ "GenSigSendType" SG_ 2527679657 SM_LAPP_Demo_BeAss_Anf 3;
BA_ "GenSigSendType" SG_ 2527679657 SM_LAPP_Demo_CH_F01_Anf 3;
BA_ "GenSigSendType" SG_ 2527679657 SM_LAPP_Demo_CH_H01_Anf 3;
BA_ "GenSigSendType" SG_ 2527679657 SM_LAPP_Demo_EffAss_Anf 3;
BA_ "GenSigSendType" SG_ 2527679657 SM_LAPP_Demo_LH_F01_Anf 3;
BA_ "GenSigSendType" SG_ 2527679657 SM_LAPP_Demo_LH_H01_Anf 3;
BA_ "GenSigSendType" SG_ 2527679657 SM_LAPP_Demo_PreSAss_Anf 3;
BA_ "GenSigSendType" SG_ 2527679657 SM_LAPP_Demo_RouLi_Anf 3;
BA_ "GenSigSendType" SG_ 2527679657 SM_LAPP_Demo_SitLi_Anf 3;
BA_ "GenSigSendType" SG_ 2527679657 SM_LAPP_Demo_SL_Anf 3;
BA_ "GenSigSendType" SG_ 2527679657 SM_LAPP_Demo_SL_Signatur_Anf 3;
BA_ "GenSigSendType" SG_ 2527679657 SM_LAPP_Demo_SpuLi_Anf 3;
BA_ "GenSigSendType" SG_ 2527679657 SM_LAPP_Demo_Stufe 3;
BA_ "GenSigSendType" SG_ 2527679657 SM_LAPP_Demo_TraLi_Anf 3;
BA_ "GenSigSendType" SG_ 2527679657 SM_LAPP_Demo_Variante 3;
BA_ "GenSigSendType" SG_ 201 SM_AFR_Standfkt_Anf 0;
BA_ "GenSigSwitchedByIgnition" SG_ 201 SM_AFR_Standfkt_Anf 0;
BA_ "GenSigSendType" SG_ 201 SM_AFR_Verbindungsstatus 0;
BA_ "GenSigSwitchedByIgnition" SG_ 201 SM_AFR_Verbindungsstatus 0;
BA_ "GenSigSendType" SG_ 201 SM_Anlernstatus 0;
BA_ "GenSigSwitchedByIgnition" SG_ 201 SM_Anlernstatus 0;
BA_ "GenSigSendType" SG_ 201 SM_App_Sperrzustand 0;
BA_ "GenSigSwitchedByIgnition" SG_ 201 SM_App_Sperrzustand 0;
BA_ "GenSigSendType" SG_ 201 SM_ARA_Gangwahl 0;
BA_ "GenSigSwitchedByIgnition" SG_ 201 SM_ARA_Gangwahl 0;
BA_ "GenSigSendType" SG_ 201 SM_ARA_Gaspedal 0;
BA_ "GenSigSwitchedByIgnition" SG_ 201 SM_ARA_Gaspedal 0;
BA_ "GenSigSendType" SG_ 201 SM_ARA_Knickwinkel_Soll 0;
BA_ "GenSigStartValue" SG_ 201 SM_ARA_Knickwinkel_Soll 254;
BA_ "GenSigSwitchedByIgnition" SG_ 201 SM_ARA_Knickwinkel_Soll 0;
BA_ "Fehlerwert" SG_ 201 SM_ARA_Knickwinkel_Soll 255;
BA_ "GenSigSendType" SG_ 201 SM_ARA_Nothalt 0;
BA_ "GenSigSwitchedByIgnition" SG_ 201 SM_ARA_Nothalt 0;
BA_ "GenSigSendType" SG_ 201 SM_ARA_Start 0;
BA_ "GenSigSwitchedByIgnition" SG_ 201 SM_ARA_Start 0;
BA_ "GenSigSendType" SG_ 201 SM_ARA_Status_Steuersignal 0;
BA_ "GenSigSwitchedByIgnition" SG_ 201 SM_ARA_Status_Steuersignal 0;
BA_ "GenSigSendType" SG_ 201 SM_ARA_Trajektorienmodus 0;
BA_ "GenSigSwitchedByIgnition" SG_ 201 SM_ARA_Trajektorienmodus 0;
BA_ "GenSigSendType" SG_ 201 SM_Fehlerstatus 0;
BA_ "GenSigSwitchedByIgnition" SG_ 201 SM_Fehlerstatus 0;
BA_ "GenSigSendType" SG_ 201 SM_Parken_Alive 0;
BA_ "GenSigSwitchedByIgnition" SG_ 201 SM_Parken_Alive 0;
BA_ "GenSigSendType" SG_ 201 SM_Parken_Kommando 0;
BA_ "GenSigSwitchedByIgnition" SG_ 201 SM_Parken_Kommando 0;
BA_ "GenSigSendType" SG_ 201 SM_Parken_Kommando_invers 0;
BA_ "GenSigStartValue" SG_ 201 SM_Parken_Kommando_invers 3;
BA_ "GenSigSwitchedByIgnition" SG_ 201 SM_Parken_Kommando_invers 0;
BA_ "GenSigSendType" SG_ 201 SM_Parken_Manoever 0;
BA_ "GenSigSwitchedByIgnition" SG_ 201 SM_Parken_Manoever 0;
BA_ "GenSigSendType" SG_ 201 SM_Parken_Motorstart_Anf 0;
BA_ "GenSigSwitchedByIgnition" SG_ 201 SM_Parken_Motorstart_Anf 0;
BA_ "GenSigSendType" SG_ 201 SM_Parken_Richtung 0;
BA_ "GenSigSwitchedByIgnition" SG_ 201 SM_Parken_Richtung 0;
BA_ "GenSigSendType" SG_ 201 SM_Parken_Seite 0;
BA_ "GenSigSwitchedByIgnition" SG_ 201 SM_Parken_Seite 0;
BA_ "GenSigSendType" SG_ 201 SM_Parken_Szenario 0;
BA_ "GenSigSwitchedByIgnition" SG_ 201 SM_Parken_Szenario 0;
BA_ "GenSigSendType" SG_ 201 SM_Parken_Touch_PosX 0;
BA_ "GenSigSwitchedByIgnition" SG_ 201 SM_Parken_Touch_PosX 0;
BA_ "GenSigSendType" SG_ 201 SM_Parken_Touch_PosY 0;
BA_ "GenSigStartValue" SG_ 201 SM_Parken_Touch_PosY 31;
BA_ "GenSigSwitchedByIgnition" SG_ 201 SM_Parken_Touch_PosY 0;
BA_ "GenSigSendType" SG_ 201 SM_Parken_Verbindungsstatus 0;
BA_ "GenSigSwitchedByIgnition" SG_ 201 SM_Parken_Verbindungsstatus 0;
BA_ "GenSigSendType" SG_ 2527679651 SM_Parken_blinken 0;
BA_ "GenSigSwitchedByIgnition" SG_ 2527679651 SM_Parken_blinken 0;
BA_ "GenSigSendType" SG_ 2527679651 SM_Parken_Hupe_Anf 0;
BA_ "GenSigSwitchedByIgnition" SG_ 2527679651 SM_Parken_Hupe_Anf 0;
BA_ "GenSigSendType" SG_ 2527679651 SM_Parken_Komfortschliessen_Anf 0;
BA_ "GenSigSwitchedByIgnition" SG_ 2527679651 SM_Parken_Komfortschliessen_Anf 0;
BA_ "GenSigSendType" SG_ 2527679651 SM_Parken_UGDO_Aktion 0;
BA_ "GenSigSwitchedByIgnition" SG_ 2527679651 SM_Parken_UGDO_Aktion 0;
BA_ "GenSigSendType" SG_ 2527679651 SM_Parken_UGDO_Anf 0;
BA_ "GenSigSwitchedByIgnition" SG_ 2527679651 SM_Parken_UGDO_Anf 0;
BA_ "GenSigSendType" SG_ 980 BH_Blinker_Fehler 3;
BA_ "GenSigSwitchedByIgnition" SG_ 980 BH_Blinker_Fehler 0;
BA_ "Fehlerwert" SG_ 980 BH_Blinker_Fehler 1;
BA_ "GenSigActiveRepetitions" SG_ 980 BH_Blinker_li 5;
BA_ "GenSigSendType" SG_ 980 BH_Blinker_li 4;
BA_ "GenSigSwitchedByIgnition" SG_ 980 BH_Blinker_li 0;
BA_ "GenSigActiveRepetitions" SG_ 980 BH_Blinker_re 5;
BA_ "GenSigSendType" SG_ 980 BH_Blinker_re 4;
BA_ "GenSigSwitchedByIgnition" SG_ 980 BH_Blinker_re 0;
BA_ "GenSigSendType" SG_ 980 BH_Fernlicht 3;
BA_ "GenSigSwitchedByIgnition" SG_ 980 BH_Fernlicht 0;
BA_ "GenSigActiveRepetitions" SG_ 980 BH_Lichthupe 5;
BA_ "GenSigSendType" SG_ 980 BH_Lichthupe 4;
BA_ "GenSigSwitchedByIgnition" SG_ 980 BH_Lichthupe 0;
BA_ "GenSigSendType" SG_ 980 FAS_Taster 3;
BA_ "GenSigSwitchedByIgnition" SG_ 980 FAS_Taster 0;
BA_ "GenSigSendType" SG_ 980 FAS_Taster_Fehler 3;
BA_ "GenSigSwitchedByIgnition" SG_ 980 FAS_Taster_Fehler 0;
BA_ "Fehlerwert" SG_ 980 FAS_Taster_Fehler 1;
BA_ "GenSigSendType" SG_ 980 LRH_aktiv 3;
BA_ "GenSigSwitchedByIgnition" SG_ 980 LRH_aktiv 0;
BA_ "GenSigSendType" SG_ 980 LRH_On_Off 3;
BA_ "GenSigSwitchedByIgnition" SG_ 980 LRH_On_Off 0;
BA_ "Fehlerwert" SG_ 980 LRH_On_Off 3;
BA_ "GenSigSendType" SG_ 980 SMLS_01_BZ 0;
BA_ "GenSigFuncType" SG_ 980 SMLS_01_BZ 1;
BA_ "GenSigSwitchedByIgnition" SG_ 980 SMLS_01_BZ 0;
BA_ "GenSigSendType" SG_ 980 SMLS_01_CRC 0;
BA_ "GenSigFuncType" SG_ 980 SMLS_01_CRC 2;
BA_ "GenSigSwitchedByIgnition" SG_ 980 SMLS_01_CRC 0;
BA_ "GenSigActiveRepetitions" SG_ 980 SMLS_Hupe 5;
BA_ "GenSigSendType" SG_ 980 SMLS_Hupe 4;
BA_ "GenSigSwitchedByIgnition" SG_ 980 SMLS_Hupe 0;
BA_ "GenSigSendType" SG_ 980 SMLS_P_verriegelt_plausibel 3;
BA_ "GenSigSwitchedByIgnition" SG_ 980 SMLS_P_verriegelt_plausibel 0;
BA_ "GenSigActiveRepetitions" SG_ 980 SMLS_PTT 5;
BA_ "GenSigSendType" SG_ 980 SMLS_PTT 4;
BA_ "GenSigSendType" SG_ 980 WH_Frontwaschen 3;
BA_ "GenSigSwitchedByIgnition" SG_ 980 WH_Frontwaschen 0;
BA_ "GenSigSendType" SG_ 980 WH_Heckintervall 3;
BA_ "GenSigSwitchedByIgnition" SG_ 980 WH_Heckintervall 0;
BA_ "GenSigSendType" SG_ 980 WH_Heckwaschen 3;
BA_ "GenSigSwitchedByIgnition" SG_ 980 WH_Heckwaschen 0;
BA_ "GenSigSendType" SG_ 980 WH_Intervall 3;
BA_ "GenSigSwitchedByIgnition" SG_ 980 WH_Intervall 0;
BA_ "GenSigSendType" SG_ 980 WH_Intervallstufen 3;
BA_ "GenSigSwitchedByIgnition" SG_ 980 WH_Intervallstufen 0;
BA_ "Fehlerwert" SG_ 980 WH_Intervallstufen 15;
BA_ "GenSigMissingSourceValue" SG_ 980 WH_Intervallstufen 15;
BA_ "GenSigActiveRepetitions" SG_ 980 WH_SRA 5;
BA_ "GenSigSendType" SG_ 980 WH_SRA 4;
BA_ "GenSigSwitchedByIgnition" SG_ 980 WH_SRA 0;
BA_ "GenSigActiveRepetitions" SG_ 980 WH_Tipwischen 5;
BA_ "GenSigSendType" SG_ 980 WH_Tipwischen 4;
BA_ "GenSigSwitchedByIgnition" SG_ 980 WH_Tipwischen 0;
BA_ "GenSigActiveRepetitions" SG_ 980 WH_Tipwischen_lang 5;
BA_ "GenSigSendType" SG_ 980 WH_Tipwischen_lang 4;
BA_ "GenSigSwitchedByIgnition" SG_ 980 WH_Tipwischen_lang 0;
BA_ "GenSigSendType" SG_ 980 WH_Wischer_Fehler 3;
BA_ "GenSigSwitchedByIgnition" SG_ 980 WH_Wischer_Fehler 0;
BA_ "Fehlerwert" SG_ 980 WH_Wischer_Fehler 1;
BA_ "GenSigSendType" SG_ 980 WH_WischerStufe1 3;
BA_ "GenSigSwitchedByIgnition" SG_ 980 WH_WischerStufe1 0;
BA_ "GenSigSendType" SG_ 980 WH_WischerStufe2 3;
BA_ "GenSigSwitchedByIgnition" SG_ 980 WH_WischerStufe2 0;
BA_ "GenSigSendType" SG_ 1467 SoSe_SunInt_2D_Li 0;
BA_ "GenSigStartValue" SG_ 1467 SoSe_SunInt_2D_Li 254;
BA_ "GenSigSwitchedByIgnition" SG_ 1467 SoSe_SunInt_2D_Li 0;
BA_ "Fehlerwert" SG_ 1467 SoSe_SunInt_2D_Li 255;
BA_ "GenSigSendType" SG_ 1467 SoSe_SunInt_2D_Re 0;
BA_ "GenSigStartValue" SG_ 1467 SoSe_SunInt_2D_Re 254;
BA_ "GenSigSwitchedByIgnition" SG_ 1467 SoSe_SunInt_2D_Re 0;
BA_ "Fehlerwert" SG_ 1467 SoSe_SunInt_2D_Re 255;
BA_ "GenSigActiveRepetitions" SG_ 1710 SP_abklappen 5;
BA_ "GenSigSendType" SG_ 1710 SP_abklappen 4;
BA_ "GenSigSwitchedByIgnition" SG_ 1710 SP_abklappen 0;
BA_ "GenSigActiveRepetitions" SG_ 1710 SP_anklappen 5;
BA_ "GenSigSendType" SG_ 1710 SP_anklappen 4;
BA_ "GenSigSwitchedByIgnition" SG_ 1710 SP_anklappen 0;
BA_ "GenSigSendType" SG_ 1710 SP_ARA_Status 0;
BA_ "GenSigActiveRepetitions" SG_ 1710 SP_Auswahl_li 5;
BA_ "GenSigSendType" SG_ 1710 SP_Auswahl_li 4;
BA_ "GenSigSwitchedByIgnition" SG_ 1710 SP_Auswahl_li 0;
BA_ "GenSigActiveRepetitions" SG_ 1710 SP_Auswahl_re 5;
BA_ "GenSigSendType" SG_ 1710 SP_Auswahl_re 4;
BA_ "GenSigSwitchedByIgnition" SG_ 1710 SP_Auswahl_re 0;
BA_ "GenSigActiveRepetitions" SG_ 1710 SP_BT_links 5;
BA_ "GenSigSendType" SG_ 1710 SP_BT_links 4;
BA_ "GenSigSwitchedByIgnition" SG_ 1710 SP_BT_links 0;
BA_ "GenSigActiveRepetitions" SG_ 1710 SP_BT_oben 5;
BA_ "GenSigSendType" SG_ 1710 SP_BT_oben 4;
BA_ "GenSigSwitchedByIgnition" SG_ 1710 SP_BT_oben 0;
BA_ "GenSigActiveRepetitions" SG_ 1710 SP_BT_rechts 5;
BA_ "GenSigSendType" SG_ 1710 SP_BT_rechts 4;
BA_ "GenSigSwitchedByIgnition" SG_ 1710 SP_BT_rechts 0;
BA_ "GenSigActiveRepetitions" SG_ 1710 SP_BT_unten 5;
BA_ "GenSigSendType" SG_ 1710 SP_BT_unten 4;
BA_ "GenSigSwitchedByIgnition" SG_ 1710 SP_BT_unten 0;
BA_ "GenSigActiveRepetitions" SG_ 1710 SP_FT_links 5;
BA_ "GenSigSendType" SG_ 1710 SP_FT_links 4;
BA_ "GenSigSwitchedByIgnition" SG_ 1710 SP_FT_links 0;
BA_ "GenSigActiveRepetitions" SG_ 1710 SP_FT_oben 5;
BA_ "GenSigSendType" SG_ 1710 SP_FT_oben 4;
BA_ "GenSigSwitchedByIgnition" SG_ 1710 SP_FT_oben 0;
BA_ "GenSigActiveRepetitions" SG_ 1710 SP_FT_rechts 5;
BA_ "GenSigSendType" SG_ 1710 SP_FT_rechts 4;
BA_ "GenSigSwitchedByIgnition" SG_ 1710 SP_FT_rechts 0;
BA_ "GenSigActiveRepetitions" SG_ 1710 SP_FT_unten 5;
BA_ "GenSigSendType" SG_ 1710 SP_FT_unten 4;
BA_ "GenSigSwitchedByIgnition" SG_ 1710 SP_FT_unten 0;
BA_ "GenSigSendType" SG_ 1710 SP_Hzg_Taster 3;
BA_ "GenSigSwitchedByIgnition" SG_ 1710 SP_Hzg_Taster 0;
BA_ "GenSigActiveRepetitions" SG_ 1710 SP_normieren 5;
BA_ "GenSigSendType" SG_ 1710 SP_normieren 4;
BA_ "GenSigSwitchedByIgnition" SG_ 1710 SP_normieren 0;
BA_ "GenSigActiveRepetitions" SG_ 1710 SP_S_Klappen 5;
BA_ "GenSigSendType" SG_ 1710 SP_S_Klappen 4;
BA_ "GenSigSwitchedByIgnition" SG_ 1710 SP_S_Klappen 0;
BA_ "GenSigActiveRepetitions" SG_ 1710 SP_S_links 5;
BA_ "GenSigSendType" SG_ 1710 SP_S_links 4;
BA_ "GenSigSwitchedByIgnition" SG_ 1710 SP_S_links 0;
BA_ "GenSigActiveRepetitions" SG_ 1710 SP_S_oben 5;
BA_ "GenSigSendType" SG_ 1710 SP_S_oben 4;
BA_ "GenSigSwitchedByIgnition" SG_ 1710 SP_S_oben 0;
BA_ "GenSigActiveRepetitions" SG_ 1710 SP_S_rechts 5;
BA_ "GenSigSendType" SG_ 1710 SP_S_rechts 4;
BA_ "GenSigSwitchedByIgnition" SG_ 1710 SP_S_rechts 0;
BA_ "GenSigActiveRepetitions" SG_ 1710 SP_S_unten 5;
BA_ "GenSigSendType" SG_ 1710 SP_S_unten 4;
BA_ "GenSigSwitchedByIgnition" SG_ 1710 SP_S_unten 0;
BA_ "GenSigSendType" SG_ 1710 SP_Verstellschalter_Fehler 0;
BA_ "Fehlerwert" SG_ 1710 SP_Verstellschalter_Fehler 1;
BA_REL_ "GenSigTimeoutTime" BU_SG_REL_ BedienSG_hi SG_ 1504 MD1_Position 5000;
BA_REL_ "GenSigTimeoutTime" BU_SG_REL_ BedienSG_hi SG_ 1504 MD1_Lage 5000;
BA_REL_ "GenSigTimeoutTime" BU_SG_REL_ BedienSG_hi SG_ 1504 MD3_Position 5000;
BA_REL_ "GenSigTimeoutTime" BU_SG_REL_ BedienSG_hi SG_ 1504 MD3_Lage 5000;
BA_REL_ "GenSigTimeoutTime" BU_SG_REL_ BedienSG_hi SG_ 1504 MRollo_Position 5000;
BA_REL_ "GenSigTimeoutTime" BU_SG_REL_ BedienSG_hi SG_ 1504 MRollo_Lage 5000;
BA_REL_ "GenSigTimeoutTime" BU_SG_REL_ BedienSG_hi SG_ 1504 SAD_normiert 5000;
BA_REL_ "GenSigTimeoutTime" BU_SG_REL_ BedienSG_hi SG_ 1504 SAD_Thermoschutz 5000;
BA_REL_ "GenSigTimeoutTime" BU_SG_REL_ BedienSG_hi SG_ 1504 SAD_UEKB_aktiv 5000;
BA_REL_ "GenSigTimeoutTime" BU_SG_REL_ BedienSG_hi SG_ 1504 Rollo_normiert 5000;
BA_REL_ "GenSigTimeoutTime" BU_SG_REL_ BedienSG_hi SG_ 1504 Rollo_Thermoschutz 5000;
BA_REL_ "GenSigTimeoutTime" BU_SG_REL_ BedienSG_hi SG_ 1504 Rollo_UEKB_aktiv 5000;
BA_REL_ "GenSigTimeoutTime" BU_SG_REL_ DDA SG_ 1517 SAD2_Deckel_Lage 5000;
BA_REL_ "GenSigTimeoutTime" BU_SG_REL_ DDA SG_ 1517 SAD2_Deckel_Position 5000;
BA_REL_ "GenSigTimeoutTime" BU_SG_REL_ DDA SG_ 1504 MD1_Position 5000;
BA_REL_ "GenSigTimeoutTime" BU_SG_REL_ DDA SG_ 1504 MD1_Lage 5000;
BA_REL_ "GenSigTimeoutTime" BU_SG_REL_ Gateway SG_ 1123 PSD_Pos_Segment_ID 1500;
BA_REL_ "GenSigTimeoutTime" BU_SG_REL_ Gateway SG_ 1123 PSD_Pos_Segmentlaenge 1500;
BA_REL_ "GenSigTimeoutTime" BU_SG_REL_ Gateway SG_ 1123 PSD_Pos_Inhibitzeit 1500;
BA_REL_ "GenSigTimeoutTime" BU_SG_REL_ Gateway SG_ 1123 PSD_Pos_Standort_Eindeutig 1500;
BA_REL_ "GenSigTimeoutTime" BU_SG_REL_ Gateway SG_ 1123 PSD_Pos_Fehler_Laengsrichtung 1500;
BA_REL_ "GenSigTimeoutTime" BU_SG_REL_ Gateway SG_ 1123 PSD_Pos_Fahrspur 1500;
BA_REL_ "GenSigTimeoutTime" BU_SG_REL_ Gateway SG_ 1123 PSD_Attribut_Segment_ID_05 1500;
BA_REL_ "GenSigTimeoutTime" BU_SG_REL_ Gateway SG_ 1123 PSD_Attribut_1_ID 1500;
BA_REL_ "GenSigTimeoutTime" BU_SG_REL_ Gateway SG_ 1123 PSD_Attribut_1_Wert 1500;
BA_REL_ "GenSigTimeoutTime" BU_SG_REL_ Gateway SG_ 1123 PSD_Attribut_1_Offset 1500;
BA_REL_ "GenSigTimeoutTime" BU_SG_REL_ Gateway SG_ 1123 PSD_Attribut_2_ID 1500;
BA_REL_ "GenSigTimeoutTime" BU_SG_REL_ Gateway SG_ 1123 PSD_Attribut_2_Wert 1500;
BA_REL_ "GenSigTimeoutTime" BU_SG_REL_ Gateway SG_ 1123 PSD_Attribut_2_Offset 1500;
BA_REL_ "GenSigTimeoutTime" BU_SG_REL_ Gateway SG_ 1123 PSD_Attribute_Komplett_05 1500;
BA_REL_ "GenSigTimeoutTime" BU_SG_REL_ Gateway SG_ 1124 PSD_06_Mux 1500;
BA_REL_ "GenSigTimeoutTime" BU_SG_REL_ Gateway SG_ 1124 PSD_Sys_Segment_ID 1500;
BA_REL_ "GenSigTimeoutTime" BU_SG_REL_ Gateway SG_ 1124 PSD_Attribut_Segment_ID 1500;
BA_REL_ "GenSigTimeoutTime" BU_SG_REL_ Gateway SG_ 1124 PSD_Ges_Segment_ID 1500;
BA_REL_ "GenSigTimeoutTime" BU_SG_REL_ Gateway SG_ 1124 PSD_Baum_Laenge_VZ 1500;
BA_REL_ "GenSigTimeoutTime" BU_SG_REL_ Gateway SG_ 1124 PSD_Steigung_1_Segment_ID 1500;
BA_REL_ "GenSigTimeoutTime" BU_SG_REL_ Gateway SG_ 1124 PSD_Baum_Laenge 1500;
BA_REL_ "GenSigTimeoutTime" BU_SG_REL_ Gateway SG_ 1124 PSD_Sys_Laendercode 1500;
BA_REL_ "GenSigTimeoutTime" BU_SG_REL_ Gateway SG_ 1124 PSD_Attribut_3_ID 1500;
BA_REL_ "GenSigTimeoutTime" BU_SG_REL_ Gateway SG_ 1124 PSD_Ges_Offset 1500;
BA_REL_ "GenSigTimeoutTime" BU_SG_REL_ Gateway SG_ 1124 PSD_Steigung_1_A_Steigung 1500;
BA_REL_ "GenSigTimeoutTime" BU_SG_REL_ Gateway SG_ 1124 PSD_Attribut_3_Offset 1500;
BA_REL_ "GenSigTimeoutTime" BU_SG_REL_ Gateway SG_ 1124 PSD_Ges_Geschwindigkeit 1500;
BA_REL_ "GenSigTimeoutTime" BU_SG_REL_ Gateway SG_ 1124 PSD_Steigung_1_A_Vorz 1500;
BA_REL_ "GenSigTimeoutTime" BU_SG_REL_ Gateway SG_ 1124 PSD_Sys_Geschwindigkeit_Einheit 1500;
BA_REL_ "GenSigTimeoutTime" BU_SG_REL_ Gateway SG_ 1124 PSD_Steigung_1_A_Offset 1500;
BA_REL_ "GenSigTimeoutTime" BU_SG_REL_ Gateway SG_ 1124 PSD_Sys_Verkehrsrichtung 1500;
BA_REL_ "GenSigTimeoutTime" BU_SG_REL_ Gateway SG_ 1124 PSD_Sys_Geometrieguete 1500;
BA_REL_ "GenSigTimeoutTime" BU_SG_REL_ Gateway SG_ 1124 PSD_Sys_Mapmatchingguete 1500;
BA_REL_ "GenSigTimeoutTime" BU_SG_REL_ Gateway SG_ 1124 PSD_Attribut_3_Wert 1500;
BA_REL_ "GenSigTimeoutTime" BU_SG_REL_ Gateway SG_ 1124 PSD_Ges_Typ 1500;
BA_REL_ "GenSigTimeoutTime" BU_SG_REL_ Gateway SG_ 1124 PSD_Sys_Alter_Karte 1500;
BA_REL_ "GenSigTimeoutTime" BU_SG_REL_ Gateway SG_ 1124 PSD_Ges_Spur_Geschw_Begrenzung 1500;
BA_REL_ "GenSigTimeoutTime" BU_SG_REL_ Gateway SG_ 1124 PSD_Steigung_1_B_Steigung 1500;
BA_REL_ "GenSigTimeoutTime" BU_SG_REL_ Gateway SG_ 1124 PSD_Attribut_4_ID 1500;
BA_REL_ "GenSigTimeoutTime" BU_SG_REL_ Gateway SG_ 1124 PSD_Sys_Zielfuehrung 1500;
BA_REL_ "GenSigTimeoutTime" BU_SG_REL_ Gateway SG_ 1124 PSD_Sys_US_State 1500;
BA_REL_ "GenSigTimeoutTime" BU_SG_REL_ Gateway SG_ 1124 PSD_Ges_Geschwindigkeit_Gespann 1500;
BA_REL_ "GenSigTimeoutTime" BU_SG_REL_ Gateway SG_ 1124 PSD_Baum_Breite_VZ 1500;
BA_REL_ "GenSigTimeoutTime" BU_SG_REL_ Gateway SG_ 1124 PSD_Attribut_4_Wert 1500;
BA_REL_ "GenSigTimeoutTime" BU_SG_REL_ Gateway SG_ 1124 PSD_Baum_Breite 1500;
BA_REL_ "GenSigTimeoutTime" BU_SG_REL_ Gateway SG_ 1124 PSD_Ges_Geschwindigkeit_Witter 1500;
BA_REL_ "GenSigTimeoutTime" BU_SG_REL_ Gateway SG_ 1124 PSD_Steigung_1_B_Vorz 1500;
BA_REL_ "GenSigTimeoutTime" BU_SG_REL_ Gateway SG_ 1124 PSD_Steigung_1_B_Offset 1500;
BA_REL_ "GenSigTimeoutTime" BU_SG_REL_ Gateway SG_ 1124 PSD_Ges_Geschwindigkeit_Tag_Anf 1500;
BA_REL_ "GenSigTimeoutTime" BU_SG_REL_ Gateway SG_ 1124 PSD_Attribut_4_Offset 1500;
BA_REL_ "GenSigTimeoutTime" BU_SG_REL_ Gateway SG_ 1124 PSD_Ges_Geschwindigkeit_Tag_Ende 1500;
BA_REL_ "GenSigTimeoutTime" BU_SG_REL_ Gateway SG_ 1124 PSD_Ges_Geschwindigkeit_Std_Anf 1500;
BA_REL_ "GenSigTimeoutTime" BU_SG_REL_ Gateway SG_ 1124 PSD_Steigung_1_Attribute_kompl 1500;
BA_REL_ "GenSigTimeoutTime" BU_SG_REL_ Gateway SG_ 1124 PSD_Steigung_2_Segment_ID 1500;
BA_REL_ "GenSigTimeoutTime" BU_SG_REL_ Gateway SG_ 1124 PSD_Attribut_5_ID 1500;
BA_REL_ "GenSigTimeoutTime" BU_SG_REL_ Gateway SG_ 1124 PSD_Ges_Geschwindigkeit_Std_Ende 1500;
BA_REL_ "GenSigTimeoutTime" BU_SG_REL_ Gateway SG_ 1124 PSD_Attribut_5_Offset 1500;
BA_REL_ "GenSigTimeoutTime" BU_SG_REL_ Gateway SG_ 1124 PSD_Steigung_2_Steigung 1500;
BA_REL_ "GenSigTimeoutTime" BU_SG_REL_ Gateway SG_ 1124 PSD_Ges_Ueberholverbot 1500;
BA_REL_ "GenSigTimeoutTime" BU_SG_REL_ Gateway SG_ 1124 PSD_Ges_Wechselverkehrszeichen 1500;
BA_REL_ "GenSigTimeoutTime" BU_SG_REL_ Gateway SG_ 1124 PSD_Attribut_5_Wert 1500;
BA_REL_ "GenSigTimeoutTime" BU_SG_REL_ Gateway SG_ 1124 PSD_Steigung_2_Vorz 1500;
BA_REL_ "GenSigTimeoutTime" BU_SG_REL_ Gateway SG_ 1124 PSD_Wechselverkehrszeichen_Typ 1500;
BA_REL_ "GenSigTimeoutTime" BU_SG_REL_ Gateway SG_ 1124 PSD_Baum_Ausrichtung 1500;
BA_REL_ "GenSigTimeoutTime" BU_SG_REL_ Gateway SG_ 1124 PSD_Steigung_2_Offset 1500;
BA_REL_ "GenSigTimeoutTime" BU_SG_REL_ Gateway SG_ 1124 PSD_Ges_Gesetzlich_Kategorie 1500;
BA_REL_ "GenSigTimeoutTime" BU_SG_REL_ Gateway SG_ 1124 PSD_Attribute_Komplett_06 1500;
BA_REL_ "GenSigTimeoutTime" BU_SG_REL_ Gateway SG_ 1124 PSD_Ges_Gesetzlich_Zusatz 1500;
BA_REL_ "GenSigTimeoutTime" BU_SG_REL_ Gateway SG_ 1124 PSD_Ges_Verkehrszeichen_Quelle 1500;
BA_REL_ "GenSigTimeoutTime" BU_SG_REL_ Gateway SG_ 1124 PSD_Steigung_2_Attribute_kompl 1500;
BA_REL_ "GenSigTimeoutTime" BU_SG_REL_ Gateway SG_ 1124 PSD_Ges_Attribute_Komplett 1500;
BA_REL_ "GenSigTimeoutTime" BU_SG_REL_ Gateway SG_ 1616 RA_Radio_on 5000;
BA_REL_ "GenSigTimeoutTime" BU_SG_REL_ Gateway_PAG SG_ 1123 PSD_Pos_Segment_ID 1500;
BA_REL_ "GenSigTimeoutTime" BU_SG_REL_ Gateway_PAG SG_ 1123 PSD_Pos_Segmentlaenge 1500;
BA_REL_ "GenSigTimeoutTime" BU_SG_REL_ Gateway_PAG SG_ 1123 PSD_Pos_Inhibitzeit 1500;
BA_REL_ "GenSigTimeoutTime" BU_SG_REL_ Gateway_PAG SG_ 1123 PSD_Pos_Standort_Eindeutig 1500;
BA_REL_ "GenSigTimeoutTime" BU_SG_REL_ Gateway_PAG SG_ 1123 PSD_Pos_Fehler_Laengsrichtung 1500;
BA_REL_ "GenSigTimeoutTime" BU_SG_REL_ Gateway_PAG SG_ 1123 PSD_Pos_Fahrspur 1500;
BA_REL_ "GenSigTimeoutTime" BU_SG_REL_ Gateway_PAG SG_ 1123 PSD_Attribut_Segment_ID_05 1500;
BA_REL_ "GenSigTimeoutTime" BU_SG_REL_ Gateway_PAG SG_ 1123 PSD_Attribut_1_ID 1500;
BA_REL_ "GenSigTimeoutTime" BU_SG_REL_ Gateway_PAG SG_ 1123 PSD_Attribut_1_Wert 1500;
BA_REL_ "GenSigTimeoutTime" BU_SG_REL_ Gateway_PAG SG_ 1123 PSD_Attribut_1_Offset 1500;
BA_REL_ "GenSigTimeoutTime" BU_SG_REL_ Gateway_PAG SG_ 1123 PSD_Attribut_2_ID 1500;
BA_REL_ "GenSigTimeoutTime" BU_SG_REL_ Gateway_PAG SG_ 1123 PSD_Attribut_2_Wert 1500;
BA_REL_ "GenSigTimeoutTime" BU_SG_REL_ Gateway_PAG SG_ 1123 PSD_Attribut_2_Offset 1500;
BA_REL_ "GenSigTimeoutTime" BU_SG_REL_ Gateway_PAG SG_ 1123 PSD_Attribute_Komplett_05 1500;
BA_REL_ "GenSigTimeoutTime" BU_SG_REL_ Gateway_PAG SG_ 1124 PSD_06_Mux 1500;
BA_REL_ "GenSigTimeoutTime" BU_SG_REL_ Gateway_PAG SG_ 1124 PSD_Sys_Segment_ID 1500;
BA_REL_ "GenSigTimeoutTime" BU_SG_REL_ Gateway_PAG SG_ 1124 PSD_Attribut_Segment_ID 1500;
BA_REL_ "GenSigTimeoutTime" BU_SG_REL_ Gateway_PAG SG_ 1124 PSD_Ges_Segment_ID 1500;
BA_REL_ "GenSigTimeoutTime" BU_SG_REL_ Gateway_PAG SG_ 1124 PSD_Baum_Laenge_VZ 1500;
BA_REL_ "GenSigTimeoutTime" BU_SG_REL_ Gateway_PAG SG_ 1124 PSD_Steigung_1_Segment_ID 1500;
BA_REL_ "GenSigTimeoutTime" BU_SG_REL_ Gateway_PAG SG_ 1124 PSD_Baum_Laenge 1500;
BA_REL_ "GenSigTimeoutTime" BU_SG_REL_ Gateway_PAG SG_ 1124 PSD_Sys_Laendercode 1500;
BA_REL_ "GenSigTimeoutTime" BU_SG_REL_ Gateway_PAG SG_ 1124 PSD_Attribut_3_ID 1500;
BA_REL_ "GenSigTimeoutTime" BU_SG_REL_ Gateway_PAG SG_ 1124 PSD_Ges_Offset 1500;
BA_REL_ "GenSigTimeoutTime" BU_SG_REL_ Gateway_PAG SG_ 1124 PSD_Steigung_1_A_Steigung 1500;
BA_REL_ "GenSigTimeoutTime" BU_SG_REL_ Gateway_PAG SG_ 1124 PSD_Attribut_3_Offset 1500;
BA_REL_ "GenSigTimeoutTime" BU_SG_REL_ Gateway_PAG SG_ 1124 PSD_Ges_Geschwindigkeit 1500;
BA_REL_ "GenSigTimeoutTime" BU_SG_REL_ Gateway_PAG SG_ 1124 PSD_Steigung_1_A_Vorz 1500;
BA_REL_ "GenSigTimeoutTime" BU_SG_REL_ Gateway_PAG SG_ 1124 PSD_Sys_Geschwindigkeit_Einheit 1500;
BA_REL_ "GenSigTimeoutTime" BU_SG_REL_ Gateway_PAG SG_ 1124 PSD_Steigung_1_A_Offset 1500;
BA_REL_ "GenSigTimeoutTime" BU_SG_REL_ Gateway_PAG SG_ 1124 PSD_Sys_Verkehrsrichtung 1500;
BA_REL_ "GenSigTimeoutTime" BU_SG_REL_ Gateway_PAG SG_ 1124 PSD_Sys_Geometrieguete 1500;
BA_REL_ "GenSigTimeoutTime" BU_SG_REL_ Gateway_PAG SG_ 1124 PSD_Sys_Mapmatchingguete 1500;
BA_REL_ "GenSigTimeoutTime" BU_SG_REL_ Gateway_PAG SG_ 1124 PSD_Attribut_3_Wert 1500;
BA_REL_ "GenSigTimeoutTime" BU_SG_REL_ Gateway_PAG SG_ 1124 PSD_Ges_Typ 1500;
BA_REL_ "GenSigTimeoutTime" BU_SG_REL_ Gateway_PAG SG_ 1124 PSD_Sys_Alter_Karte 1500;
BA_REL_ "GenSigTimeoutTime" BU_SG_REL_ Gateway_PAG SG_ 1124 PSD_Ges_Spur_Geschw_Begrenzung 1500;
BA_REL_ "GenSigTimeoutTime" BU_SG_REL_ Gateway_PAG SG_ 1124 PSD_Steigung_1_B_Steigung 1500;
BA_REL_ "GenSigTimeoutTime" BU_SG_REL_ Gateway_PAG SG_ 1124 PSD_Attribut_4_ID 1500;
BA_REL_ "GenSigTimeoutTime" BU_SG_REL_ Gateway_PAG SG_ 1124 PSD_Sys_Zielfuehrung 1500;
BA_REL_ "GenSigTimeoutTime" BU_SG_REL_ Gateway_PAG SG_ 1124 PSD_Sys_US_State 1500;
BA_REL_ "GenSigTimeoutTime" BU_SG_REL_ Gateway_PAG SG_ 1124 PSD_Ges_Geschwindigkeit_Gespann 1500;
BA_REL_ "GenSigTimeoutTime" BU_SG_REL_ Gateway_PAG SG_ 1124 PSD_Baum_Breite_VZ 1500;
BA_REL_ "GenSigTimeoutTime" BU_SG_REL_ Gateway_PAG SG_ 1124 PSD_Attribut_4_Wert 1500;
BA_REL_ "GenSigTimeoutTime" BU_SG_REL_ Gateway_PAG SG_ 1124 PSD_Baum_Breite 1500;
BA_REL_ "GenSigTimeoutTime" BU_SG_REL_ Gateway_PAG SG_ 1124 PSD_Ges_Geschwindigkeit_Witter 1500;
BA_REL_ "GenSigTimeoutTime" BU_SG_REL_ Gateway_PAG SG_ 1124 PSD_Steigung_1_B_Vorz 1500;
BA_REL_ "GenSigTimeoutTime" BU_SG_REL_ Gateway_PAG SG_ 1124 PSD_Steigung_1_B_Offset 1500;
BA_REL_ "GenSigTimeoutTime" BU_SG_REL_ Gateway_PAG SG_ 1124 PSD_Ges_Geschwindigkeit_Tag_Anf 1500;
BA_REL_ "GenSigTimeoutTime" BU_SG_REL_ Gateway_PAG SG_ 1124 PSD_Attribut_4_Offset 1500;
BA_REL_ "GenSigTimeoutTime" BU_SG_REL_ Gateway_PAG SG_ 1124 PSD_Ges_Geschwindigkeit_Tag_Ende 1500;
BA_REL_ "GenSigTimeoutTime" BU_SG_REL_ Gateway_PAG SG_ 1124 PSD_Ges_Geschwindigkeit_Std_Anf 1500;
BA_REL_ "GenSigTimeoutTime" BU_SG_REL_ Gateway_PAG SG_ 1124 PSD_Steigung_1_Attribute_kompl 1500;
BA_REL_ "GenSigTimeoutTime" BU_SG_REL_ Gateway_PAG SG_ 1124 PSD_Steigung_2_Segment_ID 1500;
BA_REL_ "GenSigTimeoutTime" BU_SG_REL_ Gateway_PAG SG_ 1124 PSD_Attribut_5_ID 1500;
BA_REL_ "GenSigTimeoutTime" BU_SG_REL_ Gateway_PAG SG_ 1124 PSD_Ges_Geschwindigkeit_Std_Ende 1500;
BA_REL_ "GenSigTimeoutTime" BU_SG_REL_ Gateway_PAG SG_ 1124 PSD_Attribut_5_Offset 1500;
BA_REL_ "GenSigTimeoutTime" BU_SG_REL_ Gateway_PAG SG_ 1124 PSD_Steigung_2_Steigung 1500;
BA_REL_ "GenSigTimeoutTime" BU_SG_REL_ Gateway_PAG SG_ 1124 PSD_Ges_Ueberholverbot 1500;
BA_REL_ "GenSigTimeoutTime" BU_SG_REL_ Gateway_PAG SG_ 1124 PSD_Ges_Wechselverkehrszeichen 1500;
BA_REL_ "GenSigTimeoutTime" BU_SG_REL_ Gateway_PAG SG_ 1124 PSD_Attribut_5_Wert 1500;
BA_REL_ "GenSigTimeoutTime" BU_SG_REL_ Gateway_PAG SG_ 1124 PSD_Steigung_2_Vorz 1500;
BA_REL_ "GenSigTimeoutTime" BU_SG_REL_ Gateway_PAG SG_ 1124 PSD_Wechselverkehrszeichen_Typ 1500;
BA_REL_ "GenSigTimeoutTime" BU_SG_REL_ Gateway_PAG SG_ 1124 PSD_Baum_Ausrichtung 1500;
BA_REL_ "GenSigTimeoutTime" BU_SG_REL_ Gateway_PAG SG_ 1124 PSD_Steigung_2_Offset 1500;
BA_REL_ "GenSigTimeoutTime" BU_SG_REL_ Gateway_PAG SG_ 1124 PSD_Ges_Gesetzlich_Kategorie 1500;
BA_REL_ "GenSigTimeoutTime" BU_SG_REL_ Gateway_PAG SG_ 1124 PSD_Attribute_Komplett_06 1500;
BA_REL_ "GenSigTimeoutTime" BU_SG_REL_ Gateway_PAG SG_ 1124 PSD_Ges_Gesetzlich_Zusatz 1500;
BA_REL_ "GenSigTimeoutTime" BU_SG_REL_ Gateway_PAG SG_ 1124 PSD_Ges_Verkehrszeichen_Quelle 1500;
BA_REL_ "GenSigTimeoutTime" BU_SG_REL_ Gateway_PAG SG_ 1124 PSD_Steigung_2_Attribute_kompl 1500;
BA_REL_ "GenSigTimeoutTime" BU_SG_REL_ Gateway_PAG SG_ 1124 PSD_Ges_Attribute_Komplett 1500;
BA_REL_ "GenSigTimeoutTime" BU_SG_REL_ Gateway_PAG SG_ 1616 RA_Radio_on 5000;
BA_REL_ "GenSigTimeoutTime" BU_SG_REL_ OTA_FC SG_ 1123 PSD_Pos_Fahrspur 1500;
BA_REL_ "GenSigTimeoutTime" BU_SG_REL_ OTA_FC SG_ 1124 PSD_Ges_Geschwindigkeit 1500;
BA_REL_ "GenSigTimeoutTime" BU_SG_REL_ OTA_FC SG_ 1124 PSD_Sys_Zielfuehrung 1500;
BA_REL_ "GenSigTimeoutTime" BU_SG_REL_ OTA_FC SG_ 1529 RDK_Reifendruck_Lampe 3200;
BA_REL_ "GenSigTimeoutTime" BU_SG_REL_ OTA_FC SG_ 1711 RV_Reinigung_Anf 5000;
BA_REL_ "GenSigTimeoutTime" BU_SG_REL_ OTA_FC SG_ 1440 RS_Regenmenge 2000;
BA_REL_ "GenSigTimeoutTime" BU_SG_REL_ OTA_FC SG_ 1440 RS_Wischergeschwindigkeit 2000;
BA_REL_ "GenSigTimeoutTime" BU_SG_REL_ OTA_FC SG_ 1517 SAD2_Deckel_Position 5000;
BA_REL_ "GenSigTimeoutTime" BU_SG_REL_ OTA_FC SG_ 1504 MD1_Position 5000;
BA_REL_ "GenSigTimeoutTime" BU_SG_REL_ OTA_FC SG_ 1504 MD1_Lage 5000;
BA_REL_ "GenSigTimeoutTime" BU_SG_REL_ OTA_FC SG_ 424 SARA_Accel_X_r 500;
BA_REL_ "GenSigTimeoutTime" BU_SG_REL_ OTA_FC SG_ 424 SARA_Accel_Y_r 500;
BA_REL_ "GenSigTimeoutTime" BU_SG_REL_ OTA_FC SG_ 980 WH_SRA 2000;
BA_REL_ "GenSigTimeoutTime" BU_SG_REL_ OTA_FC SG_ 1710 SP_FT_oben 5000;
BA_REL_ "GenSigTimeoutTime" BU_SG_REL_ OTA_FC SG_ 1710 SP_FT_unten 5000;
BA_REL_ "GenSigTimeoutTime" BU_SG_REL_ OTA_FC SG_ 1710 SP_FT_links 5000;
BA_REL_ "GenSigTimeoutTime" BU_SG_REL_ OTA_FC SG_ 1710 SP_FT_rechts 5000;
BA_REL_ "GenSigTimeoutTime" BU_SG_REL_ OTA_FC SG_ 1710 SP_BT_oben 5000;
BA_REL_ "GenSigTimeoutTime" BU_SG_REL_ OTA_FC SG_ 1710 SP_BT_unten 5000;
BA_REL_ "GenSigTimeoutTime" BU_SG_REL_ OTA_FC SG_ 1710 SP_BT_links 5000;
BA_REL_ "GenSigTimeoutTime" BU_SG_REL_ OTA_FC SG_ 1710 SP_BT_rechts 5000;
BA_REL_ "GenSigTimeoutTime" BU_SG_REL_ OTA_FC SG_ 1710 SP_abklappen 5000;
BA_REL_ "GenSigTimeoutTime" BU_SG_REL_ OTA_FC SG_ 1710 SP_anklappen 5000;
BA_REL_ "GenSigTimeoutTime" BU_SG_REL_ OTA_FC SG_ 1710 SP_normieren 5000;
BA_REL_ "GenSigTimeoutTime" BU_SG_REL_ OTA_FC SG_ 1710 SP_Hzg_Taster 5000;
BA_REL_ "GenSigTimeoutTime" BU_SG_REL_ ZR_High SG_ 906 QSP_Warnlampe 1000;
BA_REL_ "GenSigTimeoutTime" BU_SG_REL_ ZR_High SG_ 906 QSP_Thermische_Belastung 1000;
BA_REL_ "GenSigTimeoutTime" BU_SG_REL_ ZR_High SG_ 906 QSP_Temperatur_Oel 1000;
BA_REL_ "GenSigTimeoutTime" BU_SG_REL_ ZR_High SG_ 1529 RDK_FMVSS138_Lampe 3200;
BA_REL_ "GenSigTimeoutTime" BU_SG_REL_ ZR_High SG_ 1529 RDK_FMVSS138_MIL 3200;
BA_REL_ "GenSigTimeoutTime" BU_SG_REL_ ZR_High SG_ 1529 RDK_Reifendruck_Lampe 3200;
BA_REL_ "GenSigTimeoutTime" BU_SG_REL_ ZR_High SG_ 1529 RDK_Warnungen_02 3200;
BA_REL_ "GenSigTimeoutTime" BU_SG_REL_ ZR_High SG_ 1529 RDK_Reifentemperatur_Lampe 3200;
BA_REL_ "GenSigTimeoutTime" BU_SG_REL_ ZR_High SG_ 1529 RDK_W_1_Reifen_HL 3200;
BA_REL_ "GenSigTimeoutTime" BU_SG_REL_ ZR_High SG_ 1529 RDK_W_1_Reifen_HR 3200;
BA_REL_ "GenSigTimeoutTime" BU_SG_REL_ ZR_High SG_ 1529 RDK_W_1_Reifen_VL 3200;
BA_REL_ "GenSigTimeoutTime" BU_SG_REL_ ZR_High SG_ 1529 RDK_W_1_Reifen_VR 3200;
BA_REL_ "GenSigTimeoutTime" BU_SG_REL_ ZR_High SG_ 1529 RDK_W_2_Reifen_HL 3200;
BA_REL_ "GenSigTimeoutTime" BU_SG_REL_ ZR_High SG_ 1529 RDK_W_2_Reifen_HR 3200;
BA_REL_ "GenSigTimeoutTime" BU_SG_REL_ ZR_High SG_ 1529 RDK_W_2_Reifen_VL 3200;
BA_REL_ "GenSigTimeoutTime" BU_SG_REL_ ZR_High SG_ 1529 RDK_W_2_Reifen_VR 3200;
BA_REL_ "GenSigTimeoutTime" BU_SG_REL_ ZR_High SG_ 1711 RV_Video_on 5000;
BA_REL_ "GenSigTimeoutTime" BU_SG_REL_ ZR_High SG_ 1711 RV_Dark_Screen 5000;
BA_REL_ "GenSigTimeoutTime" BU_SG_REL_ ZR_High SG_ 1711 RV_HMI_Mode 5000;
BA_REL_ "GenSigTimeoutTime" BU_SG_REL_ ZR_High SG_ 1711 RV_GL_side 5000;
BA_REL_ "GenSigTimeoutTime" BU_SG_REL_ ZR_High SG_ 1711 RV_System_aktiv 5000;
BA_REL_ "GenSigTimeoutTime" BU_SG_REL_ ZR_High SG_ 1711 RV_Reinigung_Anf 5000;
BA_REL_ "GenSigTimeoutTime" BU_SG_REL_ ZR_High SG_ 1711 RV_Settings_enabled 5000;
BA_REL_ "GenSigTimeoutTime" BU_SG_REL_ ZR_High SG_ 1711 RV_Menu_Item 5000;
BA_REL_ "GenSigTimeoutTime" BU_SG_REL_ ZR_High SG_ 1711 SV_Video_on 5000;
BA_REL_ "GenSigTimeoutTime" BU_SG_REL_ ZR_High SG_ 1711 RV_Calib_Fehler 5000;
BA_REL_ "GenSigTimeoutTime" BU_SG_REL_ ZR_High SG_ 1711 RV_GL_Trailer_connect 5000;
BA_REL_ "GenSigTimeoutTime" BU_SG_REL_ ZR_High SG_ 1711 RV_GL_Trunk_open 5000;
BA_REL_ "GenSigTimeoutTime" BU_SG_REL_ ZR_High SG_ 1711 RV_GL_LWS_Fehler 5000;
BA_REL_ "GenSigTimeoutTime" BU_SG_REL_ ZR_High SG_ 1711 RV_Helligkeit 5000;
BA_REL_ "GenSigTimeoutTime" BU_SG_REL_ ZR_High SG_ 1711 RV_Kontrast 5000;
BA_REL_ "GenSigTimeoutTime" BU_SG_REL_ ZR_High SG_ 1711 RV_Farbe 5000;
BA_REL_ "GenSigTimeoutTime" BU_SG_REL_ ZR_High SG_ 1440 LS_Helligkeit_IR 2000;
BA_REL_ "GenSigTimeoutTime" BU_SG_REL_ ZR_High SG_ 1440 LS_Helligkeit_FW 2000;
BA_REL_ "GenSigTimeoutTime" BU_SG_REL_ ZR_High SG_ 1440 LS_defekt 2000;
BA_REL_ "GenSigTimeoutTime" BU_SG_REL_ ZR_High SG_ 1440 LS_Verbau 2000;
BA_REL_ "GenSigTimeoutTime" BU_SG_REL_ ZR_High SG_ 1440 RS_Regenmenge 2000;
BA_REL_ "GenSigTimeoutTime" BU_SG_REL_ ZR_High SG_ 1440 RS_Verbau 2000;
BA_REL_ "GenSigTimeoutTime" BU_SG_REL_ ZR_High SG_ 1440 RS_Verglasung_schliessen 2000;
BA_REL_ "GenSigTimeoutTime" BU_SG_REL_ ZR_High SG_ 1440 RS_defekt 2000;
BA_REL_ "GenSigTimeoutTime" BU_SG_REL_ ZR_High SG_ 1440 RS_Wischergeschwindigkeit 2000;
BA_REL_ "GenSigTimeoutTime" BU_SG_REL_ ZR_High SG_ 1440 RLS_Vorfeldhelligkeit_Boost 2000;
BA_REL_ "GenSigTimeoutTime" BU_SG_REL_ ZR_High SG_ 1504 MD1_Position 5000;
BA_REL_ "GenSigTimeoutTime" BU_SG_REL_ ZR_High SG_ 1504 MD1_Lage 5000;
BA_REL_ "GenSigTimeoutTime" BU_SG_REL_ ZR_High SG_ 1504 MD3_Position 5000;
BA_REL_ "GenSigTimeoutTime" BU_SG_REL_ ZR_High SG_ 1504 MD3_Lage 5000;
BA_REL_ "GenSigTimeoutTime" BU_SG_REL_ ZR_High SG_ 1504 MRollo_Position 5000;
BA_REL_ "GenSigTimeoutTime" BU_SG_REL_ ZR_High SG_ 1504 MRollo_Lage 5000;
BA_REL_ "GenSigTimeoutTime" BU_SG_REL_ ZR_High SG_ 1504 SAD_normiert 5000;
BA_REL_ "GenSigTimeoutTime" BU_SG_REL_ ZR_High SG_ 1504 SAD_Thermoschutz 5000;
BA_REL_ "GenSigTimeoutTime" BU_SG_REL_ ZR_High SG_ 1504 SAD_UEKB_aktiv 5000;
BA_REL_ "GenSigTimeoutTime" BU_SG_REL_ ZR_High SG_ 1504 Rollo_normiert 5000;
BA_REL_ "GenSigTimeoutTime" BU_SG_REL_ ZR_High SG_ 1504 Rollo_Thermoschutz 5000;
BA_REL_ "GenSigTimeoutTime" BU_SG_REL_ ZR_High SG_ 1504 Rollo_UEKB_aktiv 5000;
BA_REL_ "GenSigTimeoutTime" BU_SG_REL_ ZR_High SG_ 1504 SAD_Taster_Deckel_hi 5000;
BA_REL_ "GenSigTimeoutTime" BU_SG_REL_ ZR_High SG_ 1504 SAD_Taster_Deckel_vo 5000;
BA_REL_ "GenSigTimeoutTime" BU_SG_REL_ ZR_High SG_ 1504 SAD_Taster_Rollo_hi 5000;
BA_REL_ "GenSigTimeoutTime" BU_SG_REL_ ZR_High SG_ 249 SARA_QBit_Nickwinkel 5000;
BA_REL_ "GenSigTimeoutTime" BU_SG_REL_ ZR_High SG_ 249 SARA_QBit_Wankwinkel 5000;
BA_REL_ "GenSigTimeoutTime" BU_SG_REL_ ZR_High SG_ 249 SARA_Nickwinkel 5000;
BA_REL_ "GenSigTimeoutTime" BU_SG_REL_ ZR_High SG_ 249 SARA_Wankwinkel 5000;
BA_REL_ "GenSigTimeoutTime" BU_SG_REL_ ZR_High SG_ 378 SARA_Accel_Y_010_02 1000;
BA_REL_ "GenSigTimeoutTime" BU_SG_REL_ ZR_High SG_ 378 SARA_Accel_X_010_02 1000;
BA_REL_ "GenSigTimeoutTime" BU_SG_REL_ ZR_High SG_ 378 SARA_CF_Accel_X_010_02 1000;
BA_REL_ "GenSigTimeoutTime" BU_SG_REL_ ZR_High SG_ 378 SARA_CF_Accel_Y_010_02 1000;
BA_REL_ "GenSigTimeoutTime" BU_SG_REL_ ZR_High SG_ 424 SARA_Accel_X_r 500;
BA_REL_ "GenSigTimeoutTime" BU_SG_REL_ ZR_High SG_ 424 SARA_Accel_Y_r 500;
BA_REL_ "GenSigTimeoutTime" BU_SG_REL_ ZR_High SG_ 424 SARA_Omega_Z_r 500;
BA_REL_ "GenSigTimeoutTime" BU_SG_REL_ ZR_High SG_ 424 SARA_CF_Accel_X_r 500;
BA_REL_ "GenSigTimeoutTime" BU_SG_REL_ ZR_High SG_ 424 SARA_CF_Accel_Y_r 500;
BA_REL_ "GenSigTimeoutTime" BU_SG_REL_ ZR_High SG_ 424 SARA_CF_Omega_Z_r 500;
BA_REL_ "GenSigTimeoutTime" BU_SG_REL_ ZR_High SG_ 1011 SCR_Sent_Levelsignal_Status 1000;
BA_REL_ "GenSigTimeoutTime" BU_SG_REL_ ZR_High SG_ 1011 SCR_Druck 1000;
BA_REL_ "GenSigTimeoutTime" BU_SG_REL_ ZR_High SG_ 1011 SCR_Level_Aktivtank 1000;
BA_REL_ "GenSigTimeoutTime" BU_SG_REL_ ZR_High SG_ 1011 SCR_Sent_Level_Aktivtank 1000;
BA_REL_ "GenSigTimeoutTime" BU_SG_REL_ ZR_High SG_ 1507 SCR_Temp_Aktivtank 5000;
BA_REL_ "GenSigTimeoutTime" BU_SG_REL_ ZR_High SG_ 1526 SCR_Level_Aktivtank_OOR4Quality 5000;
BA_REL_ "GenSigTimeoutTime" BU_SG_REL_ ZR_High SG_ 1526 SCR_Level_Aktivtank_OOR_minus 5000;
BA_REL_ "GenSigTimeoutTime" BU_SG_REL_ ZR_High SG_ 1526 SCR_Sent_1_Signalstatus 5000;
BA_REL_ "GenSigTimeoutTime" BU_SG_REL_ ZR_High SG_ 1526 SCR_Sent_1_elektrischer_Status 5000;
BA_REL_ "GenSigTimeoutTime" BU_SG_REL_ ZR_High SG_ 1526 SCR_Sent_Levelsensor 5000;
BA_REL_ "GenSigTimeoutTime" BU_SG_REL_ ZR_High SG_ 1526 SCR_Sent_Qualitaetssensor 5000;
BA_REL_ "GenSigTimeoutTime" BU_SG_REL_ ZR_High SG_ 1526 SCR_Sent_Temperatursensor 5000;
BA_REL_ "GenSigTimeoutTime" BU_SG_REL_ ZR_High SG_ 1526 SCR_DEF_Qualitaet_Medium 5000;
BA_REL_ "GenSigTimeoutTime" BU_SG_REL_ ZR_High SG_ 1526 SCR_Temp_DEF2_Sensor_Status 5000;
BA_REL_ "GenSigTimeoutTime" BU_SG_REL_ ZR_High SG_ 1526 SCR_Sent_2_elektrischer_Status 5000;
BA_REL_ "GenSigTimeoutTime" BU_SG_REL_ ZR_High SG_ 1526 SCR_HAL_Sensorik_Status 5000;
BA_REL_ "GenSigTimeoutTime" BU_SG_REL_ ZR_High SG_ 1526 SCR_Steuergeraet_Heizung_Status 5000;
BA_REL_ "GenSigTimeoutTime" BU_SG_REL_ ZR_High SG_ 1526 SCR_Steuergeraet_Pumpe_Status 5000;
BA_REL_ "GenSigTimeoutTime" BU_SG_REL_ ZR_High SG_ 1526 SCR_Steuergeraet_Relais_Status 5000;
BA_REL_ "GenSigTimeoutTime" BU_SG_REL_ ZR_High SG_ 1526 SCR_Steuergeraet_Bus_Status 5000;
BA_REL_ "GenSigTimeoutTime" BU_SG_REL_ ZR_High SG_ 1526 SCR_ECU_Datensatz_Status 5000;
BA_REL_ "GenSigTimeoutTime" BU_SG_REL_ ZR_High SG_ 1526 SCR_Steuergeraet_Defekt_Status 5000;
BA_REL_ "GenSigTimeoutTime" BU_SG_REL_ ZR_High SG_ 873 SDF2_Pos_Inhibitzeit 800;
BA_REL_ "GenSigTimeoutTime" BU_SG_REL_ ZR_High SG_ 873 SDF2_Pos_Segment_ID 800;
BA_REL_ "GenSigTimeoutTime" BU_SG_REL_ ZR_High SG_ 873 SDF2_Pos_Offset 800;
BA_REL_ "GenSigTimeoutTime" BU_SG_REL_ ZR_High SG_ 873 SDF2_Pos_Standort_Eindeutig 800;
BA_REL_ "GenSigTimeoutTime" BU_SG_REL_ ZR_High SG_ 873 SDF2_Pos_Distanz_Rampe_rechts 800;
BA_REL_ "GenSigTimeoutTime" BU_SG_REL_ ZR_High SG_ 873 SDF2_Pos_Spurtype 800;
BA_REL_ "GenSigTimeoutTime" BU_SG_REL_ ZR_High SG_ 873 SDF2_Pos_Distanz_Rampe_links 800;
BA_REL_ "GenSigTimeoutTime" BU_SG_REL_ ZR_High SG_ 873 SDF2_Pos_AnzRampenRechts 800;
BA_REL_ "GenSigTimeoutTime" BU_SG_REL_ ZR_High SG_ 873 SDF2_Pos_AnzRampenLinks 800;
BA_REL_ "GenSigTimeoutTime" BU_SG_REL_ ZR_High SG_ 873 SDF2_Pos_Fehler_Laengsrichtung 800;
BA_REL_ "GenSigTimeoutTime" BU_SG_REL_ ZR_High SG_ 873 SDF2_Pos_AnzHauptspuren 800;
BA_REL_ "GenSigTimeoutTime" BU_SG_REL_ ZR_High SG_ 873 SDF2_Pos_Spurnummer 800;
BA_REL_ "GenSigTimeoutTime" BU_SG_REL_ ZR_High SG_ 873 SDF2_Pos_GueteZuordnung 800;
BA_REL_ "GenSigTimeoutTime" BU_SG_REL_ ZR_High SG_ 201 SM_Parken_Manoever 500;
BA_REL_ "GenSigTimeoutTime" BU_SG_REL_ ZR_High SG_ 201 SM_Parken_Szenario 500;
BA_REL_ "GenSigTimeoutTime" BU_SG_REL_ ZR_High SG_ 201 SM_Parken_Seite 500;
BA_REL_ "GenSigTimeoutTime" BU_SG_REL_ ZR_High SG_ 201 SM_Parken_Richtung 500;
BA_REL_ "GenSigTimeoutTime" BU_SG_REL_ ZR_High SG_ 201 SM_Parken_Verbindungsstatus 500;
BA_REL_ "GenSigTimeoutTime" BU_SG_REL_ ZR_High SG_ 201 SM_Parken_Kommando 500;
BA_REL_ "GenSigTimeoutTime" BU_SG_REL_ ZR_High SG_ 2527679651 SM_Parken_Hupe_Anf 2000;
BA_REL_ "GenSigTimeoutTime" BU_SG_REL_ ZR_High SG_ 2527679651 SM_Parken_UGDO_Anf 2000;
BA_REL_ "GenSigTimeoutTime" BU_SG_REL_ ZR_High SG_ 2527679651 SM_Parken_UGDO_Aktion 2000;
BA_REL_ "GenSigTimeoutTime" BU_SG_REL_ ZR_High SG_ 2527679651 SM_Parken_Komfortschliessen_Anf 2000;
BA_REL_ "GenSigTimeoutTime" BU_SG_REL_ ZR_High SG_ 980 BH_Blinker_li 2000;
BA_REL_ "GenSigTimeoutTime" BU_SG_REL_ ZR_High SG_ 980 BH_Blinker_re 2000;
BA_REL_ "GenSigTimeoutTime" BU_SG_REL_ ZR_High SG_ 980 BH_Lichthupe 2000;
BA_REL_ "GenSigTimeoutTime" BU_SG_REL_ ZR_High SG_ 980 BH_Fernlicht 2000;
BA_REL_ "GenSigTimeoutTime" BU_SG_REL_ ZR_High SG_ 980 WH_Tipwischen 2000;
BA_REL_ "GenSigTimeoutTime" BU_SG_REL_ ZR_High SG_ 980 WH_Intervall 2000;
BA_REL_ "GenSigTimeoutTime" BU_SG_REL_ ZR_High SG_ 980 WH_WischerStufe1 2000;
BA_REL_ "GenSigTimeoutTime" BU_SG_REL_ ZR_High SG_ 980 WH_WischerStufe2 2000;
BA_REL_ "GenSigTimeoutTime" BU_SG_REL_ ZR_High SG_ 980 WH_Frontwaschen 2000;
BA_REL_ "GenSigTimeoutTime" BU_SG_REL_ ZR_High SG_ 980 WH_Heckintervall 2000;
BA_REL_ "GenSigTimeoutTime" BU_SG_REL_ ZR_High SG_ 980 WH_Heckwaschen 2000;
BA_REL_ "GenSigTimeoutTime" BU_SG_REL_ ZR_High SG_ 980 WH_Intervallstufen 2000;
BA_REL_ "GenSigTimeoutTime" BU_SG_REL_ ZR_High SG_ 980 FAS_Taster 2000;
BA_REL_ "GenSigTimeoutTime" BU_SG_REL_ ZR_High SG_ 980 FAS_Taster_Fehler 2000;
BA_REL_ "GenSigTimeoutTime" BU_SG_REL_ ZR_High SG_ 980 LRH_On_Off 2000;
BA_REL_ "GenSigTimeoutTime" BU_SG_REL_ ZR_High SG_ 980 LRH_aktiv 2000;
BA_REL_ "GenSigTimeoutTime" BU_SG_REL_ ZR_High SG_ 980 WH_SRA 2000;
BA_REL_ "GenSigTimeoutTime" BU_SG_REL_ ZR_High SG_ 980 WH_Wischer_Fehler 2000;
BA_REL_ "GenSigTimeoutTime" BU_SG_REL_ ZR_High SG_ 980 BH_Blinker_Fehler 2000;
BA_REL_ "GenSigTimeoutTime" BU_SG_REL_ ZR_High SG_ 980 SMLS_PTT 2000;
BA_REL_ "GenSigTimeoutTime" BU_SG_REL_ ZR_High SG_ 980 WH_Tipwischen_lang 2000;
BA_REL_ "GenSigTimeoutTime" BU_SG_REL_ ZR_High SG_ 1467 SoSe_SunInt_2D_Li 5000;
BA_REL_ "GenSigTimeoutTime" BU_SG_REL_ ZR_High SG_ 1467 SoSe_SunInt_2D_Re 5000;
BA_REL_ "GenSigTimeoutTime" BU_SG_REL_ ZR_High SG_ 1710 SP_FT_oben 5000;
BA_REL_ "GenSigTimeoutTime" BU_SG_REL_ ZR_High SG_ 1710 SP_FT_unten 5000;
BA_REL_ "GenSigTimeoutTime" BU_SG_REL_ ZR_High SG_ 1710 SP_FT_links 5000;
BA_REL_ "GenSigTimeoutTime" BU_SG_REL_ ZR_High SG_ 1710 SP_FT_rechts 5000;
BA_REL_ "GenSigTimeoutTime" BU_SG_REL_ ZR_High SG_ 1710 SP_BT_oben 5000;
BA_REL_ "GenSigTimeoutTime" BU_SG_REL_ ZR_High SG_ 1710 SP_BT_unten 5000;
BA_REL_ "GenSigTimeoutTime" BU_SG_REL_ ZR_High SG_ 1710 SP_BT_links 5000;
BA_REL_ "GenSigTimeoutTime" BU_SG_REL_ ZR_High SG_ 1710 SP_BT_rechts 5000;
BA_REL_ "GenSigTimeoutTime" BU_SG_REL_ ZR_High SG_ 1710 SP_abklappen 5000;
BA_REL_ "GenSigTimeoutTime" BU_SG_REL_ ZR_High SG_ 1710 SP_anklappen 5000;
BA_REL_ "GenSigTimeoutTime" BU_SG_REL_ ZR_High SG_ 1710 SP_normieren 5000;
BA_REL_ "GenSigTimeoutTime" BU_SG_REL_ ZR_High SG_ 1710 SP_Hzg_Taster 5000;
BA_REL_ "GenSigTimeoutTime" BU_SG_REL_ ZR_High SG_ 1710 SP_S_oben 5000;
BA_REL_ "GenSigTimeoutTime" BU_SG_REL_ ZR_High SG_ 1710 SP_S_unten 5000;
BA_REL_ "GenSigTimeoutTime" BU_SG_REL_ ZR_High SG_ 1710 SP_S_links 5000;
BA_REL_ "GenSigTimeoutTime" BU_SG_REL_ ZR_High SG_ 1710 SP_S_rechts 5000;
BA_REL_ "GenSigTimeoutTime" BU_SG_REL_ ZR_High SG_ 1710 SP_Auswahl_li 5000;
BA_REL_ "GenSigTimeoutTime" BU_SG_REL_ ZR_High SG_ 1710 SP_Auswahl_re 5000;
BA_REL_ "GenSigTimeoutTime" BU_SG_REL_ ZR_High SG_ 1710 SP_ARA_Status 5000;
BA_REL_ "GenSigTimeoutTime" BU_SG_REL_ ZR_High SG_ 1710 SP_S_Klappen 5000;
BA_REL_ "GenSigTimeoutTime" BU_SG_REL_ ZR_High SG_ 1710 SP_Verstellschalter_Fehler 5000;
BA_REL_ "GenSigTimeoutTime" BU_SG_REL_ ZR_LIMU SG_ 2527679790 RTM_Fehlerstatus 5000;
BA_REL_ "GenSigTimeoutTime" BU_SG_REL_ ZR_LIMU SG_ 2527679790 RTM_IstModus 5000;
BA_REL_ "GenSigTimeoutTime" BU_SG_REL_ ZR_LIMU SG_ 2527679790 RTM_OTA_SignalStrength 5000;
BA_REL_ "GenSigTimeoutTime" BU_SG_REL_ ZR_LIMU SG_ 2527679790 RTM_OTA_InstallProcess 5000;
BA_REL_ "GenSigTimeoutTime" BU_SG_REL_ ZR_LIMU SG_ 2527679790 RTM_OTA_InstallPrecondition 5000;
BA_REL_ "GenSigTimeoutTime" BU_SG_REL_ ZR_LIMU SG_ 2527679790 RTM_OTA_InstallDuration 5000;
BA_REL_ "GenSigTimeoutTime" BU_SG_REL_ ZR_LIMU SG_ 2527679790 RTM_OTA_Download_Speed 5000;
BA_REL_ "GenSigTimeoutTime" BU_SG_REL_ ZR_LIMU SG_ 2527679790 RTM_OTA_Download_Size 5000;
BA_REL_ "GenSigTimeoutTime" BU_SG_REL_ ZR_LIMU SG_ 2527679790 RTM_OTA_Download_Process 5000;
BA_REL_ "GenSigTimeoutTime" BU_SG_REL_ ZR_LIMU SG_ 1504 MD1_Position 5000;
BA_REL_ "GenSigTimeoutTime" BU_SG_REL_ ZR_LIMU SG_ 1504 MD1_Lage 5000;
BA_REL_ "GenSigTimeoutTime" BU_SG_REL_ ZR_LIMU SG_ 1504 MD3_Position 5000;
BA_REL_ "GenSigTimeoutTime" BU_SG_REL_ ZR_LIMU SG_ 1504 MD3_Lage 5000;
BA_REL_ "GenSigTimeoutTime" BU_SG_REL_ ZR_LIMU SG_ 249 SARA_QBit_Nickwinkel 5000;
BA_REL_ "GenSigTimeoutTime" BU_SG_REL_ ZR_LIMU SG_ 249 SARA_QBit_Wankwinkel 5000;
BA_REL_ "GenSigTimeoutTime" BU_SG_REL_ ZR_LIMU SG_ 249 SARA_Nickwinkel 5000;
BA_REL_ "GenSigTimeoutTime" BU_SG_REL_ ZR_LIMU SG_ 249 SARA_Wankwinkel 5000;
BA_REL_ "GenSigTimeoutTime" BU_SG_REL_ ZR_LIMU SG_ 378 SARA_Accel_Y_010_02 1000;
BA_REL_ "GenSigTimeoutTime" BU_SG_REL_ ZR_LIMU SG_ 378 SARA_Accel_X_010_02 1000;
BA_REL_ "GenSigTimeoutTime" BU_SG_REL_ ZR_LIMU SG_ 378 SARA_Omega_Z_010_02 1000;
BA_REL_ "GenSigTimeoutTime" BU_SG_REL_ ZR_LIMU SG_ 378 SARA_CF_Accel_X_010_02 1000;
BA_REL_ "GenSigTimeoutTime" BU_SG_REL_ ZR_LIMU SG_ 378 SARA_CF_Accel_Y_010_02 1000;
BA_REL_ "GenSigTimeoutTime" BU_SG_REL_ ZR_LIMU SG_ 378 SARA_CF_Omega_Z_010_02 1000;
BA_REL_ "GenSigTimeoutTime" BU_SG_REL_ ZR_LIMU SG_ 424 SARA_Accel_X_r 500;
BA_REL_ "GenSigTimeoutTime" BU_SG_REL_ ZR_LIMU SG_ 424 SARA_Accel_Y_r 500;
BA_REL_ "GenSigTimeoutTime" BU_SG_REL_ ZR_LIMU SG_ 424 SARA_Omega_Z_r 500;
BA_REL_ "GenSigTimeoutTime" BU_SG_REL_ ZR_LIMU SG_ 424 SARA_CF_Accel_X_r 500;
BA_REL_ "GenSigTimeoutTime" BU_SG_REL_ ZR_LIMU SG_ 424 SARA_CF_Accel_Y_r 500;
BA_REL_ "GenSigTimeoutTime" BU_SG_REL_ ZR_LIMU SG_ 424 SARA_CF_Omega_Z_r 500;
BA_REL_ "GenSigTimeoutTime" BU_SG_REL_ ZR_LIMU SG_ 873 SDF2_Pos_Inhibitzeit 800;
BA_REL_ "GenSigTimeoutTime" BU_SG_REL_ ZR_LIMU SG_ 873 SDF2_Pos_Segment_ID 800;
BA_REL_ "GenSigTimeoutTime" BU_SG_REL_ ZR_LIMU SG_ 873 SDF2_Pos_Offset 800;
BA_REL_ "GenSigTimeoutTime" BU_SG_REL_ ZR_LIMU SG_ 873 SDF2_Pos_Standort_Eindeutig 800;
BA_REL_ "GenSigTimeoutTime" BU_SG_REL_ ZR_LIMU SG_ 873 SDF2_Pos_Distanz_Rampe_rechts 800;
BA_REL_ "GenSigTimeoutTime" BU_SG_REL_ ZR_LIMU SG_ 873 SDF2_Pos_Spurtype 800;
BA_REL_ "GenSigTimeoutTime" BU_SG_REL_ ZR_LIMU SG_ 873 SDF2_Pos_Distanz_Rampe_links 800;
BA_REL_ "GenSigTimeoutTime" BU_SG_REL_ ZR_LIMU SG_ 873 SDF2_Pos_AnzRampenRechts 800;
BA_REL_ "GenSigTimeoutTime" BU_SG_REL_ ZR_LIMU SG_ 873 SDF2_Pos_AnzRampenLinks 800;
BA_REL_ "GenSigTimeoutTime" BU_SG_REL_ ZR_LIMU SG_ 873 SDF2_Pos_Fehler_Laengsrichtung 800;
BA_REL_ "GenSigTimeoutTime" BU_SG_REL_ ZR_LIMU SG_ 873 SDF2_Pos_AnzHauptspuren 800;
BA_REL_ "GenSigTimeoutTime" BU_SG_REL_ ZR_LIMU SG_ 873 SDF2_Pos_Spurnummer 800;
BA_REL_ "GenSigTimeoutTime" BU_SG_REL_ ZR_LIMU SG_ 873 SDF2_Pos_GueteZuordnung 800;
BA_REL_ "GenSigTimeoutTime" BU_SG_REL_ ZR_LIMU SG_ 980 SMLS_PTT 2000;
BA_REL_ "GenSigTimeoutTime" BU_SG_REL_ ZR_MIB_TOP_ab_Gen3 SG_ 906 QSP_Warnlampe 1000;
BA_REL_ "GenSigTimeoutTime" BU_SG_REL_ ZR_MIB_TOP_ab_Gen3 SG_ 906 QSP_Thermische_Belastung 1000;
BA_REL_ "GenSigTimeoutTime" BU_SG_REL_ ZR_MIB_TOP_ab_Gen3 SG_ 906 QSP_Temperatur_Oel 1000;
BA_REL_ "GenSigTimeoutTime" BU_SG_REL_ ZR_MIB_TOP_ab_Gen3 SG_ 2527679790 RTM_Fehlerstatus 5000;
BA_REL_ "GenSigTimeoutTime" BU_SG_REL_ ZR_MIB_TOP_ab_Gen3 SG_ 2527679790 RTM_IstModus 5000;
BA_REL_ "GenSigTimeoutTime" BU_SG_REL_ ZR_MIB_TOP_ab_Gen3 SG_ 2527679790 RTM_OTA_SignalStrength 5000;
BA_REL_ "GenSigTimeoutTime" BU_SG_REL_ ZR_MIB_TOP_ab_Gen3 SG_ 2527679790 RTM_OTA_InstallProcess 5000;
BA_REL_ "GenSigTimeoutTime" BU_SG_REL_ ZR_MIB_TOP_ab_Gen3 SG_ 2527679790 RTM_OTA_InstallPrecondition 5000;
BA_REL_ "GenSigTimeoutTime" BU_SG_REL_ ZR_MIB_TOP_ab_Gen3 SG_ 2527679790 RTM_OTA_InstallDuration 5000;
BA_REL_ "GenSigTimeoutTime" BU_SG_REL_ ZR_MIB_TOP_ab_Gen3 SG_ 2527679790 RTM_OTA_Download_Speed 5000;
BA_REL_ "GenSigTimeoutTime" BU_SG_REL_ ZR_MIB_TOP_ab_Gen3 SG_ 2527679790 RTM_OTA_Download_Size 5000;
BA_REL_ "GenSigTimeoutTime" BU_SG_REL_ ZR_MIB_TOP_ab_Gen3 SG_ 2527679790 RTM_OTA_Download_Process 5000;
BA_REL_ "GenSigTimeoutTime" BU_SG_REL_ ZR_MIB_TOP_ab_Gen3 SG_ 1504 MD1_Position 5000;
BA_REL_ "GenSigTimeoutTime" BU_SG_REL_ ZR_MIB_TOP_ab_Gen3 SG_ 1504 MD1_Lage 5000;
BA_REL_ "GenSigTimeoutTime" BU_SG_REL_ ZR_MIB_TOP_ab_Gen3 SG_ 1504 MD3_Position 5000;
BA_REL_ "GenSigTimeoutTime" BU_SG_REL_ ZR_MIB_TOP_ab_Gen3 SG_ 1504 MD3_Lage 5000;
BA_REL_ "GenSigTimeoutTime" BU_SG_REL_ ZR_MIB_TOP_ab_Gen3 SG_ 249 SARA_QBit_Nickwinkel 5000;
BA_REL_ "GenSigTimeoutTime" BU_SG_REL_ ZR_MIB_TOP_ab_Gen3 SG_ 249 SARA_QBit_Wankwinkel 5000;
BA_REL_ "GenSigTimeoutTime" BU_SG_REL_ ZR_MIB_TOP_ab_Gen3 SG_ 249 SARA_Nickwinkel 5000;
BA_REL_ "GenSigTimeoutTime" BU_SG_REL_ ZR_MIB_TOP_ab_Gen3 SG_ 249 SARA_Wankwinkel 5000;
BA_REL_ "GenSigTimeoutTime" BU_SG_REL_ ZR_MIB_TOP_ab_Gen3 SG_ 378 SARA_Accel_Y_010_02 1000;
BA_REL_ "GenSigTimeoutTime" BU_SG_REL_ ZR_MIB_TOP_ab_Gen3 SG_ 378 SARA_Accel_X_010_02 1000;
BA_REL_ "GenSigTimeoutTime" BU_SG_REL_ ZR_MIB_TOP_ab_Gen3 SG_ 378 SARA_Omega_Z_010_02 1000;
BA_REL_ "GenSigTimeoutTime" BU_SG_REL_ ZR_MIB_TOP_ab_Gen3 SG_ 378 SARA_CF_Accel_X_010_02 1000;
BA_REL_ "GenSigTimeoutTime" BU_SG_REL_ ZR_MIB_TOP_ab_Gen3 SG_ 378 SARA_CF_Accel_Y_010_02 1000;
BA_REL_ "GenSigTimeoutTime" BU_SG_REL_ ZR_MIB_TOP_ab_Gen3 SG_ 378 SARA_CF_Omega_Z_010_02 1000;
BA_REL_ "GenSigTimeoutTime" BU_SG_REL_ ZR_MIB_TOP_ab_Gen3 SG_ 424 SARA_Accel_X_r 500;
BA_REL_ "GenSigTimeoutTime" BU_SG_REL_ ZR_MIB_TOP_ab_Gen3 SG_ 424 SARA_Accel_Y_r 500;
BA_REL_ "GenSigTimeoutTime" BU_SG_REL_ ZR_MIB_TOP_ab_Gen3 SG_ 424 SARA_Omega_Z_r 500;
BA_REL_ "GenSigTimeoutTime" BU_SG_REL_ ZR_MIB_TOP_ab_Gen3 SG_ 424 SARA_CF_Accel_X_r 500;
BA_REL_ "GenSigTimeoutTime" BU_SG_REL_ ZR_MIB_TOP_ab_Gen3 SG_ 424 SARA_CF_Accel_Y_r 500;
BA_REL_ "GenSigTimeoutTime" BU_SG_REL_ ZR_MIB_TOP_ab_Gen3 SG_ 424 SARA_CF_Omega_Z_r 500;
BA_REL_ "GenSigTimeoutTime" BU_SG_REL_ ZR_MIB_TOP_ab_Gen3 SG_ 873 SDF2_Pos_Inhibitzeit 800;
BA_REL_ "GenSigTimeoutTime" BU_SG_REL_ ZR_MIB_TOP_ab_Gen3 SG_ 873 SDF2_Pos_Segment_ID 800;
BA_REL_ "GenSigTimeoutTime" BU_SG_REL_ ZR_MIB_TOP_ab_Gen3 SG_ 873 SDF2_Pos_Offset 800;
BA_REL_ "GenSigTimeoutTime" BU_SG_REL_ ZR_MIB_TOP_ab_Gen3 SG_ 873 SDF2_Pos_Standort_Eindeutig 800;
BA_REL_ "GenSigTimeoutTime" BU_SG_REL_ ZR_MIB_TOP_ab_Gen3 SG_ 873 SDF2_Pos_Distanz_Rampe_rechts 800;
BA_REL_ "GenSigTimeoutTime" BU_SG_REL_ ZR_MIB_TOP_ab_Gen3 SG_ 873 SDF2_Pos_Spurtype 800;
BA_REL_ "GenSigTimeoutTime" BU_SG_REL_ ZR_MIB_TOP_ab_Gen3 SG_ 873 SDF2_Pos_Distanz_Rampe_links 800;
BA_REL_ "GenSigTimeoutTime" BU_SG_REL_ ZR_MIB_TOP_ab_Gen3 SG_ 873 SDF2_Pos_AnzRampenRechts 800;
BA_REL_ "GenSigTimeoutTime" BU_SG_REL_ ZR_MIB_TOP_ab_Gen3 SG_ 873 SDF2_Pos_AnzRampenLinks 800;
BA_REL_ "GenSigTimeoutTime" BU_SG_REL_ ZR_MIB_TOP_ab_Gen3 SG_ 873 SDF2_Pos_Fehler_Laengsrichtung 800;
BA_REL_ "GenSigTimeoutTime" BU_SG_REL_ ZR_MIB_TOP_ab_Gen3 SG_ 873 SDF2_Pos_AnzHauptspuren 800;
BA_REL_ "GenSigTimeoutTime" BU_SG_REL_ ZR_MIB_TOP_ab_Gen3 SG_ 873 SDF2_Pos_Spurnummer 800;
BA_REL_ "GenSigTimeoutTime" BU_SG_REL_ ZR_MIB_TOP_ab_Gen3 SG_ 873 SDF2_Pos_GueteZuordnung 800;
BA_REL_ "GenSigTimeoutTime" BU_SG_REL_ ZR_MIB_TOP_ab_Gen3 SG_ 980 SMLS_PTT 2000;
BA_REL_ "GenSigTimeoutTime" BU_SG_REL_ ZR_Standard SG_ 1711 RV_Video_on 5000;
BA_REL_ "GenSigTimeoutTime" BU_SG_REL_ ZR_Standard SG_ 1711 RV_Dark_Screen 5000;
BA_REL_ "GenSigTimeoutTime" BU_SG_REL_ ZR_Standard SG_ 1711 RV_HMI_Mode 5000;
BA_REL_ "GenSigTimeoutTime" BU_SG_REL_ ZR_Standard SG_ 1711 RV_GL_side 5000;
BA_REL_ "GenSigTimeoutTime" BU_SG_REL_ ZR_Standard SG_ 1711 RV_System_aktiv 5000;
BA_REL_ "GenSigTimeoutTime" BU_SG_REL_ ZR_Standard SG_ 1711 SV_Video_on 5000;
BA_REL_ "GenSigTimeoutTime" BU_SG_REL_ ZR_Standard SG_ 1711 RV_GL_Trailer_connect 5000;
BA_REL_ "GenSigTimeoutTime" BU_SG_REL_ ZR_Standard SG_ 1711 RV_GL_Trunk_open 5000;
BA_REL_ "GenSigTimeoutTime" BU_SG_REL_ ZR_Standard SG_ 1711 RV_Helligkeit 5000;
BA_REL_ "GenSigTimeoutTime" BU_SG_REL_ ZR_Standard SG_ 1711 RV_Kontrast 5000;
BA_REL_ "GenSigTimeoutTime" BU_SG_REL_ ZR_Standard SG_ 1711 RV_Farbe 5000;
BA_REL_ "GenSigTimeoutTime" BU_SG_REL_ ZR_Standard SG_ 424 SARA_Accel_X_r 500;
BA_REL_ "GenSigTimeoutTime" BU_SG_REL_ ZR_Standard SG_ 424 SARA_Accel_Y_r 500;
BA_REL_ "GenSigTimeoutTime" BU_SG_REL_ ZR_Standard SG_ 424 SARA_Omega_Z_r 500;
BA_REL_ "GenSigTimeoutTime" BU_SG_REL_ ZR_Standard SG_ 424 SARA_CF_Accel_X_r 500;
BA_REL_ "GenSigTimeoutTime" BU_SG_REL_ ZR_Standard SG_ 424 SARA_CF_Accel_Y_r 500;
BA_REL_ "GenSigTimeoutTime" BU_SG_REL_ ZR_Standard SG_ 424 SARA_CF_Omega_Z_r 500;
BA_REL_ "GenSigTimeoutTime" BU_SG_REL_ ZR_Standard SG_ 980 BH_Blinker_li 2000;
BA_REL_ "GenSigTimeoutTime" BU_SG_REL_ ZR_Standard SG_ 980 BH_Blinker_re 2000;
BA_REL_ "GenSigTimeoutTime" BU_SG_REL_ ZR_Standard SG_ 980 FAS_Taster 2000;
BA_REL_ "GenSigTimeoutTime" BU_SG_REL_ ZR_Standard SG_ 980 SMLS_PTT 2000;
VAL_ 1123 PSD_Pos_Segment_ID 0 "keine Position gegeben" 1 "Fehlerwert" ;
VAL_ 1123 PSD_Pos_Standort_Eindeutig 0 "mehrdeutiger_Standort" 1 "eindeutiger_Standort" ;
VAL_ 1123 PSD_Pos_Fehler_Laengsrichtung 0 "Init" 1 "< 2m" 2 "< 5m" 3 "< 10m" 4 "< 20m" 5 "< 50m" 6 "> 50m" 7 "Off-Road" ;
VAL_ 1123 PSD_Pos_Fahrspur 0 "unbekannt" 1 "Erste_Spur_von_rechts" 2 "Zweite_Spur_von_rechts" 3 "Dritte_Spur_von_rechts" 4 "Vierte_Spur_von_rechts" 5 "Fuenfte_Spur_von_rechts" 6 "Sechte_Spur_von_rechts" 7 "Siebte_oder_weitere_Spur_von_rechts" ;
VAL_ 1123 PSD_Attribut_Segment_ID_05 0 "keine_Segment_Information" 1 "Fehler" ;
VAL_ 1123 PSD_Attribut_1_ID 0 "keine_Information" ;
VAL_ 1123 PSD_Attribut_2_ID 0 "keine_Information" ;
VAL_ 1123 PSD_Attribute_Komplett_05 0 "Attribute_nicht_komplett" 1 "Attribute_komplett" ;
VAL_ 1124 PSD_06_Mux 0 "Init" ;
VAL_ 1124 PSD_Sys_Segment_ID 0 "keine Segmentinformationen vorhanden" 1 "nicht zulaessig" ;
VAL_ 1124 PSD_Attribut_Segment_ID 0 "keine_Segment_Information_vorhanden" 1 "Fehler" ;
VAL_ 1124 PSD_Ges_Segment_ID 0 "keine Segmentinformationen vorhanden" 1 "nicht zulaessig" ;
VAL_ 1124 PSD_Baum_Laenge_VZ 0 "Ost" 1 "West" ;
VAL_ 1124 PSD_Steigung_1_Segment_ID 0 "keine_Segment_Information_vorhanden" 1 "Fehler" ;
VAL_ 1124 PSD_Baum_Laenge 33554431 "keine_GPS_Information" ;
VAL_ 1124 PSD_Attribut_3_ID 0 "keine_Information" ;
VAL_ 1124 PSD_Steigung_1_A_Steigung 126 "mehr_als_15_Prozent" 127 "Steigung_unbekannt" ;
VAL_ 1124 PSD_Ges_Geschwindigkeit 0 "Kein Geschwindigkeitsgebot" 1 "0 km/h < v_max <  5 km/h" 2 "5 km/h < v_max < 10km/h" 3 "10 km/h < v_max < 15 km/h" 4 "15 km/h < v_max < 20 km/h" 5 "20 km/h < v_max < 25 km/h" 6 "25 km/h < v_max < 30 km/h" 7 "30 km/h < v_max < 35 km/h" 8 "35 km/h < v_max < 40 km/h" 9 "40 km/h < v_max < 45 km/h" 10 "45 km/h < v_max < 50 km/h" 11 "50 km/h < v_max < 60 km/h" 12 "60 km/h < v_max < 70 km/h" 13 "70 km/h < v_max < 80 km/h" 14 "80 km/h < v_max < 90 km/h" 15 "90 km/h < v_max < 100 km/h" 16 "100 km/h < v_max < 110 km/h" 17 "110 km/h < v_max < 120 km/h" 18 " 120 km/h < v_max < 130 km/h" 19 "130 km/h < v_max < 140 km/h" 20 "140 km/h < v_max < 150 km/h" 21 "150 km/h < v_max < 160 km/h" 22 "160 km/h < v_max" 23 "Geschwindigkeitsgebot aufgehoben" 24 "..0x1F ungültig" ;
VAL_ 1124 PSD_Steigung_1_A_Vorz 0 "Gefaelle" 1 "Steigung" ;
VAL_ 1124 PSD_Sys_Geschwindigkeit_Einheit 0 "km/h" 1 "mph" ;
VAL_ 1124 PSD_Sys_Verkehrsrichtung 0 "Rechtsverkehr" 1 "Linksverkehr" ;
VAL_ 1124 PSD_Sys_Geometrieguete 0 "Geringe_Guete" 1 "tbd" 2 "tbd" 3 "Hohe_Guete" ;
VAL_ 1124 PSD_Sys_Mapmatchingguete 0 "geringe_Guete" 1 "res" 2 "res" 3 "hohe_Guete" ;
VAL_ 1124 PSD_Ges_Typ 0 "Geschw_Klasse_des_Kartendatensuppliers" 1 "Explizit_abgeleiteten_Begrenzung" 2 "Durch_Gesetzg_vorgeg_allgem_Gebot_fuer_uebertr_Rahmenbed" 3 "Init" ;
VAL_ 1124 PSD_Sys_Alter_Karte 0 "kleiner_1_Jahr" 1 "1_Jahr" 2 "2_Jahre" 3 "3_Jahre" 4 "4_Jahre" 5 "5_Jahre" 6 "6_Jahre" 7 "groesser_7_Jahre" ;
VAL_ 1124 PSD_Ges_Spur_Geschw_Begrenzung 0 "Gebot_fuer_alle_spuren_gueltig" ;
VAL_ 1124 PSD_Steigung_1_B_Steigung 126 "mehr_als_15_Prozent" 127 "Steigung_unbekannt" ;
VAL_ 1124 PSD_Attribut_4_ID 0 "keine_Information" ;
VAL_ 1124 PSD_Sys_Zielfuehrung 0 "Zielfuehrung nicht aktiv" 1 "Zielfuehrung aktiv" ;
VAL_ 1124 PSD_Sys_US_State 0 "kein_US_State" 1 "Alabama" 2 "Alaska" 3 "Arkansas" 4 "Arizona" 5 "California" 6 "Colorado" 7 "Conneticut" 8 "District_of_Columbia" 9 "Delaware" 10 "Florida" 11 "Georgia" 12 "Hawaii" 13 "Idaho" 14 "Illinois" 15 "Iowa" 16 "Indiana" 17 "Kansas" 18 "Kentucky" 19 "Louisiana" 20 "Massachusetts" 21 "Maryland" 22 "Maine" 23 "Michigan" 24 "Minnesota" 25 "Missouri" 26 "Mississippi" 27 "Montana" 28 "North_Carolina" 29 "North_Dakota" 30 "Nebraska" 31 "Nevada" 32 "New_Hampshire" 33 "New_Jersey" 34 "New_Mexico" 35 "New_York" 36 "Ohio" 37 "Oklahoma" 38 "Oregon" 39 "Pennsylvania" 40 "Puerto_Rico" 41 "Rhode_Island" 42 "South_Carolina" 43 "South_Dakota" 44 "Tennessee" 45 "Texas" 46 "Utah" 47 "Virginia" 48 "Virgin_Islands" 49 "Vermont" 50 "Washington" 51 "Wisconsin" 52 "West_Virginia" 53 "Wyoming" ;
VAL_ 1124 PSD_Ges_Geschwindigkeit_Gespann 0 "alle Fahrzeuge" 1 "PKW mit Gespann" 2 "LKW, Busse, etc." ;
VAL_ 1124 PSD_Baum_Breite_VZ 0 "Nord" 1 "Sued" ;
VAL_ 1124 PSD_Ges_Geschwindigkeit_Witter 0 "Witterungsunabhängig" 1 "Nässe, Regen, Niederschlag" 2 "Glätte" 3 "Nebel" ;
VAL_ 1124 PSD_Steigung_1_B_Vorz 0 "Gefaelle" 1 "Steigung" ;
VAL_ 1124 PSD_Ges_Geschwindigkeit_Tag_Anf 0 "kein Beginn definiert" 1 "Montag" 2 "Dienstag" 3 "Mittwoch" 4 "Donnerstag" 5 "Freitag" 6 "Samstag" 7 "Sonntag" ;
VAL_ 1124 PSD_Ges_Geschwindigkeit_Tag_Ende 0 "kein Ende definiert" 1 "Montag" 2 "Dienstag" 3 "Mittwoch" 4 "Donnerstag" 5 "Freitag" 6 "Samstag" 7 "Sonntag" ;
VAL_ 1124 PSD_Sys_Quali_verfuegbar 0 "Qualitaetskriterien_nicht_verfuegbar" 1 "Qualitaetskriterien_verfuegbar" ;
VAL_ 1124 PSD_Sys_Zielfuehrung_geaendert 0 "Zielfuehrung_nicht_geaendert" 1 "Zielfuehrung_geaendert" ;
VAL_ 1124 PSD_Ges_Geschwindigkeit_Std_Anf 25 "kein Beginn für stundenweise Einschränkungen" ;
VAL_ 1124 PSD_Steigung_1_Attribute_kompl 0 "Steigungen_nicht_komplett" 1 "Steigungen_komplett" ;
VAL_ 1124 PSD_Sys_Geometrieguete_erweitert 0 "Init" ;
VAL_ 1124 PSD_Steigung_2_Segment_ID 0 "keine_Segment_Information_vorhanden" 1 "Fehler" ;
VAL_ 1124 PSD_Attribut_5_ID 0 "keine_Information" ;
VAL_ 1124 PSD_Ges_Geschwindigkeit_Std_Ende 25 "kein Ende für stundenweise Einschränkungen" ;
VAL_ 1124 PSD_Steigung_2_Steigung 126 "mehr_als_15_Prozent" 127 "Steigung_unbekannt" ;
VAL_ 1124 PSD_Ges_Ueberholverbot 0 "kein Überholverbot" 1 "alle Fahrzeuge" 2 "Überholverbot für PKW mit Gespann" 3 "Überholverbot für LKW, Busse, etc." ;
VAL_ 1124 PSD_Ges_Wechselverkehrszeichen 0 "Kein Wechselverkehrszeichen" 1 "Wechselverkehrszeichen links" 2 "Wechselverkehrszeichen rechts" 3 "Wechselverkehrszeichen links und rechts" 4 "Wechselverkerhszeichen über der Fahrbahn" ;
VAL_ 1124 PSD_Steigung_2_Vorz 0 "Gefaelle" 1 "Steigung" ;
VAL_ 1124 PSD_Wechselverkehrszeichen_Typ 0 "kein_Wechselverkehrszeichen" 1 "LED_Wechselverkehrszeichen" 2 "nicht_LED_Wechselverkehrszeichen" ;
VAL_ 1124 PSD_Ges_Gesetzlich_Kategorie 0 "kein_legales_Verbot" 1 "innerorts" 2 "ausserorts" 3 "Autobahn" ;
VAL_ 1124 PSD_Attribute_Komplett_06 0 "Attribute_nicht_komplett" 1 "Attribute_komplett" ;
VAL_ 1124 PSD_Ges_Gesetzlich_Zusatz 0 "kein_Zusatz_zu_legalem_Gebot" 1 "Anhaenger_Klasse_1" 2 "Anhaenger_Klasse_2" ;
VAL_ 1124 PSD_Ges_Verkehrszeichen_Quelle 0 "VZA_kein_Onlinedienst" 1 "nur_VZA" 2 "nur_VZO" 3 "VZA_und_VZO" ;
VAL_ 1124 PSD_Steigung_2_Attribute_kompl 0 "Steigungen_nicht_komplett" 1 "Steigungen_komplett" ;
VAL_ 1124 PSD_Ges_Attribute_Komplett 0 "Attribute_nicht_komplett" 1 "Attribute_komplett" ;
VAL_ 1125 PSD_LR_01_MUX 0 "Init" ;
VAL_ 1125 PSD_LR_Attribut_1_Wert 0 "Init" ;
VAL_ 1125 PSD_LR_Steigung_1_Vorz 0 "Gefaelle" 1 "Steigung" ;
VAL_ 1125 PSD_LR_Globale_Steigung_Vorz 0 "Gefaelle" 1 "Steigung" ;
VAL_ 1125 PSD_LR_Attribut_2_Wert 0 "Init" ;
VAL_ 1125 PSD_LR_Steigung_2_Vorz 0 "Gefaelle" 1 "Steigung" ;
VAL_ 1125 PSD_LR_Attribut_3_Wert 0 "Init" ;
VAL_ 1125 PSD_LR_Steigung_3_Vorz 0 "Gefaelle" 1 "Steigung" ;
VAL_ 1125 PSD_LR_Reset 0 "kein Reset" 1 "Reset" ;
VAL_ 906 QSP_Warnlampe 0 "Warnlampe aus" 1 "Warnlampe ein (Aufprüfen), zur Zeit nicht belegt" 2 "Warnlampe ein (Warnung)  =  Fehler" 3 "Warnlampe ein (Übertemperatur)" ;
VAL_ 906 QSP_Init 0 "Initisalierungsphase abgeschlossen" 1 "Initialisierungsphase laeuft" ;
VAL_ 906 QSP_Ist_Moment 1023 "Fehler" ;
VAL_ 906 QSP_Thermische_Belastung 63 "Fehler" ;
VAL_ 906 QSP_Temperatur_Oel 127 "Fehler" ;
VAL_ 906 QSP_Status 0 "Abgeschaltet" 1 "Init" 2 "Bereit" 3 "Normalbetrieb" 4 "Temporaer_beenden" 5 "Temporaer_abgeschaltet" 6 "Beendet_durch_Fehler" 7 "Abgeschaltet_aufgrund_Fehler" ;
VAL_ 1616 RA_Radio_Error_Flag 0 "kein_KD_Fehler" 1 "KD_Fehler" ;
VAL_ 1616 RA_Frequency_unit 0 "1_kHz" 1 "100_kHz" ;
VAL_ 1616 RA_AM_Tuning 0 "frequency_locked" 1 "AM_tuning" ;
VAL_ 1529 RDK_FMVSS138_Lampe 0 "RDK_WaLa_inaktiv" 1 "RDK_WaLa_aktiv" ;
VAL_ 1529 RDK_FMVSS138_MIL 0 "keine_Stoerungsanzeige" 1 "Stoerungsanzeige" ;
VAL_ 1529 RDK_Kalibrierung 0 "BAP_Kalibrierung" 1 "CAN_Kombitaster_Kalibrierung" ;
VAL_ 1529 RDK_Reifendruck_Lampe 0 "RDK_WaLa_inaktiv" 1 "RDK_WaLa_aktiv" ;
VAL_ 1529 RDK_Warnungen_02 0 "keine_Anzeige" 1 "Reifen_allgemein_Warnstufe_1" 2 "Reifen_vorne_links_Warnstufe_1" 3 "Reifen_vorne_rechts_Warnstufe_1" 4 "Reifen_hinten_links_Warnstufe_1" 5 "Reifen_hinten_rechts_Warnstufe_1" 6 "Reifen_allgemein_Warnstufe_2" 7 "Reifen_vorne_links_Warnstufe_2" 8 "Reifen_vorne_rechts_Warnstufe_2" 9 "Reifen_hinten_links_Warnstufe_2" 10 "Reifen_hinten_rechts_Warnstufe_2" 11 "Reifen_allgemein_Warnstufe_3" 12 "Reifen_vorne_links_Warnstufe_3" 13 "Reifen_vorne_rechts_Warnstufe_3" 14 "Reifen_hinten_links_Warnstufe_3" 15 "Reifen_hinten_rechts_Warnstufe_3" 16 "Akustikausgabe_Kalibrierung_io" 17 "Textausgabe_Kalibrierung_io" 18 "Akustik_Textausgabe_Kalibrier_io" 19 "RDK_aktiviert" 20 "RDK_deaktiviert" 21 "RDK_Systemstoerung" 22 "RDK_Systemstoerung_temporaer" 23 "V_Warnschwelle_1" 24 "V_Warnschwelle_2" 25 "Radwechsel_allgemein" 26 "Teilueberwachung" 27 "V_Warnschwelle_3" ;
VAL_ 1529 RDK_angelernt 0 "nicht_angelernt" 1 "angelernt" ;
VAL_ 1529 RDK_Reifentemperatur_Lampe 0 "RDK_WaLa_inaktiv" 1 "RDK_WaLa_aktiv" ;
VAL_ 1529 RDK_RS_aktiv 0 "inaktiv" 1 "aktiv" ;
VAL_ 1529 RDK_Text_7 0 "inaktiv" 1 "aktiv" ;
VAL_ 1529 RDK_W_1_Reifen_HL 0 "inaktiv" 1 "aktiv" ;
VAL_ 1529 RDK_W_1_Reifen_HR 0 "inaktiv" 1 "aktiv" ;
VAL_ 1529 RDK_W_1_Reifen_VL 0 "inaktiv" 1 "aktiv" ;
VAL_ 1529 RDK_W_1_Reifen_VR 0 "inaktiv" 1 "aktiv" ;
VAL_ 1529 RDK_W_2_Reifen_HL 0 "inaktiv" 1 "aktiv" ;
VAL_ 1529 RDK_W_2_Reifen_HR 0 "inaktiv" 1 "aktiv" ;
VAL_ 1529 RDK_W_2_Reifen_VL 0 "inaktiv" 1 "aktiv" ;
VAL_ 1529 RDK_W_2_Reifen_VR 0 "inaktiv" 1 "aktiv" ;
VAL_ 1711 RV_Video_on 0 "Kamerabild wird nicht angezeigt" 1 "Kamerabild wird angezeigt" ;
VAL_ 1711 RV_Dark_Screen 0 "Kamerabild nicht verdunkeln" 1 "Kamerabild verdunkeln" ;
VAL_ 1711 RV_HMI_Mode 0 "Parkluecke  (Modus 1)" 1 "Parallel zur Straße (Modus 2)" 2 "reserviert" 3 "Kalibrierung (nur Diagnose)" ;
VAL_ 1711 RV_GL_side 0 "Guidelines_abgeschaltet" 1 "Guidelines_Anzeige_rechte_Seite" 2 "Guiedelines_Anzeige_linke_Seite" 3 "Guiedelines_Anzeige_beide_Seiten" ;
VAL_ 1711 RV_System_aktiv 0 "System nicht betriebsbereit" 1 "System betriebsbereit" ;
VAL_ 1711 RV_Reinigung_Anf 0 "nicht_reinigen" 1 "reinigen" ;
VAL_ 1711 RV_Settings_enabled 0 "Menu 'Einstellungen' nicht aktiviert" 1 "Menu 'Einstellungen' aktiviert" ;
VAL_ 1711 RV_Menu_Item 0 "HMI Mode als ausgewaehlt markiert" 1 "Helligkeit als ausgewaehlt markiert" 2 "Kontrast als ausgewaehlt markiert" 3 "Farbsaettigung als ausgewaehlt markiert" ;
VAL_ 1711 SV_Video_on 0 "SideView_aus_/_nicht_verbaut" 1 "SideView_an" ;
VAL_ 1711 RV_Calib_Fehler 0 "Kalibrierung_i.O." 1 "RearView_nicht_kalibriert" ;
VAL_ 1711 RV_GL_Trailer_connect 0 "Guidelines_werden_angezeigt" 1 "Guidelines_wegen_angekoppeltem_Anhänger_deaktiviert" ;
VAL_ 1711 RV_GL_Trunk_open 0 "Guidelines_werden_angezeigt" 1 "Guidelines_wegen_geöffneter_Heckklappe_deaktiviert" ;
VAL_ 1711 RV_GL_LWS_Fehler 0 "Guidelines_werden_angezeigt" 1 "Guidelines_wegen_nicht_kalibriertem_Lenkwinkelsensor_deaktiviert" ;
VAL_ 1711 ZFAS_Umfeldbeleuchtung_Anf 0 "nicht_angefordert" 1 "angefordert" ;
VAL_ 1440 LS_Helligkeit_IR 254 "Init" 255 "Fehler" ;
VAL_ 1440 LS_Helligkeit_FW 1022 "Init" 1023 "Fehler" ;
VAL_ 1440 LS_defekt 0 "OK" 1 "defekt" ;
VAL_ 1440 LS_Verbau 0 "Init" 1 "Lichtsensor_verbaut" ;
VAL_ 1440 RS_Regenmenge 14 "Init" 15 "Fehler" ;
VAL_ 1440 RS_Verbau 0 "Init" 1 "Regensensor verbaut" ;
VAL_ 1440 RS_Verglasung_schliessen 0 "Verglasung nicht schliessen" 1 "Verglasung schliessen" ;
VAL_ 1440 RS_defekt 0 "OK" 1 "defekt" ;
VAL_ 1440 RS_Wischergeschwindigkeit 0 "kein Wischen" 1 "42 Huebe/min" 2 "45 Huebe/min" 3 "48 Huebe/min" 4 "51 Huebe/min" 5 "54 Huebe/min" 6 "57 Huebe/min" 7 "60 Huebe/min" ;
VAL_ 1440 RLS_Vorfeldhelligkeit_Boost 0 "groesser_24413_Lux" 1 "bis_24413_Lux" 2 "bis_22193_Lux" 3 "bis_20176_Lux" 4 "bis_18342_Lux" 5 "bis_16647_Lux" 6 "bis_15158_Lux" 7 "bis_13780_Lux" 8 "bis_12527_Lux" 9 "bis_11388_Lux" 10 "bis_10353_Lux" 11 "bis_9412_Lux" 12 "bis_8556_Lux" 13 "bis_7778_Lux" 14 "bis_7071_Lux" 15 "bis_6428_Lux" ;
VAL_ 2527679790 RTM_Fehlerstatus 0 "Init" 1 "Sending_Failure" 2 "UpdateDownload_Failure" 3 "UpdateInstall_Failure" 4 "UpdateRollbacked" 5 "UpdateRollback_Failure" 6 "BackupBattery_Failure" 7 "RTM_Level3_Warning" ;
VAL_ 2527679790 RTM_IstModus 0 "Standby" 1 "RTM_Operational" 2 "RTM_NonOperational" 3 "UpdateAvailable" 4 "UpdateDownloaded" 5 "UpdateInstalled" 6 "WorkshopMode" 7 "TransportMode" ;
VAL_ 2527679790 RTM_OTA_SignalStrength 0 "No_Connection" 1 "Signal_Strength_OK" 2 "Signal_Strength_Bad" 3 "Reconnection" ;
VAL_ 2527679790 RTM_OTA_InstallProcess 0 "Init" ;
VAL_ 2527679790 RTM_OTA_InstallPrecondition 0 "Init" 1 "Check_Success" 2 "Check_Fail_KL15_on" 3 "Check_Fail_Not_Gear_P" ;
VAL_ 2527679790 RTM_OTA_InstallDuration 31 "Init" ;
VAL_ 2527679790 RTM_OTA_Download_Speed 0 "Init" ;
VAL_ 2527679790 RTM_OTA_Download_Size 254 "Init" 255 "Fehler" ;
VAL_ 2527679790 RTM_OTA_Download_Process 254 "Init" 255 "Fehler" ;
VAL_ 2527679792 MIB_OTA_Comfirmation 0 "No_OTA_Available" 1 "Download_Request_Confirmed" 2 "Download_Error_Confirmed" 3 "Installation_Request_Confirmed" 4 "Installation_Error_Confirmed" 5 "Installation_Postponed" 6 "Reserve" 7 "Reserve" ;
VAL_ 1517 SAD2_Deckel_Lage 0 "Austelllage" 1 "Schiebelage" ;
VAL_ 1517 SAD2_Deckel_normiert 0 "inaktiv" 1 "aktiv" ;
VAL_ 1517 SAD2_Deckel_Thermoschutz 0 "inaktiv" 1 "aktiv" ;
VAL_ 1517 SAD2_Deckel_UEKB_aktiv 0 "inaktiv" 1 "aktiv" ;
VAL_ 1517 SAD2_Deckel_Position 126 "Init" 127 "nicht_normiert" ;
VAL_ 1517 SAD2_Rollo_Lage 0 "Austelllage" 1 "Schiebelage" ;
VAL_ 1517 SAD2_Rollo_Position 126 "Init" 127 "nicht_normiert" ;
VAL_ 1517 SAD2_Rollo_normiert 0 "inaktiv" 1 "aktiv" ;
VAL_ 1517 SAD2_Rollo_Thermoschutz 0 "inaktiv" 1 "aktiv" ;
VAL_ 1517 SAD2_Rollo_UEKB_aktiv 0 "inaktiv" 1 "aktiv" ;
VAL_ 1504 MD1_Position 126 "Init" 127 "nicht_normiert" ;
VAL_ 1504 MD1_Lage 0 "Ausstelllage" 1 "Schiebelage" ;
VAL_ 1504 MD3_Lage 0 "Ausstelllage" 1 "Schiebelage" ;
VAL_ 1504 MRollo_Position 126 "Init" 127 "nicht_normiert" ;
VAL_ 1504 MRollo_Lage 0 "Ausstelllage" 1 "Schiebelage" ;
VAL_ 1504 SAD_normiert 0 "inaktiv" 1 "aktiv" ;
VAL_ 1504 SAD_Thermoschutz 0 "inaktiv" 1 "aktiv" ;
VAL_ 1504 SAD_UEKB_aktiv 0 "inaktiv" 1 "aktiv" ;
VAL_ 1504 Rollo_normiert 0 "inaktiv" 1 "aktiv" ;
VAL_ 1504 Rollo_Thermoschutz 0 "inaktiv" 1 "aktiv" ;
VAL_ 1504 Rollo_UEKB_aktiv 0 "inaktiv" 1 "aktiv" ;
VAL_ 1504 SAD_Taster_Deckel_hi 0 "nicht_betaetigt" 1 "man_sl_zu" 2 "auto_sl_zu" 3 "man_sl_auf" 4 "auto_sl_auf" 5 "man_al_auf" 6 "auto_al_auf" 7 "man_al_zu" 8 "auto_al_zu" 14 "fehler_schalter_haengt" 15 "fehler_schalter_unplausibel" ;
VAL_ 1504 SAD_Taster_Deckel_vo 0 "nicht_betaetigt" 1 "man_sl_zu" 2 "auto_sl_zu" 3 "man_sl_auf" 4 "auto_sl_auf" 5 "man_al_auf" 6 "auto_al_auf" 7 "man_al_zu" 8 "auto_al_zu" 14 "fehler_schalter_haengt" 15 "fehler_schalter_unplausibel" ;
VAL_ 1504 SAD_Taster_Rollo_hi 0 "nicht_betaetigt" 1 "man_zu" 2 "auto_zu" 3 "man_auf" 4 "auto_auf" 6 "fehler_schalter_haengt" 7 "fehler_schalter_unplausibel" ;
VAL_ 1504 SAD_Taster_Rollo_vo 0 "nicht_betaetigt" 1 "man_zu" 2 "auto_zu" 3 "man_auf" 4 "auto_auf" 6 "fehler_schalter_haengt" 7 "fehler_schalter_unplausibel" ;
VAL_ 1504 SAD_Anf_ESC_Zuschaltung 0 "inaktiv" 1 "aktiv" ;
VAL_ 1504 SAD_Text 0 "inaktiv" 1 "aktiv" ;
VAL_ 249 SARA_QBit_Nickwinkel 0 "gueltiger_Wert" 1 "Ersatz_Init_oder_Fehlerwert" ;
VAL_ 249 SARA_QBit_Wankwinkel 0 "gueltiger_Wert" 1 "Ersatz_Init_oder_Fehlerwert" ;
VAL_ 249 SARA_Nickwinkel 8191 "Init" ;
VAL_ 249 SARA_Wankwinkel 8191 "Init" ;
VAL_ 378 SARA_Accel_Y_010_02 0 "nicht_verbaut" 65535 "Fehler" ;
VAL_ 378 SARA_Accel_X_010_02 0 "nicht_verbaut" 65535 "Fehler" ;
VAL_ 378 SARA_Omega_Z_010_02 0 "nicht_verbaut" 65535 "Fehler" ;
VAL_ 378 SARA_CF_Accel_X_010_02 0 "gueltiger_Wert" 1 "nicht_belegt" 2 "nicht_belegt" 3 "temporaerer_Fehler" 4 "Init" 5 "Sensor_nicht_verbaut_Signal_nicht_berrechnet" 6 "Sensor_nicht_abgeglichen" 7 "Sensor_defekt" ;
VAL_ 378 SARA_CF_Accel_Y_010_02 0 "gueltiger_Wert" 1 "nicht_belegt" 2 "nicht_belegt" 3 "temporaerer_Fehler" 4 "Init" 5 "Sensor_nicht_verbaut_Signal_nicht_berrechnet" 6 "Sensor_nicht_abgeglichen" 7 "Sensor_defekt" ;
VAL_ 378 SARA_CF_Omega_Z_010_02 0 "gueltiger_Wert" 1 "nicht_belegt" 2 "nicht_belegt" 3 "temporaerer_Fehler" 4 "Init" 5 "Sensor_nicht_verbaut_Signal_nicht_berrechnet" 6 "Sensor_nicht_abgeglichen" 7 "Sensor_defekt" ;
VAL_ 424 SARA_Accel_X_r 0 "nicht_verbaut" 8191 "Fehler" ;
VAL_ 424 SARA_Accel_Y_r 0 "nicht_verbaut" 8191 "Fehler" ;
VAL_ 424 SARA_Omega_Z_r 0 "nicht_verbaut" 8191 "Fehler" ;
VAL_ 424 SARA_CF_Accel_X_r 0 "gueltiger_Wert" 1 "nicht_belegt" 2 "nicht_belegt" 3 "temporaerer_Fehler" 4 "Init" 5 "Sensor_nicht_verbaut_Signal_nicht_berrechnet" 6 "Sensor_nicht_abgeglichen" 7 "Sensor_defekt" ;
VAL_ 424 SARA_CF_Accel_Y_r 0 "gueltiger_Wert" 1 "nicht_belegt" 2 "nicht_belegt" 3 "temporaerer_Fehler" 4 "Init" 5 "Sensor_nicht_verbaut_Signal_nicht_berrechnet" 6 "Sensor_nicht_abgeglichen" 7 "Sensor_defekt" ;
VAL_ 424 SARA_CF_Omega_Z_r 0 "gueltiger_Wert" 1 "nicht_belegt" 2 "nicht_belegt" 3 "temporaerer_Fehler" 4 "Init" 5 "Sensor_nicht_verbaut_Signal_nicht_berrechnet" 6 "Sensor_nicht_abgeglichen" 7 "Sensor_defekt" ;
VAL_ 1011 SCR_Sent_Levelsignal_Status 0 "kein_Wert_ermittelbar" 1 "Aggregatszustand_Mischphase" 2 "Aggregatszustand_Eis" 3 "Aggregatszustand_Fluessig" 6 "Fehler" 7 "Init" ;
VAL_ 1011 SCR_QBit_Level_Aktivtank_02 0 "gueltiger_Wert" 1 "Ersatz_Init_oder_Fehlerwert" ;
VAL_ 1011 SCR_Level_ReadAbove 0 "Readabove aus" 1 "Readabove aktiv" ;
VAL_ 1011 SCR_Dosierpumpe_Drehzahl 2046 "Init" 2047 "Fehler" ;
VAL_ 1011 SCR_Druck 1021 "nicht_verbaut" 1022 "Init" 1023 "Fehler" ;
VAL_ 1011 SCR_Level_Aktivtank 1021 "nicht_verbaut" 1022 "Init" 1023 "Fehler" ;
VAL_ 1011 SCR_Sent_Level_Aktivtank 1022 "Init" ;
VAL_ 1507 SCR_Heizkreis_3_Strom 253 "nicht_verbaut" 254 "Init" 255 "Fehler" ;
VAL_ 1507 SCR_Guetesensor 1021 "nicht_verbaut" 1022 "Init" 1023 "Fehler" ;
VAL_ 1507 SCR_Temp_Aktivtank 254 "Init" 255 "Fehler" ;
VAL_ 1507 SCR_Temp_Passivtank 253 "nicht_verbaut" 254 "Init" 255 "Fehler" ;
VAL_ 1507 SCR_Leitungsheizung_Strom 254 "Init" 255 "Fehler" ;
VAL_ 1507 SCR_Transferpumpe_Strom 253 "nicht_verbaut" 254 "Init" 255 "Fehler" ;
VAL_ 1507 SCR_Tankheizung_Strom 254 "Init" 255 "Fehler" ;
VAL_ 1526 SCR_Level_Aktivtank_OOR4Quality 0 "Füllstand i.O. für Qualitätsberechnung" 1 "Füllstand zu niedrig für Qualitätsberechnung" ;
VAL_ 1526 SCR_Level_Aktivtank_OOR_minus 0 "Level erfassbar" 1 "Level zu niedrig" ;
VAL_ 1526 SCR_Sent_1_Signalstatus 0 "kein Fehler" 1 "Sent Signal unplausibel" 2 "Sent Signal TimeOut" 3 "Diagnose noch nicht beendet" ;
VAL_ 1526 SCR_Sent_1_elektrischer_Status 0 "kein Fehler" 1 "KS- " 2 "KS+" 8 "KS_Versorgung_Sensoren" 11 "KS_Heizkreis_1" 12 "KS_Heizkreis_2" 13 "KS_Heizkreis_3" 14 "KS_Pumpe" 15 "Diagnose noch nicht beendet" ;
VAL_ 1526 SCR_Sent_Levelsensor 0 "kein Fehler" 1 "Levelsensor defekt" 2 "Sensortemperatur zu hoch" 3 "Sensorversorgung OOR" 5 "Levelsignal OOR+" 6 "Levelsignal OOR-" 7 "Diagnose noch nicht beendet" ;
VAL_ 1526 SCR_Sent_Qualitaetssensor 0 "kein Fehler" 1 "Qualitätssensor defekt" 2 "Fremdlicht" 3 "Sensorstoerung" 5 "OOR+" 6 "OOR-" 7 "Diagnose noch nicht beendet" ;
VAL_ 1526 SCR_Sent_Temperatursensor 0 "kein Fehler" 1 "Temperatursensor defekt" 5 "OOR+" 6 "OOR-" 7 "Diagnose noch nicht beendet" ;
VAL_ 1526 SCR_DEF_Qualitaet_Medium 0 "Mediumkonzentration ermittelbar" 1 "Mediumkonzentration nicht ermittelbar" ;
VAL_ 1526 SCR_QBit_Qualitaet 0 "gueltiger_Wert" 1 "Ersatz_Init_oder_Fehlerwert" ;
VAL_ 1526 SCR_Sent_2_Signalstatus 0 "kein_Fehler" 1 "Sent_Signal_unplausibel" 2 "Sent_Signal_TimeOut" 3 "Diagnose_noch_nicht_beendet" ;
VAL_ 1526 SCR_Temp_DEF2_Sensor_Status 0 "kein_Fehler" 1 "Temperatursensor_defekt" 5 "OOR+" 6 "OOR-" 7 "Diagnose_noch_nicht_beendet" ;
VAL_ 1526 SCR_Sent_2_elektrischer_Status 0 "kein_Fehler" 1 "KS- " 2 "KS+" 8 "KS_Versorgung_Sensoren" 11 "KS_Heizkreis_1" 12 "KS_Heizkreis_2" 13 "KS_Heizkreis_3" 14 "KS_Pumpe" 15 "Diagnose_noch_nicht_beendet" ;
VAL_ 1526 SCR_HAL_Sensorik_Status 0 "kein_Fehler" 1 "KS-" 2 "KS+" 3 "OC" 4 "OOR+" 5 "OOR-" 6 "RC+" 7 "RC-" 8 "KSplus_Unterbrechung" 9 "KSminus_Unterbrechung" 15 "Diagnose_noch_nicht_beendet" ;
VAL_ 1526 SCR_Steuergeraet_Heizung_Status 0 "kein_Fehler" 1 "Endstufe_Tankheizung_ueberhitzt" 2 "Endstufe_Leitungsheizung_ueberhitzt" 3 "Diagnose_noch_nicht_beendet" ;
VAL_ 1526 SCR_Steuergeraet_Pumpe_Status 0 "kein_Fehler" 1 "Endstufe_Pumpe_ueberhitzt" 2 "Pumpe_blockiert" 3 "Diagnose_noch_nicht_beendet" ;
VAL_ 1526 SCR_Steuergeraet_Relais_Status 0 "kein_Fehler" 1 "KS+ (Ausgang Leistungsrelais) " 2 "KS-/OC (Ausgang Leistungsrelais)" 3 "Diagnose_noch_nicht_beendet" ;
VAL_ 1526 SCR_Steuergeraet_Bus_Status 0 "kein_Fehler" 1 "Bus_Kommunikation_Fehler" 2 "Bus_Kommunikation_Stoerung_(temporaer)" 3 "Diagnose_noch_nicht_beendet" ;
VAL_ 1526 SCR_ECU_Datensatz_Status 0 "kein_Fehler" 1 "ungueltiger_Datensatz" 2 "unplausibeler_Datensatz" 3 "Diagnose_noch_nicht_beendet" ;
VAL_ 1526 SCR_Steuergeraet_Defekt_Status 0 "kein_Fehler" 1 "Steuergeraet_defekt" 2 "Steuergeraet_Stoerung_(temporaer)" 3 "Diagnose_noch_nicht_beendet" ;
VAL_ 873 SDF2_Pos_Segment_ID 0 "KeineSegmentinformation" 1 "Fehlerwert" ;
VAL_ 873 SDF2_Pos_Standort_Eindeutig 0 "mehrdeutiger_Standort" 1 "eindeutiger_Standort" ;
VAL_ 873 SDF2_Pos_Distanz_Rampe_rechts 62 "keine" 63 "Init" ;
VAL_ 873 SDF2_Pos_Spurtype 0 "Hauptspur" 1 "Ausfahrt_Rampe_links" 2 "Ausfahrt_Rampe_rechts" 3 "HOV_Spur" 4 "Expressspur" 5 "Nur_Ausfahrt_links" 6 "Nur_Ausfahrt_rechts" 7 "Kombinierte_Ausfahrt_links" 8 "Kombinierte_Ausfahrt_rechts" 9 "Nur_Auffahrt_links" 10 "Nur_Auffahrt_rechts" 11 "Kombinierte_Auffahrt_links" 12 "Kombinierte_Auffahrt_rechts" 13 "Auffahrt_Rampe_links" 14 "Auffahrt_Rampe_rechts" 30 "Unbekannt" 31 "Init" ;
VAL_ 873 SDF2_Pos_Distanz_Rampe_links 62 "keine" 63 "Init" ;
VAL_ 873 SDF2_Pos_AnzRampenRechts 7 "Init" ;
VAL_ 873 SDF2_Pos_AnzRampenLinks 7 "Init" ;
VAL_ 873 SDF2_Pos_Fehler_Laengsrichtung 0 "Init" 1 "kleiner_2m" 2 "kleiner_5m" 3 "kleiner_10m" 4 "kleiner_20m" 5 "kleiner_50m" 6 "groesser_50m" 7 "offroad" ;
VAL_ 873 SDF2_Pos_AnzHauptspuren 15 "Init" ;
VAL_ 873 SDF2_Pos_Spurnummer 0 "Spur_minus_5" 1 "Spur_minus_4" 2 "Spur_minus_3" 3 "Spur_minus_2" 4 "Spur_minus_1" 5 "Standstreifen" 6 "Spur_1" 7 "Spur_2" 8 "Spur_3" 9 "Spur_4" 10 "Spur_5" 11 "Spur_6" 12 "Spur_7" 13 "Spur_8" 14 "Spur_9" 15 "Init" ;
VAL_ 873 SDF2_Pos_GueteZuordnung 15 "Init" ;
VAL_ 2589283634 SM_LAPP_Demo_Objekt_01_Anf 0 "nicht_angefordert" 1 "angefordert" ;
VAL_ 2589283634 SM_LAPP_Demo_Objekt_02_Anf 0 "nicht_angefordert" 1 "angefordert" ;
VAL_ 2589283634 SM_LAPP_Demo_Autobahnmodus_Anf 0 "nicht_angefordert" 1 "angefordert" ;
VAL_ 2589283634 SM_LAPP_Aussenlicht_aktiv 0 "inaktiv" 1 "aktiv" ;
VAL_ 2589283634 SM_LAPP_Verbindungsstatus 0 "nicht_angefordert" 1 "angefordert" ;
VAL_ 2589283634 SM_LAPP_Demo_Schildentbl_01_Anf 0 "nicht_angefordert" 1 "angefordert" ;
VAL_ 2589283634 SM_LAPP_Demo_Schildentbl_02_Anf 0 "nicht_angefordert" 1 "angefordert" ;
VAL_ 2589283634 SM_LAPP_Demo_DKL_Anf 0 "nicht_angefordert" 1 "angefordert" ;
VAL_ 2589283634 SM_LAPP_Demo_Einschalteffekt_Anf 0 "nicht_angefordert" 1 "angefordert" ;
VAL_ 2589283634 SM_LAPP_Demo_FL_Anf 0 "nicht_angefordert" 1 "angefordert" ;
VAL_ 2589283634 SM_LAPP_Demo_MaLi_Anf 0 "nicht_angefordert" 1 "angefordert" ;
VAL_ 2589283634 SM_LAPP_Demo_ABBL_Anf 0 "nicht_angefordert" 1 "angefordert" ;
VAL_ 2527679657 SM_LAPP_Demo_AbsAss_Anf 0 "nicht_angefordert" 1 "angefordert" ;
VAL_ 2527679657 SM_LAPP_Demo_SL_Signatur_Anf 0 "Init" 1 "Signatur_1" 2 "Signatur_2" 3 "Signatur_3" 4 "Signatur_4" 5 "Signatur_5" 6 "Signatur_6" 7 "Signatur_7" 8 "Signatur_8" 9 "Signatur_9" 10 "Signatur_10" 11 "Signatur_11" 12 "Signatur_12" 13 "Signatur_13" 14 "Signatur_14" 15 "Signatur_15" ;
VAL_ 2527679657 SM_LAPP_Demo_Variante 0 "Variante_0" 1 "Variante_1" 2 "Variante_2" 3 "Variante_3" 4 "Variante_4" 5 "Variante_5" ;
VAL_ 2527679657 SM_LAPP_Demo_RouLi_Anf 0 "nicht_angefordert" 1 "angefordert" ;
VAL_ 2527679657 SM_LAPP_Demo_PreSAss_Anf 0 "nicht_angefordert" 1 "angefordert" ;
VAL_ 2527679657 SM_LAPP_Demo_advLH_F01_Anf 0 "nicht_angefordert" 1 "angefordert" ;
VAL_ 2527679657 SM_LAPP_Demo_AbbiegeWa_Anf 0 "nicht_angefordert" 1 "angefordert" ;
VAL_ 2527679657 SM_LAPP_Demo_CH_H01_Anf 0 "nicht_angefordert" 1 "angefordert" ;
VAL_ 2527679657 SM_LAPP_Demo_Stufe 0 "Stufe_0" 1 "Stufe_1" 2 "Stufe_2" 3 "Stufe_3" ;
VAL_ 2527679657 SM_LAPP_Demo_SL_Anf 0 "nicht_angefordert" 1 "angefordert" ;
VAL_ 2527679657 SM_LAPP_Demo_SitLi_Anf 0 "nicht_angefordert" 1 "angefordert" ;
VAL_ 2527679657 SM_LAPP_Demo_BauLi_Anf 0 "nicht_angefordert" 1 "angefordert" ;
VAL_ 2527679657 SM_LAPP_Demo_advCH_F01_Anf 0 "nicht_angefordert" 1 "angefordert" ;
VAL_ 2527679657 SM_LAPP_Demo_LH_F01_Anf 0 "nicht_angefordert" ;
VAL_ 2527679657 SM_LAPP_Demo_AccAss_Anf 0 "nicht_angefordert" 1 "angefordert" ;
VAL_ 2527679657 SM_LAPP_Demo_SpuLi_Anf 0 "nicht_angefordert" 1 "angefordert" ;
VAL_ 2527679657 SM_LAPP_Demo_TraLi_Anf 0 "nicht_angefordert" 1 "angefordert" ;
VAL_ 2527679657 SM_LAPP_Demo_CH_F01_Anf 0 "nicht_angefordert" ;
VAL_ 2527679657 SM_LAPP_Demo_LH_H01_Anf 0 "nicht_angefordert" 1 "angefordert" ;
VAL_ 2527679657 SM_LAPP_Demo_EffAss_Anf 0 "nicht_angefordert" 1 "angefordert" ;
VAL_ 2527679657 SM_LAPP_Demo_BeAss_Anf 0 "nicht_angefordert" 1 "angefordert" ;
VAL_ 201 SM_Parken_Touch_PosX 0 "X_Pos_0" 1 "X_Pos_1" 2 "X_Pos_2" 3 "X_Pos_3" 4 "X_Pos_4" 5 "X_Pos_5" 6 "X_Pos_6" 7 "X_Pos_7" ;
VAL_ 201 SM_Parken_Touch_PosY 0 "Y_Pos_0" 1 "Y_Pos_1" 2 "Y_Pos_2" 3 "Y_Pos_3" 4 "Y_Pos_4" 5 "Y_Pos_5" 6 "Y_Pos_6" 7 "Y_Pos_7" 8 "Y_Pos_8" 9 "Y_Pos_9" 10 "Y_Pos_10" 11 "Y_Pos_11" 12 "Y_Pos_12" 13 "Y_Pos_13" 14 "Y_Pos_14" 15 "Y_Pos_15" 16 "Y_Pos_16" 17 "Y_Pos_17" 18 "Y_Pos_18" 19 "Y_Pos_19" 20 "Y_Pos_20" 21 "Y_Pos_21" 22 "Y_Pos_22" 23 "Y_Pos_23" 24 "Y_Pos_24" 25 "Y_Pos_25" 26 "Y_Pos_26" 27 "Y_Pos_27" 28 "Y_Pos_28" 29 "Y_Pos_29" 30 "Y_Pos_30" 31 "Keine_Eingabe_oder_Init" ;
VAL_ 201 SM_ARA_Gangwahl 0 "keine_Anforderung" 1 "P" 2 "R" 3 "N" 4 "D" ;
VAL_ 201 SM_Fehlerstatus 0 "Kein_Fehler_erkannt_oder_Init" 1 "Fehler_erkannt" ;
VAL_ 201 SM_ARA_Start 0 "No_Request" 1 "Request" ;
VAL_ 201 SM_ARA_Trajektorienmodus 0 "Trajektorienmodus_inaktiv" 1 "Trajektorienmodus_aktiv" ;
VAL_ 201 SM_AFR_Verbindungsstatus 0 "Not_Connected" 1 "Connected" ;
VAL_ 201 SM_Anlernstatus 0 "Keine_Geraete_gespeichert" 1 "Geraete_gespeichert" ;
VAL_ 201 SM_Parken_Motorstart_Anf 0 "No_Request" 1 "Request" ;
VAL_ 201 SM_AFR_Standfkt_Anf 0 "Keine_Anforderung" 1 "Bereitschaft_herstellen_bzw_beibehalten" 2 "Fahrzeug_anheben_ausfuehren" 3 "Fahrzeug_absenken_ausfuehren" 4 "Standfunktion_3_ausfuehren" 5 "Standfunktion_4_ausfuehren" 6 "Standfunktion_5_ausfuehren" 7 "Standfunktion_6_ausfuehren" ;
VAL_ 201 SM_ARA_Nothalt 0 "Kein_Nothalt_angefordert" 1 "Nothalt_angefordert" ;
VAL_ 201 SM_App_Sperrzustand 0 "Undefined" 1 "Button_not_pressed" 2 "Button_pressed" 3 "Car_Wakeup" ;
VAL_ 201 SM_Parken_Manoever 0 "Init" 1 "Einparken" 2 "Ausparken" ;
VAL_ 201 SM_Parken_Szenario 0 "Init" 1 "Parallel" 2 "Perpendicular" 3 "Garage" 4 "Basic" 5 "Custom_Drive" 6 "TPA" 7 "AAA" ;
VAL_ 201 SM_Parken_Seite 0 "Init" 1 "Left" 2 "Right" 3 "Straight" ;
VAL_ 201 SM_Parken_Richtung 0 "Init" 1 "Forward" 2 "Backward" ;
VAL_ 201 SM_ARA_Status_Steuersignal 0 "Not_Ready" 1 "Ready" ;
VAL_ 201 SM_ARA_Knickwinkel_Soll 254 "Init" 255 "Fehler" ;
VAL_ 201 SM_Parken_Verbindungsstatus 0 "Not_Connected" 1 "Connected_ID_1" 2 "Connected_ID_2" 3 "Connected_ID_3" 4 "Connected_ID_4" 5 "Connected_ID_5" 6 "Connected_ID_6" 7 "Connected_ID_7" 8 "Connected_ID_8" 9 "Connected_ID_9" 10 "Connected_ID_10" 11 "Connected_ID_11" 12 "Connected_ID_12" 13 "Connected_ID_13" 14 "Connected_ID_14" 15 "Connected_ID_15" ;
VAL_ 201 SM_Parken_Kommando 0 "Stop" 1 "Drive_1" 2 "Drive_2" 3 "Custom_Finish" ;
VAL_ 201 SM_Parken_Kommando_invers 0 "Custom_Finish" 1 "Drive_2" 2 "Drive_1" 3 "Stop" ;
VAL_ 2527679651 SM_Parken_blinken 0 "aus" 1 "links" 2 "rechts" 3 "warnblinken" ;
VAL_ 2527679651 SM_Parken_Hupe_Anf 0 "Keine_Anforderung" 1 "Hupen" ;
VAL_ 2527679651 SM_Parken_UGDO_Anf 0 "Keine_Anforderung" 1 "Garage_1" 2 "Garage_2" 3 "Garage_3" 4 "Garage_4" 5 "Garage_5" 6 "Garage_6" 7 "Garage_7" 8 "Garage_8" 9 "Garage_9" 10 "Garage_10" 11 "Garage_11" 12 "Garage_12" 13 "Garage_13" 14 "Garage_14" 15 "Garage_15" ;
VAL_ 2527679651 SM_Parken_UGDO_Aktion 0 "Keine_Anforderung" 1 "Garage_oeffnen_oder_toggeln" 2 "Garage_schliessen" 3 "Garage_stoppen" 4 "Status_Anfrage" ;
VAL_ 2527679651 SM_Parken_Komfortschliessen_Anf 0 "Keine_Anforderung" 1 "Komfortschliessen" ;
VAL_ 980 BH_Blinker_li 0 "nicht_betaetigt" 1 "Blinkerhebel_Pos_li_betaetigt" ;
VAL_ 980 BH_Blinker_re 0 "nicht_betaetigt" 1 "Blinkerhebel_Pos_re_betaetigt" ;
VAL_ 980 BH_Lichthupe 0 "nicht_betaetigt" 1 "Blinkerhebel in Richtung Lichthupe betaetigt" ;
VAL_ 980 BH_Fernlicht 0 "nicht_betaetigt" 1 "Blinkerhebel_in_Richtung_Fernlicht_betaetigt" ;
VAL_ 980 WH_Tipwischen 0 "nicht_betaetigt" 1 "betaetigt" ;
VAL_ 980 WH_Intervall 0 "aus" 1 "Wischerhebel in Stellung Intervall" ;
VAL_ 980 WH_WischerStufe1 0 "aus" 1 "Wischerhebel in Stufe Wischen 1" ;
VAL_ 980 WH_WischerStufe2 0 "aus" 1 "Wischerhebel in Stufe Wischen 2" ;
VAL_ 980 WH_Frontwaschen 0 "aus" 1 "Wischerhebel in Stellung Wisch Wasch vorne" ;
VAL_ 980 WH_Heckintervall 0 "nicht_betaetigt" 1 "Wischerhebel in Stellung Heckintervall" ;
VAL_ 980 WH_Heckwaschen 0 "nicht_betaetigt" 1 "Wischerhebel in Stellung Wisch Wasch hinten" ;
VAL_ 980 WH_Intervallstufen 0 "Init / Default" 1 "Intervallstufe 1" 5 "Intervallstufe 2" 9 "Intervallstufe 3" 13 "Intervallstufe 4" 15 "Fehler" ;
VAL_ 980 FAS_Taster 0 "nicht_betaetigt" 1 "betaetigt" ;
VAL_ 980 FAS_Taster_Fehler 0 "kein_Fehler" 1 "Fehler" ;
VAL_ 980 SMLS_Hupe 0 "nicht_betaetigt" 1 "Hupe_gedrueckt" ;
VAL_ 980 LRH_On_Off 0 "LRH_aus__keine Anzeige" 1 "LRH_aus" 2 "LRH_ein" 3 "Fehler" ;
VAL_ 980 LRH_aktiv 0 "inaktiv" 1 "aktiv" ;
VAL_ 980 SMLS_P_verriegelt_plausibel 0 "unplausibel" 1 "plausibel" ;
VAL_ 980 WH_SRA 0 "SRA_Aus" 1 "SRA_Ein" ;
VAL_ 980 WH_Wischer_Fehler 0 "kein_Fehler" 1 "Fehler" ;
VAL_ 980 BH_Blinker_Fehler 0 "kein_Fehler" 1 "Fehler" ;
VAL_ 980 SMLS_PTT 0 "nicht_betaetigt" 1 "PTT_gedrueckt" ;
VAL_ 980 WH_Tipwischen_lang 0 "nicht_betaetigt" 1 "betaetigt" ;
VAL_ 1467 SoSe_SunInt_2D_Li 254 "Init" 255 "Fehler" ;
VAL_ 1467 SoSe_SunInt_2D_Re 254 "Init" 255 "Fehler" ;
VAL_ 1710 SP_FT_oben 0 "nicht_betaetigt" 1 "betaetigt" ;
VAL_ 1710 SP_FT_unten 0 "nicht_betaetigt" 1 "betaetigt" ;
VAL_ 1710 SP_FT_links 0 "nicht_betaetigt" 1 "betaetigt" ;
VAL_ 1710 SP_FT_rechts 0 "nicht_betaetigt" 1 "betaetigt" ;
VAL_ 1710 SP_BT_oben 0 "nicht_betaetigt" 1 "betaetigt" ;
VAL_ 1710 SP_BT_unten 0 "nicht_betaetigt" 1 "betaetigt" ;
VAL_ 1710 SP_BT_links 0 "nicht_betaetigt" 1 "betaetigt" ;
VAL_ 1710 SP_BT_rechts 0 "nicht_betaetigt" 1 "betaetigt" ;
VAL_ 1710 SP_abklappen 0 "Spiegel_abklappen_nicht_aktiv" 1 "Spiegel_abklappen_aktiv" ;
VAL_ 1710 SP_anklappen 0 "Spiegle_anklappen_nicht_aktiv" 1 "Spiegel_anklappen_aktiv" ;
VAL_ 1710 SP_normieren 0 "Spiegel_nicht_normiert" 1 "Spiegel_normiert" ;
VAL_ 1710 SP_Hzg_Taster 0 "nicht_betaetigt" 1 "betaetigt" ;
VAL_ 1710 SP_S_oben 1 "Spiegelschalter in Stellung oben" ;
VAL_ 1710 SP_S_unten 1 "Spiegelschalter in Stellung unten" ;
VAL_ 1710 SP_S_links 1 "Spiegelschalter in Stellung links" ;
VAL_ 1710 SP_S_rechts 1 "Spiegelschalter in Stellung rechts" ;
VAL_ 1710 SP_Auswahl_li 1 "Spiegelschalter in Stellung Auswahl links" ;
VAL_ 1710 SP_Auswahl_re 1 "Spiegelschalter in Stellung Auswahl rechts" ;
VAL_ 1710 SP_ARA_Status 0 "TSG nicht im ARA-Modus" 1 "TSG im ARA-Modus" ;
VAL_ 1710 SP_S_Klappen 1 "Spiegelschalter in Stellung Klappen" ;
VAL_ 1710 SP_Verstellschalter_Fehler 0 "kein_Fehler" 1 "Fehler" ;
